VERSION "HNNBNNNYNNNNNNNNNNNNNNNNNNNNNNNNNNNNNNNNNN/4/%%%/4/'%**4NNN///"

NS_ :

BS_:

BU_: BAP_Tester BCM Gateway_Max TSGGen3_BFS TSGGen3_FS TSGGen3_HBFS TSGGen3_HFS WLC_01_CFD

BO_ 1716 VIN_01: 8 BCM
 SG_ VIN_01_MUX M  : 0|2@1+ (1,0) [0|3] ""  Gateway_Max,TSGGen3_BFS,TSGGen3_FS,TSGGen3_HBFS,TSGGen3_HFS
 SG_ KS_Geheimnis_1 m0  : 8|8@1+ (1,0) [0|255] ""  Gateway_Max
 SG_ VIN_4 m1  : 8|8@1+ (1,0) [0|255] ""  Gateway_Max,TSGGen3_BFS,TSGGen3_FS,TSGGen3_HBFS,TSGGen3_HFS,WLC_01_CFD
 SG_ VIN_11 m2  : 8|8@1+ (1,0) [0|255] ""  Gateway_Max,TSGGen3_BFS,TSGGen3_FS,TSGGen3_HBFS,TSGGen3_HFS,WLC_01_CFD
 SG_ KS_Geheimnis_2 m0  : 16|8@1+ (1,0) [0|255] ""  Gateway_Max
 SG_ VIN_5 m1  : 16|8@1+ (1,0) [0|255] ""  Gateway_Max,TSGGen3_BFS,TSGGen3_FS,TSGGen3_HBFS,TSGGen3_HFS,WLC_01_CFD
 SG_ VIN_12 m2  : 16|8@1+ (1,0) [0|255] ""  Gateway_Max,TSGGen3_BFS,TSGGen3_FS,TSGGen3_HBFS,TSGGen3_HFS,WLC_01_CFD
 SG_ KS_Geheimnis_3 m0  : 24|8@1+ (1,0) [0|255] ""  Gateway_Max
 SG_ VIN_6 m1  : 24|8@1+ (1,0) [0|255] ""  Gateway_Max,TSGGen3_BFS,TSGGen3_FS,TSGGen3_HBFS,TSGGen3_HFS,WLC_01_CFD
 SG_ VIN_13 m2  : 24|8@1+ (1,0) [0|255] ""  Gateway_Max,TSGGen3_BFS,TSGGen3_FS,TSGGen3_HBFS,TSGGen3_HFS,WLC_01_CFD
 SG_ KS_Geheimnis_4 m0  : 32|8@1+ (1,0) [0|255] ""  Gateway_Max
 SG_ VIN_7 m1  : 32|8@1+ (1,0) [0|255] ""  Gateway_Max,TSGGen3_BFS,TSGGen3_FS,TSGGen3_HBFS,TSGGen3_HFS,WLC_01_CFD
 SG_ VIN_14 m2  : 32|8@1+ (1,0) [0|255] ""  Gateway_Max,TSGGen3_BFS,TSGGen3_FS,TSGGen3_HBFS,TSGGen3_HFS,WLC_01_CFD
 SG_ VIN_1 m0  : 40|8@1+ (1,0) [0|255] ""  Gateway_Max,TSGGen3_BFS,TSGGen3_FS,TSGGen3_HBFS,TSGGen3_HFS,WLC_01_CFD
 SG_ VIN_8 m1  : 40|8@1+ (1,0) [0|255] ""  Gateway_Max,TSGGen3_BFS,TSGGen3_FS,TSGGen3_HBFS,TSGGen3_HFS,WLC_01_CFD
 SG_ VIN_15 m2  : 40|8@1+ (1,0) [0|255] ""  Gateway_Max,TSGGen3_BFS,TSGGen3_FS,TSGGen3_HBFS,TSGGen3_HFS,WLC_01_CFD
 SG_ VIN_2 m0  : 48|8@1+ (1,0) [0|255] ""  Gateway_Max,TSGGen3_BFS,TSGGen3_FS,TSGGen3_HBFS,TSGGen3_HFS,WLC_01_CFD
 SG_ VIN_9 m1  : 48|8@1+ (1,0) [0|255] ""  Gateway_Max,TSGGen3_BFS,TSGGen3_FS,TSGGen3_HBFS,TSGGen3_HFS,WLC_01_CFD
 SG_ VIN_16 m2  : 48|8@1+ (1,0) [0|255] ""  Gateway_Max,TSGGen3_BFS,TSGGen3_FS,TSGGen3_HBFS,TSGGen3_HFS,WLC_01_CFD
 SG_ VIN_3 m0  : 56|8@1+ (1,0) [0|255] ""  Gateway_Max,TSGGen3_BFS,TSGGen3_FS,TSGGen3_HBFS,TSGGen3_HFS,WLC_01_CFD
 SG_ VIN_10 m1  : 56|8@1+ (1,0) [0|255] ""  Gateway_Max,TSGGen3_BFS,TSGGen3_FS,TSGGen3_HBFS,TSGGen3_HFS,WLC_01_CFD
 SG_ VIN_17 m2  : 56|8@1+ (1,0) [0|255] ""  Gateway_Max,TSGGen3_BFS,TSGGen3_FS,TSGGen3_HBFS,TSGGen3_HFS,WLC_01_CFD

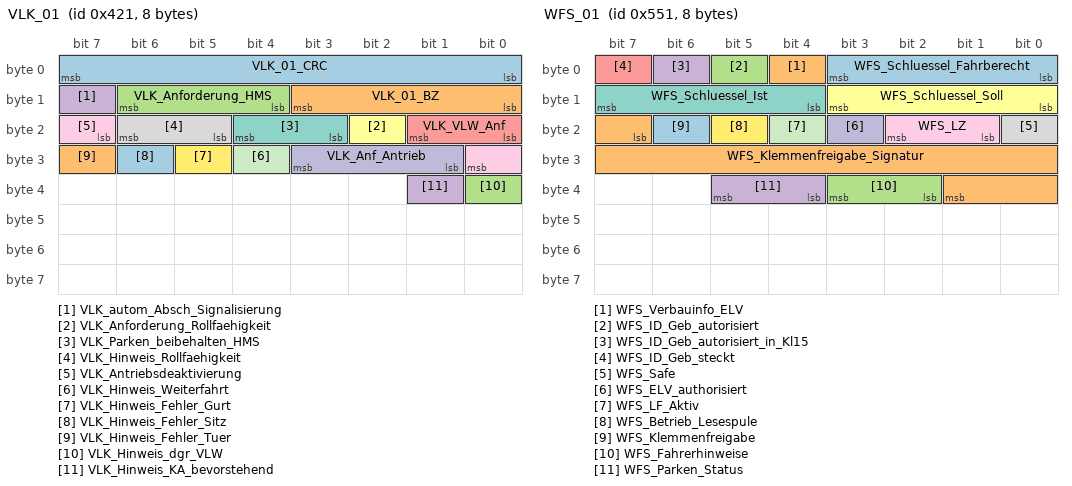
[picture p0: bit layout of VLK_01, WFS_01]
BO_ 1057 VLK_01: 8 BCM
 SG_ VLK_01_CRC : 0|8@1+ (1,0) [0|255] ""  Gateway_Max
 SG_ VLK_01_BZ : 8|4@1+ (1,0) [0|15] ""  Gateway_Max
 SG_ VLK_Anforderung_HMS : 12|3@1+ (1.0,0.0) [0.0|7] ""  Gateway_Max
 SG_ VLK_autom_Absch_Signalisierung : 15|1@1+ (1.0,0.0) [0.0|1] ""  Gateway_Max
 SG_ VLK_VLW_Anf : 16|2@1+ (1.0,0.0) [0.0|3] ""  Gateway_Max
 SG_ VLK_Anforderung_Rollfaehigkeit : 18|1@1+ (1.0,0.0) [0.0|1] ""  Gateway_Max
 SG_ VLK_Parken_beibehalten_HMS : 19|2@1+ (1.0,0.0) [0.0|3] ""  Gateway_Max
 SG_ VLK_Hinweis_Rollfaehigkeit : 21|2@1+ (1.0,0.0) [0.0|3] ""  Gateway_Max
 SG_ VLK_Antriebsdeaktivierung : 23|2@1+ (1.0,0.0) [0.0|3] ""  Gateway_Max
 SG_ VLK_Anf_Antrieb : 25|3@1+ (1.0,0.0) [0.0|7] ""  Gateway_Max
 SG_ VLK_Hinweis_Weiterfahrt : 28|1@1+ (1.0,0.0) [0.0|1] ""  Gateway_Max
 SG_ VLK_Hinweis_Fehler_Gurt : 29|1@1+ (1.0,0.0) [0.0|1] ""  Gateway_Max
 SG_ VLK_Hinweis_Fehler_Sitz : 30|1@1+ (1.0,0.0) [0.0|1] ""  Gateway_Max
 SG_ VLK_Hinweis_Fehler_Tuer : 31|1@1+ (1.0,0.0) [0.0|1] ""  Gateway_Max
 SG_ VLK_Hinweis_dgr_VLW : 32|1@1+ (1.0,0.0) [0.0|1] ""  Gateway_Max
 SG_ VLK_Hinweis_KA_bevorstehend : 33|1@1+ (1.0,0.0) [0.0|1] ""  Gateway_Max

BO_ 313 VMM_02_Auth: 32 Gateway_Max
 SG_ VMM_02_CRC : 0|8@1+ (1,0) [0|255] ""  BCM
 SG_ VMM_02_BZ : 8|4@1+ (1,0) [0|15] ""  BCM
 SG_ VZM_aktiver_Basisservice : 12|3@1+ (1.0,0.0) [0.0|7] ""  Vector__XXX
 SG_ VZM_Anhalteweg_nicht_verfuegbar : 15|1@1+ (1.0,0.0) [0.0|1] ""  Vector__XXX
 SG_ VZM_Fahrer_bremst : 16|1@1+ (1.0,0.0) [0.0|1] ""  BCM
 SG_ VZM_QBit_Fahrer_bremst : 17|1@1+ (1.0,0.0) [0.0|1] ""  BCM
 SG_ VMM_MKB_codiert : 18|1@1+ (1.0,0.0) [0.0|1] ""  Vector__XXX
 SG_ VMM_Inkonsistenz_EBKV : 19|1@1+ (1.0,0.0) [0.0|1] ""  Vector__XXX
 SG_ VMM_Notstopp_Status : 20|3@1+ (1.0,0.0) [0.0|7] ""  BCM
 SG_ VZM_Warnruck_nicht_verfuegbar : 23|1@1+ (1.0,0.0) [0.0|1] ""  Vector__XXX
 SG_ VZM_Warnruckeln_nicht_verfuegbar : 24|1@1+ (1.0,0.0) [0.0|1] ""  Vector__XXX
 SG_ VZM_Bkd_nicht_verfuegbar : 25|1@1+ (1.0,0.0) [0.0|1] ""  Vector__XXX
 SG_ VMM_Bremslicht_defekt : 26|1@1+ (1.0,0.0) [0.0|1] ""  Vector__XXX
 SG_ VZM_Fahrer_bremst_deutlich : 27|1@1+ (1.0,0.0) [0.0|1] ""  BCM
 SG_ VZM_TSK_SRBM_Anf : 28|1@1+ (1.0,0.0) [0.0|1] ""  Vector__XXX
 SG_ VZM_TSK_SRBM_nicht_verfuegbar : 29|1@1+ (1.0,0.0) [0.0|1] ""  Vector__XXX
 SG_ VZM_Verz_Reg_aktiv : 30|5@1+ (1.0,0.0) [0.0|31] ""  Vector__XXX
 SG_ VZM_Verz_Reg_nicht_verfuegbar : 35|1@1+ (1.0,0.0) [0.0|1] ""  Vector__XXX
 SG_ VMM_Inkonsistenz_KAS : 36|1@1+ (1.0,0.0) [0.0|1] ""  Vector__XXX
 SG_ VMM_Bremslicht_unplausibel : 37|1@1+ (1.0,0.0) [0.0|1] ""  Vector__XXX
 SG_ VMM_Inkonsistenz_ACC : 38|1@1+ (1.0,0.0) [0.0|1] ""  Vector__XXX
 SG_ VMM_Inkonsistenz_AWV_PCF : 39|1@1+ (1.0,0.0) [0.0|1] ""  Vector__XXX
 SG_ VMM_Inkonsistenz_ARA : 40|1@1+ (1.0,0.0) [0.0|1] ""  Vector__XXX
 SG_ VMM_Inkonsistenz_ParkAssist : 41|1@1+ (1.0,0.0) [0.0|1] ""  Vector__XXX
 SG_ VMM_Inkonsistenz_FAS_VK : 42|1@1+ (1.0,0.0) [0.0|1] ""  Vector__XXX
 SG_ VMM_Inkonsistenz_NV : 43|1@1+ (1.0,0.0) [0.0|1] ""  Vector__XXX
 SG_ VMM_Inkonsistenz_RCTA : 44|1@1+ (1.0,0.0) [0.0|1] ""  Vector__XXX
 SG_ VMM_Inkonsistenz_TSK : 45|1@1+ (1.0,0.0) [0.0|1] ""  Vector__XXX
 SG_ VMM_Inkonsistenz_MO : 46|1@1+ (1.0,0.0) [0.0|1] ""  Vector__XXX
 SG_ VMM_Inkonsistenz_AEB : 47|1@1+ (1.0,0.0) [0.0|1] ""  Vector__XXX
 SG_ VMM_Fahrer_Bremskraft_bestimmend : 48|1@1+ (1.0,0.0) [0.0|1] ""  Vector__XXX
 SG_ VMM_Inkonsistenz_EA : 49|1@1+ (1.0,0.0) [0.0|1] ""  Vector__XXX
 SG_ VZM_Status_Wegregelung : 50|2@1+ (1.0,0.0) [0.0|3] ""  Vector__XXX
 SG_ VZM_Verz_ASIL_Verfuegbarkeit : 52|3@1+ (1.0,0.0) [0.0|7] ""  Vector__XXX
 SG_ VZM_aktives_System : 55|5@1+ (1.0,0.0) [0.0|31] ""  Vector__XXX
 SG_ VZM_Verz_Begrenzung : 60|1@1+ (1.0,0.0) [0.0|1] ""  Vector__XXX
 SG_ VZM_Systemstatus : 61|3@1+ (1.0,0.0) [0.0|7] ""  Vector__XXX
 SG_ VZM_SRBM_Soll : 64|12@1+ (8,0) [0|32744] "Unit_NewtoMeter"  Vector__XXX
 SG_ VZM_SRBM_Ist : 76|12@1+ (8,0) [0|32744] "Unit_NewtoMeter"  Vector__XXX
 SG_ VZM_SRBM_max_Gradient : 88|7@1+ (50,0) [0|6250] "Unit_NewtoMeterPerSecon"  Vector__XXX
 SG_ VMM_Inkonsistenz_KAM : 95|1@1+ (1.0,0.0) [0.0|1] ""  Vector__XXX
 SG_ VMM_Inkonsistenz_RHP : 96|1@1+ (1.0,0.0) [0.0|1] ""  Vector__XXX
 SG_ HMS_P_beibehalten_GE : 172|2@1+ (1.0,0.0) [0.0|3] ""  Vector__XXX
 SG_ VZM_Unterdrueckung_Antriebsmom : 174|1@1+ (1.0,0.0) [0.0|1] ""  Vector__XXX
 SG_ VMM_Inkonsistenz_VLK : 175|1@1+ (1.0,0.0) [0.0|1] ""  BCM
 SG_ HMS_halten_nicht_verfuegbar_02 : 176|2@1+ (1.0,0.0) [0.0|3] ""  Vector__XXX
 SG_ HMS_halten_nicht_verfuegbar : 180|1@1+ (1.0,0.0) [0.0|1] ""  Vector__XXX
 SG_ HMS_parken_nicht_verfuegbar : 192|1@1+ (1.0,0.0) [0.0|1] ""  BCM
 SG_ HMS_Anforderung_GE : 193|3@1+ (1.0,0.0) [0.0|7] ""  Vector__XXX
 SG_ HMS_Systemstatus : 196|4@1+ (1.0,0.0) [0.0|15] ""  BCM
 SG_ HMS_Stillstand : 200|3@1+ (1.0,0.0) [0.0|7] ""  BCM
 SG_ HMS_aktives_System : 203|5@1+ (1.0,0.0) [0.0|31] ""  BCM
 SG_ VMM_Inkonsistenz_GE : 208|1@1+ (1.0,0.0) [0.0|1] ""  Vector__XXX
 SG_ VMM_Inkonsistenz_HVLM : 209|1@1+ (1.0,0.0) [0.0|1] ""  Vector__XXX
 SG_ HMS_Fehlerstatus : 210|3@1+ (1.0,0.0) [0.0|7] ""  Vector__XXX
 SG_ HMS_Index_Haltemoment : 213|1@1+ (1.0,0.0) [0.0|1] ""  Vector__XXX
 SG_ HMS_Haltemoment : 214|10@1+ (10,0) [0|10210] "Unit_NewtoMeter"  Vector__XXX
 SG_ SOK_VMM_02_Signatur : 224|32@1+ (1,0) [0|4294967295] ""  Vector__XXX

BO_ 916 WBA_03: 8 Gateway_Max
 SG_ WBA_03_CRC : 0|8@1+ (1,0) [0|255] ""  BCM
 SG_ WBA_03_BZ : 8|4@1+ (1,0) [0|15] ""  BCM
 SG_ WBA_Fahrstufe_02 : 12|4@1+ (1.0,0.0) [0.0|15] ""  BCM
 SG_ WBA_ZielFahrstufe : 16|4@1+ (1.0,0.0) [0.0|15] ""  BCM
 SG_ WBA_GE_Warnung_02 : 20|4@1+ (1.0,0.0) [0.0|15] ""  BCM
 SG_ WBA_eing_Gang_02 : 24|4@1+ (1.0,0.0) [0.0|15] ""  BCM
 SG_ WBA_GE_Texte : 28|3@1+ (1.0,0.0) [0.0|7] ""  BCM
 SG_ WBA_Segeln_aktiv : 31|1@1+ (1.0,0.0) [0.0|1] ""  BCM
 SG_ WBA_Schaltschema_02 : 32|3@1+ (1.0,0.0) [0.0|7] ""  BCM
 SG_ WBA_Schaltschema_FS_inaktiv : 35|2@1+ (1.0,0.0) [0.0|3] ""  BCM
 SG_ WBA_GE_Zusatzwarnungen : 37|3@1+ (1.0,0.0) [0.0|7] ""  BCM
 SG_ GE_Sollgang : 40|4@1+ (1.0,0.0) [0.0|15] ""  BCM
 SG_ GE_Tipschaltempf_verfuegbar : 44|1@1+ (1.0,0.0) [0.0|1] ""  BCM
 SG_ WBA_GE_Texte_02 : 45|3@1+ (1.0,0.0) [0.0|7] ""  BCM
 SG_ WBA_Schaltschema_Tippgasse : 48|1@1+ (1.0,0.0) [0.0|1] ""  BCM
 SG_ WBA_Schaltschema_Fahreraktion : 49|1@1+ (1.0,0.0) [0.0|1] ""  BCM
 SG_ WBA_Schaltschema_FS_vorwaerts : 50|2@1+ (1.0,0.0) [0.0|3] ""  BCM
 SG_ WBA_Shiftlock_Lampe : 52|1@1+ (1.0,0.0) [0.0|1] ""  BCM
 SG_ WBA_Anforderung_Akustik : 53|1@1+ (1.0,0.0) [0.0|1] ""  BCM
 SG_ WBA_Blinken : 54|1@1+ (1.0,0.0) [0.0|1] ""  BCM
 SG_ GE_Wiederstart_Anz_Std : 55|1@1+ (1.0,0.0) [0.0|1] ""  BCM
 SG_ GE_Stoppverbot_Anz_01 : 56|1@1+ (1.0,0.0) [0.0|1] ""  BCM
 SG_ GE_Stoppverbot_Anz_02 : 57|1@1+ (1.0,0.0) [0.0|1] ""  BCM
 SG_ GE_Stoppverbot_Anz_03 : 58|1@1+ (1.0,0.0) [0.0|1] ""  BCM
 SG_ GE_Stoppverbot_Anz_04 : 59|1@1+ (1.0,0.0) [0.0|1] ""  BCM
 SG_ GE_Stoppverbot_Anz_05 : 60|1@1+ (1.0,0.0) [0.0|1] ""  BCM
 SG_ GE_Stoppverbot_Anz_06 : 61|1@1+ (1.0,0.0) [0.0|1] ""  BCM
 SG_ GE_Stoppverbot_Anz_07 : 62|1@1+ (1.0,0.0) [0.0|1] ""  BCM
 SG_ GE_Stoppverbot_Anz_Std : 63|1@1+ (1.0,0.0) [0.0|1] ""  BCM

BO_ 1361 WFS_01: 8 BCM
 SG_ WFS_Schluessel_Fahrberecht : 0|4@1+ (1.0,0.0) [0.0|15] ""  Gateway_Max
 SG_ WFS_Verbauinfo_ELV : 4|1@1+ (1.0,0.0) [0.0|1] ""  Gateway_Max
 SG_ WFS_ID_Geb_autorisiert : 5|1@1+ (1.0,0.0) [0.0|1] ""  Gateway_Max
 SG_ WFS_ID_Geb_autorisiert_in_Kl15 : 6|1@1+ (1.0,0.0) [0.0|1] ""  Gateway_Max
 SG_ WFS_ID_Geb_steckt : 7|1@1+ (1.0,0.0) [0.0|1] ""  Gateway_Max
 SG_ WFS_Schluessel_Soll : 8|4@1+ (1,0) [0|8] "Unit_None"  Gateway_Max
 SG_ WFS_Schluessel_Ist : 12|4@1+ (1,0) [0|8] "Unit_None"  Gateway_Max
 SG_ WFS_Safe : 16|1@1+ (1.0,0.0) [0.0|1] ""  Gateway_Max
 SG_ WFS_LZ : 17|2@1+ (1.0,0.0) [0.0|3] ""  Gateway_Max
 SG_ WFS_ELV_authorisiert : 19|1@1+ (1.0,0.0) [0.0|1] ""  Gateway_Max
 SG_ WFS_LF_Aktiv : 20|1@1+ (1.0,0.0) [0.0|1] ""  Gateway_Max
 SG_ WFS_Betrieb_Lesespule : 21|1@1+ (1.0,0.0) [0.0|1] ""  Gateway_Max
 SG_ WFS_Klemmenfreigabe : 22|1@1+ (1.0,0.0) [0.0|1] ""  Gateway_Max
 SG_ WFS_Klemmenfreigabe_Signatur : 23|11@1+ (1,0) [0|2047] ""  Gateway_Max
 SG_ WFS_Fahrerhinweise : 34|2@1+ (1.0,0.0) [0.0|3] ""  Gateway_Max
 SG_ WFS_Parken_Status : 36|2@1+ (1.0,0.0) [0.0|3] ""  Gateway_Max

BO_ 1369 WFS_01_SOK_Signatur: 8 BCM
 SG_ SOK_WFS01_Signatur : 0|64@1+ (1,0) [1|18446744073709551615] "Unit_None"  Gateway_Max

BO_ 34 WFS_Transponder_Req_02: 8 BCM
 SG_ WFS_Transponder_Req_02_Data : 0|64@1+ (1,0) [0|18446744073709551615] "Unit_None"  Gateway_Max

BO_ 35 WFS_Transponder_Resp_02: 8 Gateway_Max
 SG_ WFS_Transponder_Resp_02_Data : 0|64@1+ (1,0) [0|18446744073709551615] "Unit_None"  BCM

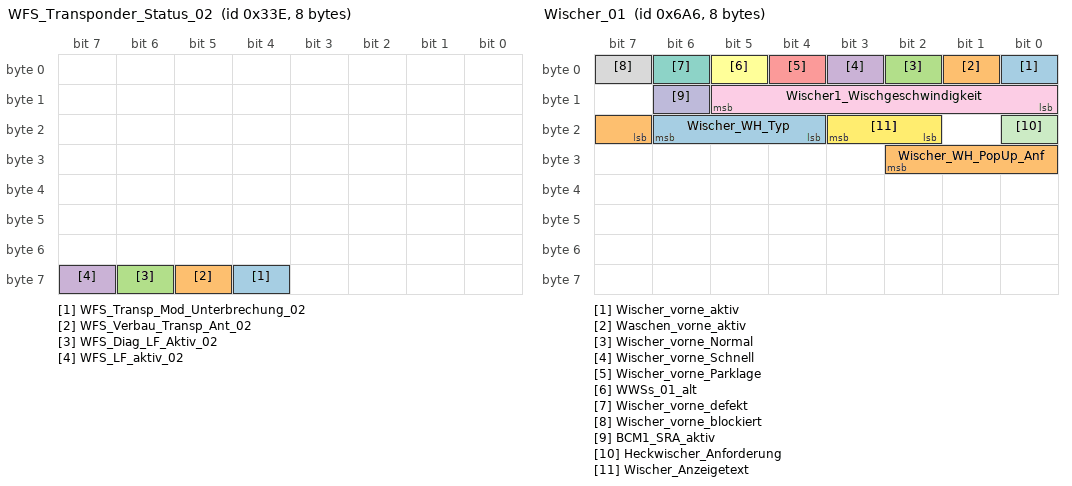
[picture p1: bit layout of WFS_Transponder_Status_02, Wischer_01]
BO_ 830 WFS_Transponder_Status_02: 8 Gateway_Max
 SG_ WFS_Transp_Mod_Unterbrechung_02 : 60|1@1+ (1.0,0.0) [0.0|1] ""  BCM
 SG_ WFS_Verbau_Transp_Ant_02 : 61|1@1+ (1.0,0.0) [0.0|1] ""  BCM
 SG_ WFS_Diag_LF_Aktiv_02 : 62|1@1+ (1.0,0.0) [0.0|1] ""  BCM
 SG_ WFS_LF_aktiv_02 : 63|1@1+ (1.0,0.0) [0.0|1] ""  BCM

BO_ 1702 Wischer_01: 8 BCM
 SG_ Wischer_vorne_aktiv : 0|1@1+ (1.0,0.0) [0.0|1] ""  Gateway_Max,TSGGen3_BFS,TSGGen3_FS,TSGGen3_HBFS,TSGGen3_HFS
 SG_ Waschen_vorne_aktiv : 1|1@1+ (1.0,0.0) [0.0|1] ""  Gateway_Max,TSGGen3_BFS,TSGGen3_FS,TSGGen3_HBFS,TSGGen3_HFS
 SG_ Wischer_vorne_Normal : 2|1@1+ (1.0,0.0) [0.0|1] ""  Gateway_Max
 SG_ Wischer_vorne_Schnell : 3|1@1+ (1.0,0.0) [0.0|1] ""  Gateway_Max
 SG_ Wischer_vorne_Parklage : 4|1@1+ (1.0,0.0) [0.0|1] ""  Gateway_Max
 SG_ WWSs_01_alt : 5|1@1+ (1.0,0.0) [0.0|1] ""  Gateway_Max
 SG_ Wischer_vorne_defekt : 6|1@1+ (1.0,0.0) [0.0|1] ""  Gateway_Max
 SG_ Wischer_vorne_blockiert : 7|1@1+ (1.0,0.0) [0.0|1] ""  Gateway_Max
 SG_ Wischer1_Wischgeschwindigkeit : 8|6@1+ (1,9) [10|70] "Unit_MinutInver"  Gateway_Max
 SG_ BCM1_SRA_aktiv : 14|1@1+ (1.0,0.0) [0.0|1] ""  Gateway_Max
 SG_ Heckwischer_Anforderung : 16|1@1+ (1.0,0.0) [0.0|1] ""  Gateway_Max
 SG_ Wischer_Anzeigetext : 18|2@1+ (1.0,0.0) [0.0|3] ""  Gateway_Max
 SG_ Wischer_WH_Typ : 20|3@1+ (1.0,0.0) [0.0|7] ""  Gateway_Max
 SG_ Wischer_WH_PopUp_Anf : 23|4@1+ (1.0,0.0) [0.0|15] ""  Gateway_Max

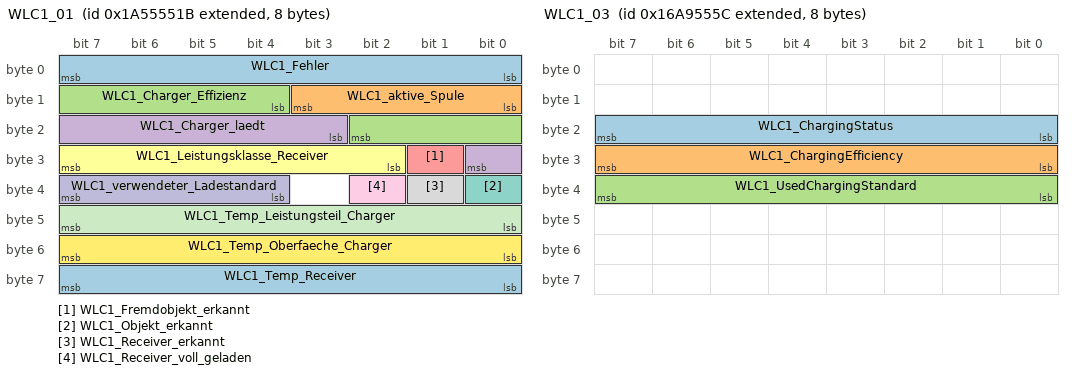
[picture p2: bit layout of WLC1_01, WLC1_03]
BO_ 2589283611 WLC1_01: 8 Gateway_Max
 SG_ WLC1_Fehler : 0|8@1+ (1.0,0.0) [0.0|255] ""  Gateway_Max
 SG_ WLC1_aktive_Spule : 8|4@1+ (1,0) [0|10] ""  BCM,Gateway_Max
 SG_ WLC1_Charger_Effizienz : 12|7@1+ (1,0) [0|100] "Unit_PerCent"  Gateway_Max
 SG_ WLC1_Charger_laedt : 19|6@1+ (0.1,0) [0.0|5.0] "Unit_Watt"  Gateway_Max
 SG_ WLC1_Fremdobjekt_erkannt : 25|1@1+ (1.0,0.0) [0.0|1] ""  BCM,Gateway_Max
 SG_ WLC1_Leistungsklasse_Receiver : 26|6@1+ (0.1,0) [0.0|5.0] "Unit_Watt"  Gateway_Max
 SG_ WLC1_Objekt_erkannt : 32|1@1+ (1.0,0.0) [0.0|1] ""  BCM,Gateway_Max
 SG_ WLC1_Receiver_erkannt : 33|1@1+ (1.0,0.0) [0.0|1] ""  BCM,Gateway_Max
 SG_ WLC1_Receiver_voll_geladen : 34|1@1+ (1.0,0.0) [0.0|1] ""  BCM,Gateway_Max
 SG_ WLC1_verwendeter_Ladestandard : 36|4@1+ (1,0) [0|15] ""  Gateway_Max
 SG_ WLC1_Temp_Leistungsteil_Charger : 40|8@1+ (1,-58) [-58|120] "Unit_DegreCelsi"  Gateway_Max
 SG_ WLC1_Temp_Oberfaeche_Charger : 48|8@1+ (1,-58) [-58|120] "Unit_DegreCelsi"  Gateway_Max
 SG_ WLC1_Temp_Receiver : 56|8@1+ (1,-58) [-58|120] "Unit_DegreCelsi"  Gateway_Max

BO_ 2527679836 WLC1_03: 8 Gateway_Max
 SG_ WLC1_ChargingStatus : 16|8@1+ (1.0,0.0) [0.0|255] ""  Gateway_Max
 SG_ WLC1_ChargingEfficiency : 24|8@1+ (1,0) [0|100] "Unit_PerCent"  Gateway_Max
 SG_ WLC1_UsedChargingStandard : 32|8@1+ (1.0,0.0) [0.0|255] ""  Gateway_Max

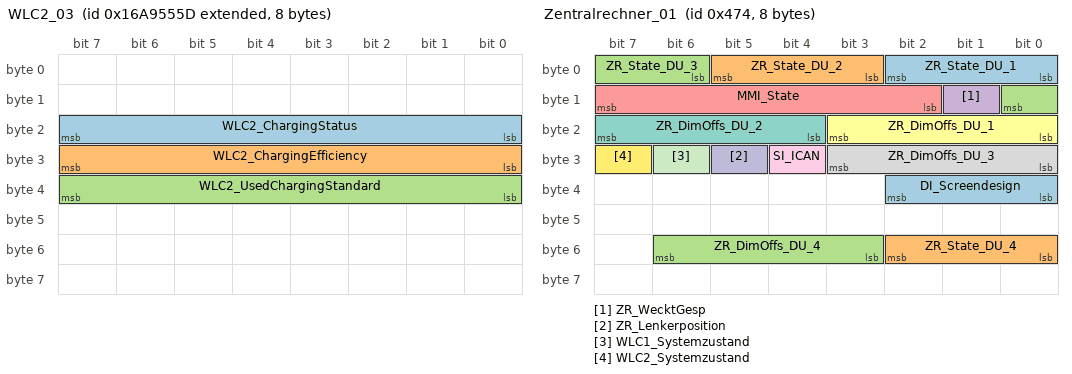
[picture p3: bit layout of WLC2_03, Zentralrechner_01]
BO_ 2527679837 WLC2_03: 8 WLC_01_CFD
 SG_ WLC2_ChargingStatus : 16|8@1+ (1.0,0.0) [0.0|255] ""  Gateway_Max
 SG_ WLC2_ChargingEfficiency : 24|8@1+ (1,0) [0|100] "Unit_PerCent"  Gateway_Max
 SG_ WLC2_UsedChargingStandard : 32|8@1+ (1.0,0.0) [0.0|255] ""  Gateway_Max

BO_ 2463978688 ZDML_01: 8 Gateway_Max
 SG_ zDML_L_Abblendl_2_Def : 12|1@1+ (1.0,0.0) [0.0|1] ""  Vector__XXX
 SG_ zDML_R_Abblendl_2_Def : 13|1@1+ (1.0,0.0) [0.0|1] ""  Vector__XXX
 SG_ DML_Fehlermeldung_Anf : 29|1@1+ (1.0,0.0) [0.0|1] ""  Vector__XXX
 SG_ DML_Fernlichtlampe_Anf : 30|1@1+ (1.0,0.0) [0.0|1] ""  Vector__XXX
 SG_ DML_EcoModus : 31|2@1+ (1.0,0.0) [0.0|3] ""  Vector__XXX
 SG_ DMD_Soll_TempMode_L : 33|3@1+ (1.0,0.0) [0.0|7] ""  Vector__XXX
 SG_ DMD_Soll_TempMode_R : 36|3@1+ (1.0,0.0) [0.0|7] ""  Vector__XXX
 SG_ zDML_Video_Fehler : 39|1@1+ (1.0,0.0) [0.0|1] ""  Vector__XXX
 SG_ zDML_SG_Defekt : 40|1@1+ (1.0,0.0) [0.0|1] ""  Vector__XXX
 SG_ zDML_Speicher_Fehler : 41|1@1+ (1.0,0.0) [0.0|1] ""  Vector__XXX
 SG_ zDML_Versorgung_Fehler : 42|1@1+ (1.0,0.0) [0.0|1] ""  Vector__XXX
 SG_ zDML_GMSL_R_Fehler : 43|1@1+ (1.0,0.0) [0.0|1] ""  Vector__XXX
 SG_ zDML_GMSL_L_Fehler : 44|1@1+ (1.0,0.0) [0.0|1] ""  Vector__XXX
 SG_ zDML_ETH_Timeout : 45|1@1+ (1.0,0.0) [0.0|1] ""  Vector__XXX
 SG_ zDML_ETH_Fehler : 46|1@1+ (1.0,0.0) [0.0|1] ""  Vector__XXX
 SG_ zDML_Fokus : 47|1@1+ (1.0,0.0) [0.0|1] ""  Vector__XXX
 SG_ zDML_Video_Anf : 48|1@1+ (1.0,0.0) [0.0|1] ""  Vector__XXX
 SG_ zDML_Status : 49|3@1+ (1.0,0.0) [0.0|7] ""  BCM
 SG_ zDML_LED_R_Anf : 52|6@1+ (1.6,0) [0.0|100.8] "Unit_PerCent"  Vector__XXX
 SG_ zDML_LED_L_Anf : 58|6@1+ (1.6,0) [0.0|100.8] "Unit_PerCent"  Vector__XXX

BO_ 2463978854 ZDML_02: 8 Gateway_Max
 SG_ DML_HMI_FCN_CROSSINGLI_AVAILABLE : 12|1@1+ (1.0,0.0) [0.0|1] ""  Vector__XXX
 SG_ DML_HMI_FCN_HAZARDWARN_AVAILABLE : 13|1@1+ (1.0,0.0) [0.0|1] ""  Vector__XXX
 SG_ DML_HMI_FCN_LANELIGHT_AVAILABLE : 14|1@1+ (1.0,0.0) [0.0|1] ""  Vector__XXX
 SG_ DML_HMI_FCN_LANLEAVELI_AVAILABLE : 15|1@1+ (1.0,0.0) [0.0|1] ""  Vector__XXX
 SG_ DML_HMI_FCN_MALI_AVAILABLE : 16|1@1+ (1.0,0.0) [0.0|1] ""  Vector__XXX
 SG_ DML_HMI_FCN_ORLI_AVAILABLE : 17|1@1+ (1.0,0.0) [0.0|1] ""  Vector__XXX
 SG_ DML_HMI_FCN_RESALLEYHI_AVAILABLE : 18|1@1+ (1.0,0.0) [0.0|1] ""  Vector__XXX
 SG_ DML_HMI_FCN_ROADWORKLI_AVAILABLE : 19|1@1+ (1.0,0.0) [0.0|1] ""  Vector__XXX
 SG_ DML_HMI_FCN_SAFETYZONE_AVAILABLE : 20|1@1+ (1.0,0.0) [0.0|1] ""  Vector__XXX
 SG_ DML_HMI_FCN_TURNLIGHPR_AVAILABLE : 21|1@1+ (1.0,0.0) [0.0|1] ""  Vector__XXX
 SG_ DML_CrossingAssist_Available : 22|1@1+ (1.0,0.0) [0.0|1] ""  BCM
 SG_ DML_HazardWarning_Available : 23|1@1+ (1.0,0.0) [0.0|1] ""  BCM
 SG_ DML_LaneLight_Available : 24|1@1+ (1.0,0.0) [0.0|1] ""  BCM
 SG_ DML_LaneDepartureWarn_Available : 25|1@1+ (1.0,0.0) [0.0|1] ""  BCM
 SG_ DML_MarkingLight_Available : 26|1@1+ (1.0,0.0) [0.0|1] ""  BCM
 SG_ DML_OrientationLight_Available : 27|1@1+ (1.0,0.0) [0.0|1] ""  BCM
 SG_ DML_RescueLaneNotice_Available : 28|1@1+ (1.0,0.0) [0.0|1] ""  BCM
 SG_ DML_ConstructionZone_Available : 29|1@1+ (1.0,0.0) [0.0|1] ""  BCM
 SG_ DML_SafetyZone_Available : 30|1@1+ (1.0,0.0) [0.0|1] ""  BCM
 SG_ DML_Indicator_Available : 31|1@1+ (1.0,0.0) [0.0|1] ""  BCM
 SG_ DML_SideAssist_Available : 32|1@1+ (1.0,0.0) [0.0|1] ""  BCM
 SG_ DML_SaftyDistance_Available : 33|1@1+ (1.0,0.0) [0.0|1] ""  BCM
 SG_ DML_GhostDriverWarn_Available : 34|1@1+ (1.0,0.0) [0.0|1] ""  BCM
 SG_ DML_IntelligentHB_Available : 35|1@1+ (1.0,0.0) [0.0|1] ""  BCM
 SG_ DML_GlarefreeHB_Available : 36|1@1+ (1.0,0.0) [0.0|1] ""  BCM
 SG_ DML_FuliValid : 37|1@1+ (1.0,0.0) [0.0|1] ""  BCM

BO_ 1140 Zentralrechner_01: 8 Gateway_Max
 SG_ ZR_State_DU_1 : 0|3@1+ (1.0,0.0) [0.0|7] ""  BCM
 SG_ ZR_State_DU_2 : 3|3@1+ (1.0,0.0) [0.0|7] ""  BCM
 SG_ ZR_State_DU_3 : 6|3@1+ (1.0,0.0) [0.0|7] ""  BCM
 SG_ ZR_WecktGesp : 9|1@1+ (1.0,0.0) [0.0|1] ""  BCM
 SG_ MMI_State : 10|6@1+ (1.0,0.0) [0.0|63] ""  BCM
 SG_ ZR_DimOffs_DU_1 : 16|4@1+ (1,-5) [-5|5] "Unit_None"  BCM
 SG_ ZR_DimOffs_DU_2 : 20|4@1+ (1,-5) [-5|5] "Unit_None"  BCM
 SG_ ZR_DimOffs_DU_3 : 24|4@1+ (1,-5) [-5|5] "Unit_None"  BCM
 SG_ SI_ICAN : 28|1@1+ (1.0,0.0) [0.0|1] ""  BCM
 SG_ ZR_Lenkerposition : 29|1@1+ (1.0,0.0) [0.0|1] ""  BCM
 SG_ WLC1_Systemzustand : 30|1@1+ (1.0,0.0) [0.0|1] ""  BCM,WLC_01_CFD
 SG_ WLC2_Systemzustand : 31|1@1+ (1.0,0.0) [0.0|1] ""  BCM,WLC_01_CFD
 SG_ DI_Screendesign : 32|3@1+ (1.0,0.0) [0.0|7] ""  BCM
 SG_ ZR_State_DU_4 : 48|3@1+ (1.0,0.0) [0.0|7] ""  BCM
 SG_ ZR_DimOffs_DU_4 : 51|4@1+ (1,-5) [-5|5] "Unit_None"  BCM

BO_ 2589284130 Zentralrechner_06: 8 Gateway_Max
 SG_ ZR_ORU_Status : 12|3@1+ (1.0,0.0) [0.0|7] ""  BCM

BO_ 389 ZFH_01: 8 TSGGen3_FS
 SG_ ZFH_FS_ManHoch : 0|1@1+ (1.0,0.0) [0.0|1] ""  TSGGen3_FS
 SG_ ZFH_FS_AutoHoch : 1|1@1+ (1.0,0.0) [0.0|1] ""  TSGGen3_FS
 SG_ ZFH_FS_ManTief : 2|1@1+ (1.0,0.0) [0.0|1] ""  TSGGen3_FS
 SG_ ZFH_FS_AutoTief : 3|1@1+ (1.0,0.0) [0.0|1] ""  TSGGen3_FS
 SG_ ZFH_BFS_ManHoch : 4|1@1+ (1.0,0.0) [0.0|1] ""  TSGGen3_BFS
 SG_ ZFH_BFS_AutoHoch : 5|1@1+ (1.0,0.0) [0.0|1] ""  TSGGen3_BFS
 SG_ ZFH_BFS_ManTief : 6|1@1+ (1.0,0.0) [0.0|1] ""  TSGGen3_BFS
 SG_ ZFH_BFS_AutoTief : 7|1@1+ (1.0,0.0) [0.0|1] ""  TSGGen3_BFS
 SG_ ZFH_HFS_ManHoch : 8|1@1+ (1.0,0.0) [0.0|1] ""  TSGGen3_HFS
 SG_ ZFH_HFS_AutoHoch : 9|1@1+ (1.0,0.0) [0.0|1] ""  TSGGen3_HFS
 SG_ ZFH_HFS_ManTief : 10|1@1+ (1.0,0.0) [0.0|1] ""  TSGGen3_HFS
 SG_ ZFH_HFS_AutoTief : 11|1@1+ (1.0,0.0) [0.0|1] ""  TSGGen3_HFS
 SG_ ZFH_HBFS_ManHoch : 12|1@1+ (1.0,0.0) [0.0|1] ""  TSGGen3_BFS,TSGGen3_HBFS
 SG_ ZFH_HBFS_AutoHoch : 13|1@1+ (1.0,0.0) [0.0|1] ""  TSGGen3_BFS,TSGGen3_HBFS
 SG_ ZFH_HBFS_ManTief : 14|1@1+ (1.0,0.0) [0.0|1] ""  TSGGen3_BFS,TSGGen3_HBFS
 SG_ ZFH_HBFS_AutoTief : 15|1@1+ (1.0,0.0) [0.0|1] ""  TSGGen3_BFS,TSGGen3_HBFS
 SG_ ZFH_zentral_zu : 28|1@1+ (1.0,0.0) [0.0|1] ""  TSGGen3_BFS,TSGGen3_FS,TSGGen3_HBFS,TSGGen3_HFS
 SG_ ZFH_zentral_auf : 29|1@1+ (1.0,0.0) [0.0|1] ""  TSGGen3_BFS,TSGGen3_FS,TSGGen3_HBFS,TSGGen3_HFS
 SG_ Krypt_Signatur : 48|11@1+ (1,0) [0|2047] ""  TSGGen3_BFS,TSGGen3_HBFS,TSGGen3_HFS
 SG_ Krypt_Schluesselschalter_auf : 59|1@1+ (1.0,0.0) [0.0|1] ""  TSGGen3_BFS,TSGGen3_HBFS,TSGGen3_HFS
 SG_ Krypt_Schluesselschalter_zu : 60|1@1+ (1.0,0.0) [0.0|1] ""  TSGGen3_BFS,TSGGen3_HBFS,TSGGen3_HFS

BO_ 388 ZV_01: 8 BCM
 SG_ ZV_01_CRC : 0|8@1+ (1,0) [0|255] ""  Gateway_Max
 SG_ ZV_01_BZ : 8|4@1+ (1,0) [0|15] ""  Gateway_Max
 SG_ ZV_FT_verriegeln : 12|1@1+ (1.0,0.0) [0.0|1] ""  Gateway_Max,TSGGen3_FS
 SG_ ZV_FT_entriegeln : 13|1@1+ (1.0,0.0) [0.0|1] ""  Gateway_Max,TSGGen3_FS
 SG_ ZV_BT_verriegeln : 14|1@1+ (1.0,0.0) [0.0|1] ""  Gateway_Max,TSGGen3_BFS
 SG_ ZV_BT_entriegeln : 15|1@1+ (1.0,0.0) [0.0|1] ""  Gateway_Max,TSGGen3_BFS
 SG_ ZV_HFS_verriegeln : 16|1@1+ (1.0,0.0) [0.0|1] ""  Gateway_Max,TSGGen3_HFS
 SG_ ZV_HFS_entriegeln : 17|1@1+ (1.0,0.0) [0.0|1] ""  Gateway_Max,TSGGen3_HFS
 SG_ ZV_HBFS_verriegeln : 18|1@1+ (1.0,0.0) [0.0|1] ""  Gateway_Max,TSGGen3_HBFS
 SG_ ZV_HBFS_entriegeln : 19|1@1+ (1.0,0.0) [0.0|1] ""  Gateway_Max,TSGGen3_HBFS
 SG_ ZV_zentral_safen : 20|1@1+ (1.0,0.0) [0.0|1] ""  Gateway_Max,TSGGen3_BFS,TSGGen3_FS,TSGGen3_HBFS,TSGGen3_HFS
 SG_ ZV_zentral_entsafen : 21|1@1+ (1.0,0.0) [0.0|1] ""  Gateway_Max,TSGGen3_BFS,TSGGen3_FS,TSGGen3_HBFS,TSGGen3_HFS
 SG_ ZV_Spg_Anklappen : 22|1@1+ (1.0,0.0) [0.0|1] ""  Gateway_Max,TSGGen3_BFS,TSGGen3_FS
 SG_ ZV_Softtouch_betaetigt : 23|1@1+ (1.0,0.0) [0.0|1] ""  Gateway_Max,TSGGen3_BFS,TSGGen3_FS,TSGGen3_HBFS,TSGGen3_HFS
 SG_ ZV_LED_Steuerung : 24|1@1+ (1.0,0.0) [0.0|1] ""  Gateway_Max,TSGGen3_FS
 SG_ ZV_LED_Uebernahme : 25|1@1+ (1.0,0.0) [0.0|1] ""  Gateway_Max,TSGGen3_FS
 SG_ ZV_auf_FT : 26|1@1+ (1.0,0.0) [0.0|1] ""  Gateway_Max
 SG_ ZV_zu_FT : 27|1@1+ (1.0,0.0) [0.0|1] ""  Gateway_Max
 SG_ ZV_auf_BT : 28|1@1+ (1.0,0.0) [0.0|1] ""  Gateway_Max
 SG_ ZV_zu_BT : 29|1@1+ (1.0,0.0) [0.0|1] ""  Gateway_Max
 SG_ ZV_auf_Kessy : 30|1@1+ (1.0,0.0) [0.0|1] ""  Gateway_Max
 SG_ ZV_zu_Kessy : 31|1@1+ (1.0,0.0) [0.0|1] ""  Gateway_Max
 SG_ ZV_auf_Funk : 32|1@1+ (1.0,0.0) [0.0|1] ""  Gateway_Max
 SG_ ZV_zu_Funk : 33|1@1+ (1.0,0.0) [0.0|1] ""  Gateway_Max
 SG_ VIP_Sensor_betaetigt : 34|1@1+ (1.0,0.0) [0.0|1] ""  Gateway_Max
 SG_ VIP_Freigabe : 35|1@1+ (1.0,0.0) [0.0|1] ""  Gateway_Max
 SG_ ZV_zu_Zeitl_Nachverr : 36|1@1+ (1.0,0.0) [0.0|1] ""  Gateway_Max,TSGGen3_BFS,TSGGen3_FS,TSGGen3_HBFS,TSGGen3_HFS
 SG_ ZV_HSK_entriegeln : 37|1@1+ (1.0,0.0) [0.0|1] ""  Gateway_Max
 SG_ ZV_HSK_verriegeln : 38|1@1+ (1.0,0.0) [0.0|1] ""  Gateway_Max
 SG_ ZV_Verdeck_zu : 39|1@1+ (1.0,0.0) [0.0|1] ""  Gateway_Max
 SG_ ZV_Verdeck_auf : 40|1@1+ (1.0,0.0) [0.0|1] ""  Gateway_Max
 SG_ FH_FT_hoch : 41|1@1+ (1.0,0.0) [0.0|1] ""  Gateway_Max,TSGGen3_FS
 SG_ FH_FT_tief : 42|1@1+ (1.0,0.0) [0.0|1] ""  Gateway_Max,TSGGen3_FS
 SG_ FH_BT_hoch : 43|1@1+ (1.0,0.0) [0.0|1] ""  Gateway_Max,TSGGen3_BFS
 SG_ FH_BT_tief : 44|1@1+ (1.0,0.0) [0.0|1] ""  Gateway_Max,TSGGen3_BFS
 SG_ FH_HFS_hoch : 45|1@1+ (1.0,0.0) [0.0|1] ""  Gateway_Max,TSGGen3_FS,TSGGen3_HFS
 SG_ FH_HFS_tief : 46|1@1+ (1.0,0.0) [0.0|1] ""  Gateway_Max,TSGGen3_FS,TSGGen3_HFS
 SG_ FH_HBFS_hoch : 47|1@1+ (1.0,0.0) [0.0|1] ""  Gateway_Max,TSGGen3_BFS,TSGGen3_HBFS
 SG_ FH_HBFS_tief : 48|1@1+ (1.0,0.0) [0.0|1] ""  Gateway_Max,TSGGen3_BFS,TSGGen3_HBFS
 SG_ BCM_Spg_Synchron : 49|1@1+ (1.0,0.0) [0.0|1] ""  Gateway_Max,TSGGen3_BFS,TSGGen3_FS
 SG_ BCM_BF_Spg_Absenkung : 50|1@1+ (1.0,0.0) [0.0|1] ""  Gateway_Max,TSGGen3_BFS,TSGGen3_FS
 SG_ ZV_Signatur : 51|11@1+ (1,0) [0|2047] ""  Gateway_Max,TSGGen3_BFS,TSGGen3_FS,TSGGen3_HBFS,TSGGen3_HFS
 SG_ ZV_entriegeln_Anf : 62|1@1+ (1.0,0.0) [0.0|1] ""  Gateway_Max
 SG_ ZV_auto_Ansteuerung : 63|1@1+ (1.0,0.0) [0.0|1] ""  Gateway_Max,TSGGen3_BFS,TSGGen3_FS,TSGGen3_HBFS,TSGGen3_HFS

BO_ 1411 ZV_02: 8 BCM
 SG_ ZV_verriegeln_Anf : 0|1@1+ (1.0,0.0) [0.0|1] ""  Gateway_Max
 SG_ ZV_STSG_HFS_Anf : 1|1@1+ (1.0,0.0) [0.0|1] ""  Gateway_Max
 SG_ ZV_STSG_HBFS_Anf : 2|1@1+ (1.0,0.0) [0.0|1] ""  Gateway_Max
 SG_ ZV_Anf_Challenge_Auth : 3|1@1+ (1.0,0.0) [0.0|1] ""  Gateway_Max
 SG_ ZV_STSG_Crashzustand : 4|1@1+ (1.0,0.0) [0.0|1] ""  Gateway_Max
 SG_ ZV_STSG_eKiSi_defekt : 5|1@1+ (1.0,0.0) [0.0|1] ""  Gateway_Max
 SG_ ZV_eRWK_Umfeld_Pruefung : 6|1@1+ (1.0,0.0) [0.0|1] ""  Gateway_Max
 SG_ VIP_Sensor_STSG_HFS_betaetigt : 10|1@1+ (1.0,0.0) [0.0|1] ""  Gateway_Max
 SG_ VIP_Sensor_STSG_HBFS_betaetigt : 11|1@1+ (1.0,0.0) [0.0|1] ""  Gateway_Max
 SG_ BCM_FH_Freigabe : 12|1@1+ (1.0,0.0) [0.0|1] ""  Gateway_Max,TSGGen3_BFS,TSGGen3_FS,TSGGen3_HBFS,TSGGen3_HFS
 SG_ BCM_Komfortfkt_Freigabe : 13|1@1+ (1.0,0.0) [0.0|1] ""  Gateway_Max,TSGGen3_BFS,TSGGen3_FS,TSGGen3_HBFS,TSGGen3_HFS
 SG_ BCM_HSK_Freigabe : 14|1@1+ (1.0,0.0) [0.0|1] ""  Gateway_Max
 SG_ BCM_Verdeck_Freigabe : 15|1@1+ (1.0,0.0) [0.0|1] ""  Gateway_Max
 SG_ ZV_verriegelt_intern_ist : 16|1@1+ (1.0,0.0) [0.0|1] ""  Gateway_Max,TSGGen3_BFS,TSGGen3_FS,TSGGen3_HBFS,TSGGen3_HFS
 SG_ ZV_verriegelt_extern_ist : 17|1@1+ (1.0,0.0) [0.0|1] ""  Gateway_Max,TSGGen3_BFS,TSGGen3_FS,TSGGen3_HBFS,TSGGen3_HFS
 SG_ ZV_verriegelt_intern_soll : 18|1@1+ (1.0,0.0) [0.0|1] ""  Gateway_Max,TSGGen3_BFS,TSGGen3_FS,TSGGen3_HBFS,TSGGen3_HFS
 SG_ ZV_verriegelt_extern_soll : 19|1@1+ (1.0,0.0) [0.0|1] ""  Gateway_Max,TSGGen3_BFS,TSGGen3_FS,TSGGen3_HBFS,TSGGen3_HFS
 SG_ ZV_gesafet_extern_ist : 20|1@1+ (1.0,0.0) [0.0|1] ""  Gateway_Max,TSGGen3_BFS,TSGGen3_FS,TSGGen3_HBFS,TSGGen3_HFS
 SG_ ZV_gesafet_extern_soll : 21|1@1+ (1.0,0.0) [0.0|1] ""  Gateway_Max,TSGGen3_BFS,TSGGen3_FS,TSGGen3_HBFS,TSGGen3_HFS
 SG_ ZV_Einzeltuerentriegelung : 22|1@1+ (1.0,0.0) [0.0|1] ""  Gateway_Max,TSGGen3_BFS,TSGGen3_FS,TSGGen3_HBFS,TSGGen3_HFS
 SG_ ZV_Heckeinzelentriegelung : 23|1@1+ (1.0,0.0) [0.0|1] ""  Gateway_Max
 SG_ ZV_FT_offen : 24|1@1+ (1.0,0.0) [0.0|1] ""  Gateway_Max
 SG_ ZV_BT_offen : 25|1@1+ (1.0,0.0) [0.0|1] ""  Gateway_Max
 SG_ ZV_HFS_offen : 26|1@1+ (1.0,0.0) [0.0|1] ""  Gateway_Max,TSGGen3_FS
 SG_ ZV_HBFS_offen : 27|1@1+ (1.0,0.0) [0.0|1] ""  Gateway_Max,TSGGen3_BFS,TSGGen3_FS
 SG_ ZV_HD_offen : 28|1@1+ (1.0,0.0) [0.0|1] ""  Gateway_Max
 SG_ ZV_HS_offen : 29|1@1+ (1.0,0.0) [0.0|1] ""  Gateway_Max
 SG_ IRUE_aktiv : 30|1@1+ (1.0,0.0) [0.0|1] ""  Gateway_Max,TSGGen3_FS
 SG_ DWA_aktiv : 31|1@1+ (1.0,0.0) [0.0|1] ""  Gateway_Max
 SG_ HD_Hauptraste : 32|1@1+ (1.0,0.0) [0.0|1] ""  Gateway_Max
 SG_ HD_Vorraste : 33|1@1+ (1.0,0.0) [0.0|1] ""  Gateway_Max
 SG_ FFB_HDF_Taste : 34|1@1+ (1.0,0.0) [0.0|1] ""  Gateway_Max
 SG_ FFB_Panik_Taste : 35|1@1+ (1.0,0.0) [0.0|1] ""  Gateway_Max
 SG_ FFB_Auf_Taste : 36|1@1+ (1.0,0.0) [0.0|1] ""  Gateway_Max
 SG_ FFB_Zu_Taste : 37|1@1+ (1.0,0.0) [0.0|1] ""  Gateway_Max
 SG_ FFB_CarFinder : 38|1@1+ (1.0,0.0) [0.0|1] ""  Gateway_Max
 SG_ FFB_Komfortoeffnen : 39|1@1+ (1.0,0.0) [0.0|1] ""  Gateway_Max
 SG_ FFB_Komfortschliessen : 40|1@1+ (1.0,0.0) [0.0|1] ""  Gateway_Max
 SG_ FBS_IDG_in_Reichweite : 41|1@1+ (1.0,0.0) [0.0|1] ""  Gateway_Max
 SG_ ZV_Schluessel_Zugang : 42|4@1+ (1.0,0.0) [0.0|15] ""  Gateway_Max,TSGGen3_BFS,TSGGen3_FS,TSGGen3_HBFS,TSGGen3_HFS
 SG_ ZV_SafeFunktion_aktiv : 46|1@1+ (1.0,0.0) [0.0|1] ""  Gateway_Max
 SG_ FBS_Warn_Schluessel_Batt : 47|1@1+ (1.0,0.0) [0.0|1] ""  Gateway_Max
 SG_ ZV_Oeffnungsmodus : 48|2@1+ (1.0,0.0) [0.0|3] ""  Gateway_Max
 SG_ HFS_verriegelt : 50|1@1+ (1.0,0.0) [0.0|1] ""  Gateway_Max
 SG_ HFS_gesafet : 51|1@1+ (1.0,0.0) [0.0|1] ""  Gateway_Max
 SG_ HBFS_verriegelt : 52|1@1+ (1.0,0.0) [0.0|1] ""  Gateway_Max
 SG_ HBFS_gesafet : 53|1@1+ (1.0,0.0) [0.0|1] ""  Gateway_Max
 SG_ ZV_ist_Zustand_verfuegbar : 54|1@1+ (1.0,0.0) [0.0|1] ""  Gateway_Max
 SG_ IRUE_Taster_Fkts_LED : 55|1@1+ (1.0,0.0) [0.0|1] ""  Gateway_Max,TSGGen3_FS
 SG_ ZV_Tankklappe_offen : 56|1@1+ (1.0,0.0) [0.0|1] ""  Gateway_Max,TSGGen3_BFS,TSGGen3_FS,TSGGen3_HBFS,TSGGen3_HFS
 SG_ ZV_Rollo_auf : 57|1@1+ (1.0,0.0) [0.0|1] ""  Gateway_Max
 SG_ ZV_Rollo_zu : 58|1@1+ (1.0,0.0) [0.0|1] ""  Gateway_Max
 SG_ ZV_SAD_auf : 59|1@1+ (1.0,0.0) [0.0|1] ""  Gateway_Max
 SG_ ZV_SAD_zu : 60|1@1+ (1.0,0.0) [0.0|1] ""  Gateway_Max
 SG_ BCM_Tankklappensteller_Fehler : 61|1@1+ (1.0,0.0) [0.0|1] ""  Gateway_Max
 SG_ ZV_verriegelt_soll : 62|2@1+ (1.0,0.0) [0.0|3] ""  Gateway_Max

BO_ 708 ZV_04: 8 BCM
 SG_ ZV_04_CRC : 0|8@1+ (1,0) [0|255] ""  Gateway_Max,TSGGen3_FS
 SG_ ZV_04_BZ : 8|4@1+ (1,0) [0|15] ""  Gateway_Max,TSGGen3_FS
 SG_ ZV_HFS_Status_KiSi : 12|1@1+ (1.0,0.0) [0.0|1] ""  Gateway_Max,TSGGen3_FS
 SG_ ZV_HFS_TAG_betaetigt : 13|1@1+ (1.0,0.0) [0.0|1] ""  Gateway_Max
 SG_ ZV_HFS_TIG_oeffnen_betaetigt : 14|1@1+ (1.0,0.0) [0.0|1] ""  Gateway_Max
 SG_ ZV_HFS_TIG_schliessen_betaetigt : 15|1@1+ (1.0,0.0) [0.0|1] ""  Gateway_Max
 SG_ ZV_HBFS_Status_KiSi : 16|1@1+ (1.0,0.0) [0.0|1] ""  Gateway_Max,TSGGen3_FS
 SG_ ZV_HBFS_TAG_betaetigt : 17|1@1+ (1.0,0.0) [0.0|1] ""  Gateway_Max
 SG_ ZV_HBFS_TIG_oeffnen_betaetigt : 18|1@1+ (1.0,0.0) [0.0|1] ""  Gateway_Max
 SG_ ZV_HBFS_TIG_schliessen_betaetigt : 19|1@1+ (1.0,0.0) [0.0|1] ""  Gateway_Max
 SG_ ZV_Hupe_Takt : 41|1@1+ (1.0,0.0) [0.0|1] ""  Gateway_Max
 SG_ ZV_Hupe_Anf : 42|1@1+ (1.0,0.0) [0.0|1] ""  Gateway_Max
 SG_ ZV_Status_Cargolock : 43|1@1+ (1.0,0.0) [0.0|1] ""  Gateway_Max
 SG_ ZV_HW_TKL_mot_verr : 46|1@1+ (1.0,0.0) [0.0|1] ""  Gateway_Max
 SG_ ZV_HW_TKL_mot_entr : 47|1@1+ (1.0,0.0) [0.0|1] ""  Gateway_Max
 SG_ ZV_Status_KiSi_CargoLock : 48|3@1+ (1.0,0.0) [0.0|7] ""  Gateway_Max,TSGGen3_FS
 SG_ ZV_Laderaumabd_elektr_aktiviert : 53|1@1+ (1.0,0.0) [0.0|1] ""  Gateway_Max
 SG_ ZV_Einfachhorn_Takt : 54|1@1+ (1.0,0.0) [0.0|1] ""  Gateway_Max
 SG_ ZV_Einfachhorn_Anf : 55|1@1+ (1.0,0.0) [0.0|1] ""  Gateway_Max
 SG_ ZV_DWA_Einfachhorn_Takt : 56|1@1+ (1.0,0.0) [0.0|1] ""  Gateway_Max
 SG_ ZV_DWA_Einfachhorn_Anf : 57|1@1+ (1.0,0.0) [0.0|1] ""  Gateway_Max
 SG_ UHF_FFB_Funkschluesseltyp : 58|3@1+ (1.0,0.0) [0.0|7] ""  Gateway_Max
 SG_ UHF_FFB_SKC_anlernen : 61|1@1+ (1.0,0.0) [0.0|1] ""  Gateway_Max
 SG_ ZV_HW_Motor_Safe_Hinten : 62|1@1+ (1.0,0.0) [0.0|1] ""  Gateway_Max
 SG_ ZV_HW_Motor_Lock_HK : 63|1@1+ (1.0,0.0) [0.0|1] ""  Gateway_Max

BO_TX_BU_ 2527679836 :Gateway_Max,WLC_01_CFD;
CM_ BO_ 1716 "200ms bei D4 und folgende";
CM_ BO_ 916 "ersetzt WBA_02";
CM_ BO_ 1702 "MLBevo";
CM_ BO_ 389 "Zentraler Fensterhebertaster

ab MQB gueltig";

CM_ SG_ 1716 VIN_01_MUX "Achtung:
Die Botschaft ist nicht linear gemultiplext!!!
Sondern 0,1,0,2,0, usw.";
CM_ SG_ 1716 VIN_1 "Initwert:
0x2D bei Fahrzeugen mit Wegfahrsperrengeneration >= 5 
0x58 bei Fahrzeugen mit Wegfahrsperrengeneration < 5 (z.B. WFS-4)";
CM_ SG_ 1716 VIN_10 "Initwert:
0x2D bei Fahrzeugen mit Wegfahrsperrengeneration >= 5 
0x58 bei Fahrzeugen mit Wegfahrsperrengeneration < 5 (z.B. WFS-4)";
CM_ SG_ 1716 VIN_11 "Initwert:
0x2D bei Fahrzeugen mit Wegfahrsperrengeneration >= 5 
0x58 bei Fahrzeugen mit Wegfahrsperrengeneration < 5 (z.B. WFS-4)";
CM_ SG_ 1716 VIN_12 "Initwert:
0x2D bei Fahrzeugen mit Wegfahrsperrengeneration >= 5 
0x58 bei Fahrzeugen mit Wegfahrsperrengeneration < 5 (z.B. WFS-4)";
CM_ SG_ 1716 VIN_13 "Initwert:
0x2D bei Fahrzeugen mit Wegfahrsperrengeneration >= 5 
0x58 bei Fahrzeugen mit Wegfahrsperrengeneration < 5 (z.B. WFS-4)";
CM_ SG_ 1716 VIN_14 "Initwert:
0x2D bei Fahrzeugen mit Wegfahrsperrengeneration >= 5 
0x58 bei Fahrzeugen mit Wegfahrsperrengeneration < 5 (z.B. WFS-4)";
CM_ SG_ 1716 VIN_15 "Initwert:
0x2D bei Fahrzeugen mit Wegfahrsperrengeneration >= 5 
0x58 bei Fahrzeugen mit Wegfahrsperrengeneration < 5 (z.B. WFS-4)";
CM_ SG_ 1716 VIN_16 "Initwert:
0x2D bei Fahrzeugen mit Wegfahrsperrengeneration >= 5 
0x58 bei Fahrzeugen mit Wegfahrsperrengeneration < 5 (z.B. WFS-4)";
CM_ SG_ 1716 VIN_17 "Initwert:
0x2D bei Fahrzeugen mit Wegfahrsperrengeneration >= 5 
0x58 bei Fahrzeugen mit Wegfahrsperrengeneration < 5 (z.B. WFS-4)";
CM_ SG_ 1716 VIN_2 "Initwert:
0x2D bei Fahrzeugen mit Wegfahrsperrengeneration >= 5 
0x58 bei Fahrzeugen mit Wegfahrsperrengeneration < 5 (z.B. WFS-4)";
CM_ SG_ 1716 VIN_3 "Initwert:
0x2D bei Fahrzeugen mit Wegfahrsperrengeneration >= 5 
0x58 bei Fahrzeugen mit Wegfahrsperrengeneration < 5 (z.B. WFS-4)";
CM_ SG_ 1716 VIN_4 "Initwert:
0x2D bei Fahrzeugen mit Wegfahrsperrengeneration >= 5 
0x58 bei Fahrzeugen mit Wegfahrsperrengeneration < 5 (z.B. WFS-4)";
CM_ SG_ 1716 VIN_5 "Initwert:
0x2D bei Fahrzeugen mit Wegfahrsperrengeneration >= 5 
0x58 bei Fahrzeugen mit Wegfahrsperrengeneration < 5 (z.B. WFS-4)";
CM_ SG_ 1716 VIN_6 "Initwert:
0x2D bei Fahrzeugen mit Wegfahrsperrengeneration >= 5 
0x58 bei Fahrzeugen mit Wegfahrsperrengeneration < 5 (z.B. WFS-4)";
CM_ SG_ 1716 VIN_7 "Initwert:
0x2D bei Fahrzeugen mit Wegfahrsperrengeneration >= 5 
0x58 bei Fahrzeugen mit Wegfahrsperrengeneration < 5 (z.B. WFS-4)";
CM_ SG_ 1716 VIN_8 "Initwert:
0x2D bei Fahrzeugen mit Wegfahrsperrengeneration >= 5 
0x58 bei Fahrzeugen mit Wegfahrsperrengeneration < 5 (z.B. WFS-4)";
CM_ SG_ 1716 VIN_9 "Initwert:
0x2D bei Fahrzeugen mit Wegfahrsperrengeneration >= 5 
0x58 bei Fahrzeugen mit Wegfahrsperrengeneration < 5 (z.B. WFS-4)";

CM_ SG_ 1057 VLK_01_BZ "4bit Botschaftszähler, wird mit jeder Sendebotschaft inkrementiert";
CM_ SG_ 1057 VLK_01_CRC "Für MLB:
Berechnung siehe Lastenheft 'Kommunikationsabsicherung für FlexRay und CAN'
Ab MQB und MLBevo:
Berechnung siehe Lastenheft 'End-to-End Kommunikationsabsicherung'

Endwerte siehe Begleitdokument 'S-PDU Kennungsfolgen'";
CM_ SG_ 1057 VLK_Anf_Antrieb "Anforderung zur Antriebsfreigabe seitens VLK";
CM_ SG_ 1057 VLK_Anforderung_HMS "Halteanforderung des VLK an HMS aus Funktion Rollsicherung";
CM_ SG_ 1057 VLK_Anforderung_Rollfaehigkeit "Mit diesem Signal wird vom Verlassenskonzept signalisiert, ob der Rollfähigkeitsmodus aktiviert ist.";
CM_ SG_ 1057 VLK_Antriebsdeaktivierung "VLK kann mit diesem Signal den Antrieb deaktivieren.";
CM_ SG_ 1057 VLK_autom_Absch_Signalisierung "Signalisierung einer automatisierten Deaktivierung der Zündung";
CM_ SG_ 1057 VLK_Hinweis_dgr_VLW "Dieses Signal fordert im Kombi die Meldung an, die den Fahrer auffordert das Fahrzeug nur in Fahrstufe P zu verlassen. 
Notwendig wenn aufgrund fehlerhafter Eingangssignale keine automatische Sicherung erfolgt";
CM_ SG_ 1057 VLK_Hinweis_Fehler_Gurt "Dieses Signal fordert im Kombi die Meldung an, die den Fahrer über ein defektes Gurtschloss (Fahrergurt) informiert.";
CM_ SG_ 1057 VLK_Hinweis_Fehler_Sitz "Dieses Signal fordert im Kombi die Meldung an, die den Fahrer über eine defekte Sitzbelegungserkennung (Fahrersitz) informiert.";
CM_ SG_ 1057 VLK_Hinweis_Fehler_Tuer "Dieses Signal fordert im Kombi die Meldung an, die den Fahrer über einen defekten Türkontaktschalter (Fahrertür) informiert.";
CM_ SG_ 1057 VLK_Hinweis_KA_bevorstehend "Dieses Signal fordert im Kombi die Meldung an, die den Fahrer auf eine bevorstehende Komforabschaltung hinweist.";
CM_ SG_ 1057 VLK_Hinweis_Rollfaehigkeit "Im Signal wird die Meldungsausgabe des Rollfähigkeitsmodus im iID mit bzw. ohne Akustik angefordert";
CM_ SG_ 1057 VLK_Hinweis_Weiterfahrt "Dieses Signal fordert im Kombi die Meldung an, die den Fahrer auf eine Bedienhandlung zur Weiterfahrt hinweist.";
CM_ SG_ 1057 VLK_Parken_beibehalten_HMS "Anforderung durch das Verlassenskonzept, um das Lösen der Parkbremse zu verhindern.";
CM_ SG_ 1057 VLK_VLW_Anf "Anforderndes Signal der Verlassenswarnung für Fahrzeuge auf technischer Basis MEB. Aufgrund des nicht verbauten Getriebes sind die Signalwerte um die Ersatzreaktionen auf ein fehlerhaftes p_verriegelt reduziert. Ausgabe der Verlassenswarnung erfolgt im Fa";

CM_ SG_ 313 HMS_aktives_System "Zeigt an, von welchem System die Anforderung gerade umgesetzt wird.";
CM_ SG_ 313 HMS_Anforderung_GE "Fordert vom Getriebe bestimmte Schaltstellungen an.";
CM_ SG_ 313 HMS_Fehlerstatus "Zeigt den Fehlerstatus des Haltemanagementsystems HMS an.
Details zu den Werten 3/4:
3=Systemeinschränkung, Parken EPB oder GSG nicht möglich
4=Systemstörung bzw. Parken EPB und GSG nicht möglich  ";
CM_ SG_ 313 HMS_Haltemoment "Zeigt in Abhängigkeit von HMS_Index_Haltemoment das notwendige Summen-Radmoment an (bergab: Bremsmoment; bergauf: Antriebsmoment), das mindestens notwendig ist um das Fahrzeug an der aktuellen Neigung zu halten.";
CM_ SG_ 313 HMS_halten_nicht_verfuegbar "Rueckmeldung HMS-Teilfunktion 'Halten' nicht verfuegbar.";
CM_ SG_ 313 HMS_halten_nicht_verfuegbar_02 "Erweiterung des Signals 'HMS_halten_nicht_verfuegbar':
Für Remotevorgänge (Ein-, Ausparken, etc.) ohne anwesenden Fahrer soll das Signal eine Halteverfügbarkeit signalisieren durch 'verfuegbar_ohne_Fahrer'.";
CM_ SG_ 313 HMS_Index_Haltemoment "Zeigt an, ob das Summen-HMS_Haltemoment ein Bremsmoment (bergab) oder ein Antriebsmoment (bergauf) darstellt.";
CM_ SG_ 313 HMS_P_beibehalten_GE "Fordert das Getriebe auf in Stellung 'P' zu bleiben.";
CM_ SG_ 313 HMS_parken_nicht_verfuegbar "Rueckmeldung HMS-Teilfunktionen 'Parken' nicht verfuegbar.";
CM_ SG_ 313 HMS_Stillstand "Das Signal zeigt, basierend auf den vier ESP-Raddrehzahlinformatioen, gefiltert und/oder entprellt mehrstufig den Fahrzeuggeschwindigkeitszustand an.";
CM_ SG_ 313 HMS_Systemstatus "Zeigt den aktuellen Systemstatus des HMS an.";
CM_ SG_ 313 SOK_VMM_02_Signatur "Signatur im Rahmen der durch SOK geschützten Broadcast-Kommunikation

Geschützte Funktionen: Airbag-Funktionen, Bremsfunktionen
Geschützte Botschaft: VMM_02";
CM_ SG_ 313 VMM_02_BZ "4bit Botschaftszähler, wird mit jeder Sendebotschaft inkrementiert
Botschaft asynchron geroutet. Zählerwert kann springen.";
CM_ SG_ 313 VMM_02_CRC "Für MLB:
Berechnung siehe Lastenheft 'Kommunikationsabsicherung für FlexRay und CAN'
Ab MQB und MLBevo:
Berechnung siehe Lastenheft 'End-to-End Kommunikationsabsicherung'

Endwerte siehe Begleitdokument 'S-PDU Kennungsfolgen'";
CM_ SG_ 313 VMM_Bremslicht_defekt "Rückmeldung ob beide Bremslichter defekt sind. Bei gestecktem Anhänger werden die Anhängerbremslichter ausgewertet.";
CM_ SG_ 313 VMM_Bremslicht_unplausibel "Bremslichtplausibilität aus Basis der CAN Anforderung";
CM_ SG_ 313 VMM_Fahrer_Bremskraft_bestimmend "Dieses Signal gibt eine Rückmeldung ob der Fahrer stärker bremst als die angeforderte Bremsung.";
CM_ SG_ 313 VMM_Inkonsistenz_ACC "Rückmeldung Inkonsistenz ACC";
CM_ SG_ 313 VMM_Inkonsistenz_AEB "Rückmeldung Inkonsistenz vom AEB";
CM_ SG_ 313 VMM_Inkonsistenz_ARA "Rückmeldung Inkonsistenz ARA 1.0";
CM_ SG_ 313 VMM_Inkonsistenz_AWV_PCF "Rückmeldung Inkonsistenz AWV PCF";
CM_ SG_ 313 VMM_Inkonsistenz_EA "Rückmeldung Inkonsistenz EA";
CM_ SG_ 313 VMM_Inkonsistenz_EBKV "Rückmeldung Inkonsistenz EBKV";
CM_ SG_ 313 VMM_Inkonsistenz_FAS_VK "Rückmeldung Inkonsistenz Fahrerassistenzsystem";
CM_ SG_ 313 VMM_Inkonsistenz_GE "Zeigt an, ob die Kommunikation und die Anforderungen plausibel sind.";
CM_ SG_ 313 VMM_Inkonsistenz_HVLM "Rückmeldung Inkonsistenz HVLM";
CM_ SG_ 313 VMM_Inkonsistenz_KAM "Rückmeldung Inkonsistenz der Kamera";
CM_ SG_ 313 VMM_Inkonsistenz_KAS "Rückmeldung Inkonsistenz KAS";
CM_ SG_ 313 VMM_Inkonsistenz_MO "Rückmeldung Inkonsistenz MO";
CM_ SG_ 313 VMM_Inkonsistenz_NV "Rückmeldung Inkonsistenz Nightvision";
CM_ SG_ 313 VMM_Inkonsistenz_ParkAssist "Rückmeldung Inkonsistenz der Parkenden Systeme";
CM_ SG_ 313 VMM_Inkonsistenz_RCTA "Rückmeldung Inkonsistenz des RCTA";
CM_ SG_ 313 VMM_Inkonsistenz_RHP "Rückmeldung Inkonsistenz RHP (Rush Hour pilot).";
CM_ SG_ 313 VMM_Inkonsistenz_TSK "Rückmeldung Inkonsistenz TSK";
CM_ SG_ 313 VMM_Inkonsistenz_VLK "Rückmeldung Inkonsistenz VLK";
CM_ SG_ 313 VMM_MKB_codiert "Das Signal kennzeichnet den Codierstatus des ESC-SG bzgl. der Funktion Multikollisionsbremse.";
CM_ SG_ 313 VMM_Notstopp_Status "Status des Notstoppsystems";
CM_ SG_ 313 VZM_aktiver_Basisservice "In diesem Signal wird der aktive Basisservice des Verzögerungsmanagement zurück gegeben.";
CM_ SG_ 313 VZM_aktives_System "Rückmeldung über das  aktiv anfordernde System bei dem Verzögerungsmanagement.";
CM_ SG_ 313 VZM_Anhalteweg_nicht_verfuegbar "Rückmeldung ob die Anhaltewegregelung verfügbar ist.";
CM_ SG_ 313 VZM_Bkd_nicht_verfuegbar "Dieses Signal gibt eine Rückmeldung ob eine Bremsenkonditionierung (Prefill und Systemtotzeitminimierung) verfügbar ist.";
CM_ SG_ 313 VZM_Fahrer_bremst "Bit wird gesetzt beim Überschreiten der Bremsdruckschwelle

Weiterführende Informationen im Lastenheft spezifiziert und in der entsprechenden Fachabteilung zu erfragen.";
CM_ SG_ 313 VZM_Fahrer_bremst_deutlich "Rückmeldung an AWV ob der Fahrer das Bremspedal deutlich betätigt hat";
CM_ SG_ 313 VZM_QBit_Fahrer_bremst "Gültigkeit der Bremsdruckschwelleninformation des Signals VZM_Fahrer_bremst und VZM_Fahrer_bremst_deutlich
0x1 = Druckschwelleninformation kann noch nicht oder aufgrund eines Fehlers nicht ausgegeben werden";
CM_ SG_ 313 VZM_SRBM_Ist "Gibt das aktuelle Summenradbremsmoment aus.";
CM_ SG_ 313 VZM_SRBM_max_Gradient "Rückmeldung aktueller Maximalgradient";
CM_ SG_ 313 VZM_SRBM_Soll "Gibt das angeforderte Summenradbremsmoment aus.";
CM_ SG_ 313 VZM_Status_Wegregelung "Rückmeldung der Wegregelung ob dieser Service Inaktiv, aktiv oder passiv ist.
Bei Passiv_Überwachend Bremseingriff durch VZM im Notfall möglich.";
CM_ SG_ 313 VZM_Systemstatus "In diesem Signal wird der aktuelle Systemstatus des Verzögerungsmanagments ausgeben.";
CM_ SG_ 313 VZM_TSK_SRBM_Anf "Quittierung für TSK (SRBM = Summenradbremsmoment) Anforderung";
CM_ SG_ 313 VZM_TSK_SRBM_nicht_verfuegbar "Rückmeldung ob das ein Summenradbremsmoment angefordert werden kann.";
CM_ SG_ 313 VZM_Unterdrueckung_Antriebsmom "Mit diesem Signal wird dem TSK signalisiert ob ein positives Antriebsmoment angefordert werden kann. In einer Notbremsung ist das positive Antriebsmoment zu unterdrücken.";
CM_ SG_ 313 VZM_Verz_ASIL_Verfuegbarkeit "Dieses Signal gibt die Rückmeldung in welchem ASIL Bereich aktuell verzögert wird.";
CM_ SG_ 313 VZM_Verz_Begrenzung "Rückmeldung angeforderte Verzögerung oder Summenradbremsmoment wird begrenzt umgesetzt";
CM_ SG_ 313 VZM_Verz_Reg_aktiv "Rueckmeldung Verzoegerungsregelung aktiv";
CM_ SG_ 313 VZM_Verz_Reg_nicht_verfuegbar "In diesem Signal wird ausgegeben ob eine Verzögerungsregelung verfügbar ist.";
CM_ SG_ 313 VZM_Warnruck_nicht_verfuegbar "Rückmeldung ob ein einfacher Warnruck angefordert werden kann.";
CM_ SG_ 313 VZM_Warnruckeln_nicht_verfuegbar "Rückmeldung ob mehrfach ein Warnruck durchgeführt werden kann.";

CM_ SG_ 916 GE_Sollgang "Signalisiert den Sollgang, in den getippt werden soll. Abhängig vom Signal 'WBA_eing_Gang_02' und dem Sollgang kann dann das Kombi die Hochschaltempfehlung in Tip darstellen.";
CM_ SG_ 916 GE_Stoppverbot_Anz_01 "Dieses Signal gibt die detaillierte Begründung für ein Stoppverbot vom Getriebesteuergerät an.";
CM_ SG_ 916 GE_Stoppverbot_Anz_02 "Dieses Signal gibt die detaillierte Begründung für ein Stoppverbot vom Getriebesteuergerät an.";
CM_ SG_ 916 GE_Stoppverbot_Anz_03 "Dieses Signal gibt die detaillierte Begründung für ein Stoppverbot vom Getriebesteuergerät an.";
CM_ SG_ 916 GE_Stoppverbot_Anz_04 "Dieses Signal gibt die detaillierte Begründung für ein Stoppverbot vom Getriebesteuergerät an.";
CM_ SG_ 916 GE_Stoppverbot_Anz_05 "Dieses Signal gibt die detaillierte Begründung für ein Stoppverbot vom Getriebesteuergerät an.";
CM_ SG_ 916 GE_Stoppverbot_Anz_06 "Dieses Signal gibt die detaillierte Begründung für ein Stoppverbot vom Getriebesteuergerät an.";
CM_ SG_ 916 GE_Stoppverbot_Anz_07 "Dieses Signal gibt die detaillierte Begründung für ein Stoppverbot vom Getriebesteuergerät an.";
CM_ SG_ 916 GE_Stoppverbot_Anz_Std "Dieses Signal gibt die detaillierte Begründung für ein Stoppverbot vom Getriebesteuergerät an.";
CM_ SG_ 916 GE_Tipschaltempf_verfuegbar "Signalisierung, ob eine Hochschaltempfehlung im Tipmodus verfügbar ist oder nicht.";
CM_ SG_ 916 GE_Wiederstart_Anz_Std "Dieses Signal gibt die detaillierte Begründung für einen Wiederstart vom Getriebesteuergerät an. ";
CM_ SG_ 916 WBA_03_CRC "Für MLB:
'Berechnung siehe Lastenheft 'Kommunikationsabsicherung für FlexRay und CAN''

Ab MQB und MLBevo:
'Berechnung siehe Lastenheft 'End-to-End Kommunikationsabsicherung''

Endwerte siehe Begleitdokument 'S-PDU Kennungsfolgen'";
CM_ SG_ 916 WBA_Anforderung_Akustik "Anforderung eines Signaltons bei Anwahl der Fahrstufe R";
CM_ SG_ 916 WBA_Blinken "Dieses Bit steuert die Fehlerlampe an oder wird zum Blinken der WBA-Anzeige genutzt - nur falls WBA_Senderkennung = 00 (GSG)
";
CM_ SG_ 916 WBA_eing_Gang_02 "Das Automatikgetriebe gibt den aktuell eingelegten Gang aus.
Besonderheiten:
0x0 = marktabhängig wird auf Ganganzeige zur Fahrstufe komplett verzichtet
0xA = kurzzeitige Unterdrückung der Ganganzeige (z. B. Segeln, Zwischenstellung, etc.)";
CM_ SG_ 916 WBA_Fahrstufe_02 "Bei Automatgetrieben wird in diesem Signal die aktuelle anzuzeigende Fahrstufe ausgegeben.

Die Signalkodierungen 0x9, 0xA und 0xB werden im MSS-R8NF und MQB-A1/B/A2 verwendet.

Die Signalkodierungen 0xC und 0xD werden nur im MQB-A1/B/A2 verwendet.
";
CM_ SG_ 916 WBA_GE_Texte "Fahrerhinweise für das Kombi";
CM_ SG_ 916 WBA_GE_Texte_02 "Fahrerhinweise für das Kombi";
CM_ SG_ 916 WBA_GE_Warnung_02 "Prioritätswarnungen Getriebe";
CM_ SG_ 916 WBA_GE_Zusatzwarnungen "Prioritaetswarnungen Getriebe an Kombi
Audi MLB Wertebereich 0 bis 3
VW MQB Projekte verwenden nur den Wertebereich 0 bis 2
VW MQB Getriebefehler werden über das Signal  GE_Warnungen_02 gesendet.";
CM_ SG_ 916 WBA_Schaltschema_02 "Basis-Layout des Schaltschemas zur Anzeige im Kombiinstrument";
CM_ SG_ 916 WBA_Schaltschema_Fahreraktion "Signalisiert Fahreraktion an der Schaltbetaetigung";
CM_ SG_ 916 WBA_Schaltschema_FS_inaktiv "Gibt an, welche Fahrstufen innerhalb von WBA_Schaltschema_02 aktuell nicht erreichbar sind (z.B. aufgrund zu hoher Fahrzeuggeschwindigkeit oder fehlender Fahrbereitschaft).";
CM_ SG_ 916 WBA_Schaltschema_FS_vorwaerts "Zeigt an, welche der zwei Vorwärtsfahrstufen aktiv ist und ob in die inaktive geschaltet werden kann.";
CM_ SG_ 916 WBA_Schaltschema_Tippgasse "Zeigt den Verbau einer Tippgasse zur Anzeige im Schaltschema an.";
CM_ SG_ 916 WBA_Segeln_aktiv "Getriebe geht in den Segelbetrieb";
CM_ SG_ 916 WBA_Shiftlock_Lampe "Signalisiert dem Kombi, dass die Shiftlock-Lampe (grünes 'Bremse treten' Symbol) anzuzeigen ist.

Anmerkung: Signal ist nur von Kombis auszuwerten, die die Shiftlock-Info über Soft- oder Hard-LED und nicht als reine Textmeldung anzeigen.";
CM_ SG_ 916 WBA_ZielFahrstufe "Zielfahrprogramm (Darstellung), für getipptes S/E/M mit neuem Wählhebel im MQB";

CM_ SG_ 1361 WFS_Betrieb_Lesespule "Schlüsselkommunikation über die Lesespule";
CM_ SG_ 1361 WFS_ELV_authorisiert "Authorisierung der elektrischen Lenkungsverriegelung an der WFS";
CM_ SG_ 1361 WFS_Fahrerhinweise "Meldungen, Fahrer- und Warnhinweise der Wegfahrsperre";
CM_ SG_ 1361 WFS_ID_Geb_autorisiert "Authorisierung Schluessel (ID-Geber)";
CM_ SG_ 1361 WFS_ID_Geb_autorisiert_in_Kl15 "Authorisierung des Schlüssels im aktiven Klemme-15-Zyklus";
CM_ SG_ 1361 WFS_ID_Geb_steckt "Schluessel (ID-Geber) im Zuendschloss
";
CM_ SG_ 1361 WFS_Klemmenfreigabe "Freigabe von der WFS zum Einschalten der Klemme 15 und Klemme S";
CM_ SG_ 1361 WFS_Klemmenfreigabe_Signatur "Signatur zur Klemmenfreigabe durch die WFS";
CM_ SG_ 1361 WFS_LF_Aktiv "LF Schluesselkommunikation
";
CM_ SG_ 1361 WFS_LZ "Anforderung aus Lastenheft WFS V
";
CM_ SG_ 1361 WFS_Parken_Status "Schnittstelle zwischen WFS und ZFAS für das Pilotierte Parken um in Richtung ZFAS den Status der WFS im BCM2 zu kommunizieren";
CM_ SG_ 1361 WFS_Safe "Status WFS";
CM_ SG_ 1361 WFS_Schluessel_Fahrberecht "Schlüsselnummer Fahrberechtigung
0 = ungueltig, xxxx = Schluessel-Nr.";
CM_ SG_ 1361 WFS_Schluessel_Ist "Istwert der gelernten Schluessel";
CM_ SG_ 1361 WFS_Schluessel_Soll "Sollwert der zu lernenden Schluessel";
CM_ SG_ 1361 WFS_Verbauinfo_ELV "Info über die Konfiguration der ELV im WFS-Master";

CM_ SG_ 1369 SOK_WFS01_Signatur "Signatur im Rahmen der durch SOK geschützen Broadcast-Kommunikation

Geschützte Funktion: Car2Car
Geschützte Signale: WFS_ID_Geb_autorisiert_in_Kl15
Geschützte Botschaft: WFS_01";

CM_ SG_ 34 WFS_Transponder_Req_02_Data "Transponderdaten von WFS-Master an Kombi senden";

CM_ SG_ 35 WFS_Transponder_Resp_02_Data "Transponderdaten von Kombi an WFS-Master senden";

CM_ SG_ 830 WFS_Diag_LF_Aktiv_02 "Transponderdiagnose ist aktiv (nicht WFS)";
CM_ SG_ 830 WFS_LF_aktiv_02 "LF aktiv, Zugriff auf Transponder";
CM_ SG_ 830 WFS_Transp_Mod_Unterbrechung_02 "Transponder Gateway verlässt Modus Sleep oder Unterspannung";
CM_ SG_ 830 WFS_Verbau_Transp_Ant_02 "Kodierung Funktion Transponderantenne";

CM_ SG_ 1702 BCM1_SRA_aktiv "Status Scheinwerferreinigungsanlage";
CM_ SG_ 1702 Heckwischer_Anforderung "Das Signal beschreibt die Anforderung an den Signalausgang im BCM2 zur Ansteuerung des Heckwischers.";
CM_ SG_ 1702 Waschen_vorne_aktiv "Status: Waschen vorne aktiv";
CM_ SG_ 1702 Wischer1_Wischgeschwindigkeit "aktuelle, durch Sensorik gemessene Wischgeschwindigkeit";
CM_ SG_ 1702 Wischer_Anzeigetext "Das Signal fordert einen Kombi-Pop-Up mit entsprechenden Texten an";
CM_ SG_ 1702 Wischer_vorne_aktiv "Status: Wischer vorne";
CM_ SG_ 1702 Wischer_vorne_blockiert "Blockade Wischer vorne (z.B. durch Schnee)";
CM_ SG_ 1702 Wischer_vorne_defekt "Fehlerstatus Wischer vorne (Anzeige im Kombi)";
CM_ SG_ 1702 Wischer_vorne_Normal "Wischer Front normal aktiv";
CM_ SG_ 1702 Wischer_vorne_Parklage "Wischer Front in Parklage";
CM_ SG_ 1702 Wischer_vorne_Schnell "Wischer vorne schnell aktiv";
CM_ SG_ 1702 Wischer_WH_PopUp_Anf "Anzeige von Wischerstufen im Kombi.";
CM_ SG_ 1702 Wischer_WH_Typ "Signal beinhaltet Lenkstockschaltertyp für grafische Anzeige im Kombi zur Wischerfunktion";
CM_ SG_ 1702 WWSs_01_alt "Veraltet Bit für die LIN-Botschaft WWSs_01.

Betroffene Signale:

Wischer_vorne_aktiv";

CM_ SG_ 2589283611 WLC1_aktive_Spule "Active_Coil";
CM_ SG_ 2589283611 WLC1_Charger_Effizienz "Charger charging (Efficiency in % )
0 = no charging 
1 = charging with 1%
10 = charging with 10 %";
CM_ SG_ 2589283611 WLC1_Charger_laedt "Charger charging (übertragene Leistung) (0,1W)

0 = no charging 
1 = charging with 0,1 Watt
10 = charging with 1 Watt";
CM_ SG_ 2589283611 WLC1_Fehler "Übermittelt auftretende Fehler des WLC an das Master-SG zur Ablage im dort verorteten Fehlerspeicher";
CM_ SG_ 2589283611 WLC1_Fremdobjekt_erkannt "Messwert/Anzeige Fremdobjekt erkannt";
CM_ SG_ 2589283611 WLC1_Leistungsklasse_Receiver "Performance_Class_Receiver
0 = no Device
1 = class with 0,1 Watt
10 = class with 1 Watt";
CM_ SG_ 2589283611 WLC1_Objekt_erkannt "non wireless Charging Device in the storage box ";
CM_ SG_ 2589283611 WLC1_Receiver_erkannt "wireless Charging Device (Phone) is in the storage box ";
CM_ SG_ 2589283611 WLC1_Receiver_voll_geladen "0 = WLC not fully charged or no Device available
1 = WLC Device fully charged ";
CM_ SG_ 2589283611 WLC1_Temp_Leistungsteil_Charger "Temperature_Power_Electronics
0 = -58 °C
1 = -57 °C
..";
CM_ SG_ 2589283611 WLC1_Temp_Oberfaeche_Charger "Surface_Temperature_WLC
0 = -58 °C
1 = -57 °C
..";
CM_ SG_ 2589283611 WLC1_Temp_Receiver "Temperature_Receiver
0 = -58 °C
1 = -57 °C
..";
CM_ SG_ 2589283611 WLC1_verwendeter_Ladestandard "WLC_technology";

CM_ SG_ 2527679836 WLC1_ChargingEfficiency "This signal contains the charging efficiency in per cent of WLC1.";
CM_ SG_ 2527679836 WLC1_ChargingStatus "This signal contains the charging status of WLC1.";
CM_ SG_ 2527679836 WLC1_UsedChargingStandard "This signal contains the used charging standard of WLC1.";

CM_ SG_ 2527679837 WLC2_ChargingEfficiency "This signal contains the charging efficiency in per cent of WLC2.";
CM_ SG_ 2527679837 WLC2_ChargingStatus "This signal contains the charging status of WLC2.";
CM_ SG_ 2527679837 WLC2_UsedChargingStandard "This signal contains the used charging standard of WLC2.";

CM_ SG_ 2463978688 DMD_Soll_TempMode_L "Angabe des einzustellenden Temperatur-Modus";
CM_ SG_ 2463978688 DMD_Soll_TempMode_R "Angabe des einzustellenden Temperatur-Modus";
CM_ SG_ 2463978688 DML_EcoModus "Eco Modus
Umsetzung unterschiedlicher EcoModi zur Energieersparnis beim BEV";
CM_ SG_ 2463978688 DML_Fehlermeldung_Anf "Anforderung der Fehlermeldung im FPK
0=Fehlermeldung_nicht_angefordert
1=Fehlermeldung_angefordert";
CM_ SG_ 2463978688 DML_Fernlichtlampe_Anf "Anforderung der blauen Fernlichtlampe im FPK
0=Fernlichtlampe_nicht_angefordert
1=Fernlichtlampe_angefordert";
CM_ SG_ 2463978688 zDML_ETH_Fehler "Rückmeldung eines Ethernet-Fehlers.";
CM_ SG_ 2463978688 zDML_ETH_Timeout "Rückmeldung eines Ethernet-Timeouts.";
CM_ SG_ 2463978688 zDML_Fokus "Steuerung der Anzahl an LEDs zur Verbesserung der Fokussierung";
CM_ SG_ 2463978688 zDML_GMSL_L_Fehler "Rückmeldung eines GMSL/LVDS-Fehlers.";
CM_ SG_ 2463978688 zDML_GMSL_R_Fehler "Rückmeldung eines GMSL/LVDS-Fehlers.";
CM_ SG_ 2463978688 zDML_L_Abblendl_2_Def "DML Anteil Abblendlicht links defekt";
CM_ SG_ 2463978688 zDML_LED_L_Anf "Ansteuerung der DMD-LEDs durch das zDML.";
CM_ SG_ 2463978688 zDML_LED_R_Anf "Ansteuerung der DMD-LEDs durch das zDML.";
CM_ SG_ 2463978688 zDML_R_Abblendl_2_Def "DML Anteil Abblendlicht rechts defekt";
CM_ SG_ 2463978688 zDML_SG_Defekt "Rückmeldung eines Steuergeräte-Defekts.";
CM_ SG_ 2463978688 zDML_Speicher_Fehler "Rückmeldung eines Speicher-Fehlers.";
CM_ SG_ 2463978688 zDML_Status "Allgemeine Statusmeldung des zDML.";
CM_ SG_ 2463978688 zDML_Versorgung_Fehler "Rückmeldung eines Spg.-Versorgungs-Fehlers.";
CM_ SG_ 2463978688 zDML_Video_Anf "Anfrage des Handshake für den H264 Ethernet-Stream";
CM_ SG_ 2463978688 zDML_Video_Fehler "Rückmeldung eines Video-Fehlers.";

CM_ SG_ 2463978854 DML_ConstructionZone_Available "Verfügbarkeit der Funktion Bau/Engstellenassistent im zDML";
CM_ SG_ 2463978854 DML_CrossingAssist_Available "Dieses Signal gibt an ob die Funktion Kreuzungsassistent im HMI verfügbar sein soll oder nicht.";
CM_ SG_ 2463978854 DML_FuliValid "Gültigkeit der Funktionsliste vom zDML";
CM_ SG_ 2463978854 DML_GhostDriverWarn_Available "Verfügbarkeit der Funktion Geister/Falschfahrerwarnung im zDML";
CM_ SG_ 2463978854 DML_GlarefreeHB_Available "Verfügbarkeit der Funktion Blendfreies Fernlicht im zDML";
CM_ SG_ 2463978854 DML_HazardWarning_Available "Dieses Signal wird benötigt um dem HMI mitzuteilen ob die Funktion 'Gefahrenwarnung' im zDML verfügbar ist oder nicht.";
CM_ SG_ 2463978854 DML_HMI_FCN_CROSSINGLI_AVAILABLE "Dieses Signal gibt an ob die Funktion Kreuzungsassistentim HMI verfügbar ist oder nicht.";
CM_ SG_ 2463978854 DML_HMI_FCN_HAZARDWARN_AVAILABLE "Dieses Signal gibt an ob die Funktion Gefahrenwarnung im HMI verfügbar ist oder nicht.";
CM_ SG_ 2463978854 DML_HMI_FCN_LANELIGHT_AVAILABLE "Dieses Signal gibt an ob die Funktion Spurlicht im HMI verfügbar ist oder nicht.";
CM_ SG_ 2463978854 DML_HMI_FCN_LANLEAVELI_AVAILABLE "Dieses Signal gibt an ob die Funktion Spurverlassenswarnung im HMI verfügbar ist oder nicht.";
CM_ SG_ 2463978854 DML_HMI_FCN_MALI_AVAILABLE "Dieses Signal gibt an ob die Funktion Markierungslicht im HMI verfügbar ist oder nicht.";
CM_ SG_ 2463978854 DML_HMI_FCN_ORLI_AVAILABLE "Dieses Signal gibt an ob die Funktion Orientierungslicht im HMI verfügbar ist oder nicht.";
CM_ SG_ 2463978854 DML_HMI_FCN_RESALLEYHI_AVAILABLE "Dieses Signal gibt an ob die Funktion Rettungsgassenhinweis im HMI verfügbar ist oder nicht.";
CM_ SG_ 2463978854 DML_HMI_FCN_ROADWORKLI_AVAILABLE "Dieses Signal gibt an ob die Funktion Bau/Engstellenlicht im HMI verfügbar ist oder nicht.";
CM_ SG_ 2463978854 DML_HMI_FCN_SAFETYZONE_AVAILABLE "Dieses Signal gibt an ob die Funktion Sicherheitszone im HMI verfügbar ist oder nicht.";
CM_ SG_ 2463978854 DML_HMI_FCN_TURNLIGHPR_AVAILABLE "Dieses Signal gibt an ob die Funktion Blinkerprojektion im HMI verfügbar ist oder nicht.";
CM_ SG_ 2463978854 DML_Indicator_Available "Verfügbarkeit der Funktion Blinkerprojektion im zDML";
CM_ SG_ 2463978854 DML_IntelligentHB_Available "Verfügbarkeit der Funktion IntelligentHighBeam im zDML";
CM_ SG_ 2463978854 DML_LaneDepartureWarn_Available "Verfügbarkeit der Funktion Spurverlassenswarnung im zDML";
CM_ SG_ 2463978854 DML_LaneLight_Available "Dieses Signal gibt an ob die Funktion Spurlicht im HMI verfügbar ist oder nicht.";
CM_ SG_ 2463978854 DML_MarkingLight_Available "Verfügbarkeit der Funktion Markierungslicht im zDML";
CM_ SG_ 2463978854 DML_OrientationLight_Available "Verfügbarkeit der Funktion Orientierungslicht im zDML";
CM_ SG_ 2463978854 DML_RescueLaneNotice_Available "Verfügbarkeit der Funktion Rettungsgassenhinweis im zDML";
CM_ SG_ 2463978854 DML_SafetyZone_Available "Verfügbarkeit der Funktion Sicherheitszone im zDML";
CM_ SG_ 2463978854 DML_SaftyDistance_Available "Verfügbarkeit der Funktion Abstandswarnung im zDML";
CM_ SG_ 2463978854 DML_SideAssist_Available "Verfügbarkeit der Funktion SideAssist im zDML";

CM_ SG_ 1140 DI_Screendesign "Information welcher Designwunsch ausgewählt wurde zur Kennlinienumschaltung";
CM_ SG_ 1140 MMI_State "Powerstate des Zentralrechners. MMI_Off wird im Zustand dead mode gesendet.";
CM_ SG_ 1140 SI_ICAN "MQB: Busruhe ICAN.
E3: Busruhe ABCAN.";
CM_ SG_ 1140 WLC1_Systemzustand "0 = Wireless Charger off (Message produced by HMI)
1 = Wireless Charger on (Message produced by HMI)";
CM_ SG_ 1140 WLC2_Systemzustand "0 = Wireless Charger off
1 = Wireless Charger on";
CM_ SG_ 1140 ZR_DimOffs_DU_1 "Dimmungs-Offset der Display Unit.";
CM_ SG_ 1140 ZR_DimOffs_DU_2 "Dimmungs-Offset der Display Unit.";
CM_ SG_ 1140 ZR_DimOffs_DU_3 "Dimmungs-Offset der Display Unit.";
CM_ SG_ 1140 ZR_DimOffs_DU_4 "Dimmungs-Offset der Display Unit.";
CM_ SG_ 1140 ZR_Lenkerposition "Ueber Diagnose (Codierung) im Zentralrechner eingespeicherte Lenkerposition
  ";
CM_ SG_ 1140 ZR_State_DU_1 "Kontrollbit für Display, Hintergrundbeleuchtung aus, Hintergrundbeleuchtung an, Energiesparmodus.
";
CM_ SG_ 1140 ZR_State_DU_2 "Kontrollbit für Display, Hintergrundbeleuchtung aus, Hintergrundbeleuchtung an, Energiesparmodus.
";
CM_ SG_ 1140 ZR_State_DU_3 "Kontrollbit für Display, Hintergrundbeleuchtung aus, Hintergrundbeleuchtung an, Energiesparmodus.
";
CM_ SG_ 1140 ZR_State_DU_4 "Kontrollbit für Display, Hintergrundbeleuchtung aus, Hintergrundbeleuchtung an, Energiesparmodus.";
CM_ SG_ 1140 ZR_WecktGesp "Befehl zum Sperren der Wecktasten am Bedienteil.";

CM_ SG_ 2589284130 ZR_ORU_Status "Update Information Infotainment";

CM_ SG_ 389 Krypt_Schluesselschalter_auf "Schluesselschalter 'Auf' betaetigt";
CM_ SG_ 389 Krypt_Schluesselschalter_zu "Schluesselschalter 'ZU' betaetigt";
CM_ SG_ 389 Krypt_Signatur "Kryptologiesignatur";
CM_ SG_ 389 ZFH_BFS_AutoHoch "automatischer Hochlauf des BFS Fenster ausgelöst durch zentralen Fensterhebertaster";
CM_ SG_ 389 ZFH_BFS_AutoTief "automatischer Tieflauf des BFS Fenster ausgelöst durch zentralen Fensterhebertaster";
CM_ SG_ 389 ZFH_BFS_ManHoch "manueller Hochlauf des BFS Fenster ausgelöst durch zentralen Fensterhebertaster";
CM_ SG_ 389 ZFH_BFS_ManTief "manueller Tieflauf des BFS Fenster ausgelöst durch zentralen Fensterhebertaster";
CM_ SG_ 389 ZFH_FS_AutoHoch "automatischer Hochlauf des FS Fenster ausgelöst durch zentralen Fensterhebertaster";
CM_ SG_ 389 ZFH_FS_AutoTief "automatischer Tieflauf des FS Fenster ausgelöst durch zentralen Fensterhebertaster";
CM_ SG_ 389 ZFH_FS_ManHoch "manueller Hochlauf des FS Fenster ausgelöst durch zentralen Fensterhebertaster";
CM_ SG_ 389 ZFH_FS_ManTief "manueller Tieflauf des FS Fenster ausgelöst durch zentralen Fensterhebertaster";
CM_ SG_ 389 ZFH_HBFS_AutoHoch "automatischer Hochlauf des HBFS Fenster ausgelöst durch zentralen Fensterhebertaster";
CM_ SG_ 389 ZFH_HBFS_AutoTief "automatischer Tieflauf des HBFS Fenster ausgelöst durch zentralen Fensterhebertaster";
CM_ SG_ 389 ZFH_HBFS_ManHoch "manueller Hochlauf des HBFS Fenster ausgelöst durch zentralen Fensterhebertaster";
CM_ SG_ 389 ZFH_HBFS_ManTief "manueller Tieflauf des HBFS Fenster ausgelöst durch zentralen Fensterhebertaster";
CM_ SG_ 389 ZFH_HFS_AutoHoch "automatischer Hochlauf des HFS Fenster ausgelöst durch zentralen Fensterhebertaster";
CM_ SG_ 389 ZFH_HFS_AutoTief "automatischer Tieflauf des HFS Fenster ausgelöst durch zentralen Fensterhebertaster";
CM_ SG_ 389 ZFH_HFS_ManHoch "manueller Hochlauf des HFS Fenster ausgelöst durch zentralen Fensterhebertaster";
CM_ SG_ 389 ZFH_HFS_ManTief "manueller Tieflauf des HFS Fenster ausgelöst durch zentralen Fensterhebertaster";
CM_ SG_ 389 ZFH_zentral_auf "Zentraler Tieflauf aller Seitenscheiben";
CM_ SG_ 389 ZFH_zentral_zu "Zentraler Hochlauf aller Seitenscheiben";

CM_ SG_ 388 BCM_BF_Spg_Absenkung "Spiegelabsenkung Beifahrerseite";
CM_ SG_ 388 BCM_Spg_Synchron "Anforderung zur Aktivierung der synchronen Spiegelverstellung";
CM_ SG_ 388 FH_BT_hoch "Freigabeinformation fuer die FH-Komfortfunktion";
CM_ SG_ 388 FH_BT_tief "Freigabeinformation fuer die FH-Komfortfunktion";
CM_ SG_ 388 FH_FT_hoch "Freigabeinformation fuer die FH-Komfortfunktion";
CM_ SG_ 388 FH_FT_tief "Freigabeinformation fuer die FH-Komfortfunktion";
CM_ SG_ 388 FH_HBFS_hoch "Freigabeinformation fuer die FH-Komfortfunktion";
CM_ SG_ 388 FH_HBFS_tief "Freigabeinformation fuer die FH-Komfortfunktion";
CM_ SG_ 388 FH_HFS_hoch "Freigabeinformation fuer die FH-Komfortfunktion";
CM_ SG_ 388 FH_HFS_tief "Freigabeinformation fuer die FH-Komfortfunktion";
CM_ SG_ 388 VIP_Freigabe "Vituelles Pedal ist über HMI freigeschaltet.";
CM_ SG_ 388 VIP_Sensor_betaetigt "Heckentriegelung durch die Bedienstelle Virtuelles Pedal(VIP) erkannt. Der VIP Sensor hat eine Fusskickbewegung erkannt und es wurde ein Kessy - Schlüssel im Heckaussenbereich erkannt.";
CM_ SG_ 388 ZV_01_CRC "Für MLB:
'Berechnung siehe Lastenheft 'Kommunikationsabsicherung für FlexRay und CAN''

Ab MQB und MLBevo:
'Berechnung siehe Lastenheft 'End-to-End Kommunikationsabsicherung''

Endwerte siehe Begleitdokument 'S-PDU Kennungsfolgen'";
CM_ SG_ 388 ZV_auf_BT "ZV Schliessstelle";
CM_ SG_ 388 ZV_auf_FT "ZV Schliessstelle";
CM_ SG_ 388 ZV_auf_Funk "ZV Schliessstelle";
CM_ SG_ 388 ZV_auf_Kessy "ZV Schliessstelle";
CM_ SG_ 388 ZV_auto_Ansteuerung "Kennung für die automatische Ansteuerung der Zentralverriegelung (Autolock/Autounlock)";
CM_ SG_ 388 ZV_BT_entriegeln "Beifahrertür entriegeln (Anforderung ZV)";
CM_ SG_ 388 ZV_BT_verriegeln "Verriegelungsanforderung ZV für BT";
CM_ SG_ 388 ZV_entriegeln_Anf "Bei ZV Anforderung erfolgt die Entriegelung des Ladesteckers";
CM_ SG_ 388 ZV_FT_entriegeln "Entriegelungsanforderung ZV für FT";
CM_ SG_ 388 ZV_FT_verriegeln "Verriegelungsanforderung ZV für FT";
CM_ SG_ 388 ZV_HBFS_entriegeln "Entriegelungsanforderung ZV für HBFS
";
CM_ SG_ 388 ZV_HBFS_verriegeln "Verriegelungsanforderung ZV für HBFS
";
CM_ SG_ 388 ZV_HFS_entriegeln "Entriegelungsanforderung ZV für HFS
";
CM_ SG_ 388 ZV_HFS_verriegeln "Verriegelungsanforderung ZV für HFS
";
CM_ SG_ 388 ZV_HSK_entriegeln "Anforderungssignal zur Ansteuerung des Handschuhkastenmotors in Richtung Entriegeln. ";
CM_ SG_ 388 ZV_HSK_verriegeln "Anforderungssignal zur Ansteuerung des Handschuhkastenmotors in Richtung Verriegeln. ";
CM_ SG_ 388 ZV_LED_Steuerung "Ansteuerung der LED's in den Tueren; BAF gilt nicht für dieses Bit";
CM_ SG_ 388 ZV_LED_Uebernahme "Uebernahme der LED Steuerung durch das TSG FT";
CM_ SG_ 388 ZV_Signatur "Signatur der ZV";
CM_ SG_ 388 ZV_Softtouch_betaetigt "Betätigung Softtouch";
CM_ SG_ 388 ZV_Spg_Anklappen "Anforderung über ZV: Spiegel sind anzuklappen";
CM_ SG_ 388 ZV_Verdeck_auf "Anforderungssignal für ein Komfortöffnen des Verdecks. 
Signal wird angefordert wenn  SKontakt = 0 und eine Doppelbetätigung Schließzylinder_auf oder Funkfernbedienung_Taste_auf  innerhalb zwei Sekunden empfangen wird. Signal wird auch angefordert wenn S";
CM_ SG_ 388 ZV_Verdeck_zu "Anforderungssignal für ein Komfortschließen des Verdecks. 
Signal wird angefordert wenn  SKontakt = 0 und eine Doppelbetätigung Schließzylinder_Zu oder Funkfernbedienung_Taste_zu  innerhalb zwei Sekunden empfangen wird. Signal wird auch angefordert wenn ";
CM_ SG_ 388 ZV_zentral_entsafen "Zentral entsafen";
CM_ SG_ 388 ZV_zentral_safen "Zentral safen";
CM_ SG_ 388 ZV_zu_BT "ZV Schliessstelle";
CM_ SG_ 388 ZV_zu_FT "ZV Schliessstelle";
CM_ SG_ 388 ZV_zu_Funk "ZV Schliessstelle";
CM_ SG_ 388 ZV_zu_Kessy "ZV Schliessstelle";
CM_ SG_ 388 ZV_zu_Zeitl_Nachverr "ZV Schliessstelle";

CM_ SG_ 1411 BCM_FH_Freigabe "Funktionsfreigabe Fensterheber";
CM_ SG_ 1411 BCM_HSK_Freigabe "Handschuhkastenfreigabe";
CM_ SG_ 1411 BCM_Komfortfkt_Freigabe "globale Freigabe der Komfortfunktion";
CM_ SG_ 1411 BCM_Tankklappensteller_Fehler "Fehler: nicht Funktionalität des Tankklappenstellers";
CM_ SG_ 1411 BCM_Verdeck_Freigabe "Freigabe Verdeckbetrieb
";
CM_ SG_ 1411 DWA_aktiv "Status DWA  aktiv";
CM_ SG_ 1411 FBS_IDG_in_Reichweite "Für elektrisch betätigte Türen und Klappen muss für eine Betätigung über Funk eine Reichweitenbegrenzung eingeführt werden. Diese Bit zeigt an, dass sich der Funkschlüssel innerhalb der geforderten Reichweite befindet";
CM_ SG_ 1411 FBS_Warn_Schluessel_Batt "Kombi Prio Warnung Schluessel Batterie
'Bitte Schlüsselbatterie wechseln!'";
CM_ SG_ 1411 FFB_Auf_Taste "Auf-Taste Funkschluessel

";
CM_ SG_ 1411 FFB_CarFinder "Car Finder Funktion (Blinken ohne zu entriegeln)";
CM_ SG_ 1411 FFB_HDF_Taste "HDF Taste am Funkschluessel
";
CM_ SG_ 1411 FFB_Komfortoeffnen "Komfortoeffnen Funk
";
CM_ SG_ 1411 FFB_Komfortschliessen "Komfortschliessen Funk
";
CM_ SG_ 1411 FFB_Panik_Taste "Panik Taste Funkschluessel
";
CM_ SG_ 1411 FFB_Zu_Taste "Zu-Taste Funkschluessel
";
CM_ SG_ 1411 HBFS_gesafet "HBFS Tuer gesafet.
Im Zustand Safe wird auch das Signal HBFS_verriegelt = 1 gesendet.";
CM_ SG_ 1411 HBFS_verriegelt "Verriegelungsstatus Tür";
CM_ SG_ 1411 HD_Hauptraste "SBL-Schloss (MQB/MLBevo): Drehfalle Heckdeckel
sonst (MQB): Hauptraste Heckdeckel";
CM_ SG_ 1411 HD_Vorraste "SBL_Schloss (MQB/MLBevo): Sperrklinke Heckdeckel
sonst (MQB): Vorraste Heckdeckel";
CM_ SG_ 1411 HFS_gesafet "HFS Tuer gesafet.
Im Zustand Safe wird auch das Signal HFS_verriegelt = 1 gesendet.";
CM_ SG_ 1411 HFS_verriegelt "HFS Tuer verriegelt";
CM_ SG_ 1411 IRUE_aktiv "Status Innenraumüberwachung
";
CM_ SG_ 1411 IRUE_Taster_Fkts_LED "Anforderung Funktions-LED IRUE-Taster (LED wird vom TSG angesteuert)
MQB: Bei Verbau eines einzelnen Taster zur Deaktivierung von IRUE und NGS wird dieses Signal zur Ansteuerung der Funktions-LED gesendet.";
CM_ SG_ 1411 VIP_Sensor_STSG_HBFS_betaetigt "Schiebetürlauf HBFS wurde durch VIP angefordert und als berechtigt eingestuft.";
CM_ SG_ 1411 VIP_Sensor_STSG_HFS_betaetigt "Schiebetürlauf HFS wurde durch VIP angefordert und als berechtigt eingestuft.";
CM_ SG_ 1411 ZV_Anf_Challenge_Auth "Anforderung an alle beteiligten Steuergeräte die Challenge an den ZV-Master zu senden.";
CM_ SG_ 1411 ZV_BT_offen "gespiegeltes Bit BT_Tuer_geoeffnet TSG_BT_1 Botschaft";
CM_ SG_ 1411 ZV_Einzeltuerentriegelung "Einzeltürentriegelung ZV
";
CM_ SG_ 1411 ZV_eRWK_Umfeld_Pruefung "Anforderung an PDC/PLA im eRWK-Modus eine Umfeldprüfung durchzuführen";
CM_ SG_ 1411 ZV_FT_offen "gespiegeltes Bit FT_Tuer_geoeffnet TSG_FT_1 Botschaft";
CM_ SG_ 1411 ZV_gesafet_extern_ist "Istzustand: Fahrzeug aussen gesafet
";
CM_ SG_ 1411 ZV_gesafet_extern_soll "Sollzustand: Fahrzeug gesafet extern
";
CM_ SG_ 1411 ZV_HBFS_offen "gespiegeltes Bit HBFS_Tuer_geoeffnet TSG_HBFS_1 Botschaft";
CM_ SG_ 1411 ZV_HD_offen "Status Heckdeckel
";
CM_ SG_ 1411 ZV_Heckeinzelentriegelung "Heckdeckeleinzelentriegelung";
CM_ SG_ 1411 ZV_HFS_offen "gespiegeltes Bit HFS_Tuer_geoeffnet TSG_HFS_1 Botschaft";
CM_ SG_ 1411 ZV_HS_offen "Status Heckscheibe
";
CM_ SG_ 1411 ZV_ist_Zustand_verfuegbar "Verfügbarkeit IST-Zustand ZV

";
CM_ SG_ 1411 ZV_Oeffnungsmodus "Konfigurierter Oeffnungsmodus fuer ZV:
0 = globale Oeffnung (alle Tueren)
1 = ZV mit Einzeltuerentriegelung (FFB - nur Fahrertuer, Kessy - nur bediente Tuer)
2 = ZV individuell selektive Oeffnung (FFB - Fahrerseite, Kessy - bediente Tuer + Fahrertuer)";
CM_ SG_ 1411 ZV_Rollo_auf "Komfortöffnen des Dachrollos";
CM_ SG_ 1411 ZV_Rollo_zu "Komfortschließen des Dachrollos";
CM_ SG_ 1411 ZV_SAD_auf "Komfortöffnen des Schiebeausstelldaches";
CM_ SG_ 1411 ZV_SAD_zu "Komfortschließen des Schiebeausstelldaches";
CM_ SG_ 1411 ZV_SafeFunktion_aktiv "Statusübermittlung ob die Safe Funktion im Fzg. aktiv ist. Das Kombi benötigt das Signal, um den Text Safelock aktiv anzuzeigen. ";
CM_ SG_ 1411 ZV_Schluessel_Zugang "aktuelle Funkschlüsselnummer";
CM_ SG_ 1411 ZV_STSG_Crashzustand "Statusübermittlung ob der Crashzustand der Schiebetüren dauerhaft im Fzg. aktiv ist. Das Kombi benötigt das Signal, um die Meldung anzuzeigen.";
CM_ SG_ 1411 ZV_STSG_eKiSi_defekt "Statusübermittlung ob die elektronische Kindersicherung der Schiebetüren im Fzg. defekt ist. Das Kombi benötigt das Signal, um die Meldung anzuzeigen.";
CM_ SG_ 1411 ZV_STSG_HBFS_Anf "Die ZV fordert einen Lauf bzw. Stopp der Schiebetür an.";
CM_ SG_ 1411 ZV_STSG_HFS_Anf "Die ZV fordert einen Lauf bzw. Stopp der Schiebetür an.";
CM_ SG_ 1411 ZV_Tankklappe_offen "Öffnungsstatus der Tankklappe";
CM_ SG_ 1411 ZV_verriegeln_Anf "Gesammelte externe ZV-Verriegelungsanforderung des Kunden (z. B. zur Aktivierung der Anzeige des Ladezustands über Aussenlicht).";
CM_ SG_ 1411 ZV_verriegelt_extern_ist "Istzustand: Verriegelung Fahrzeug aussen
";
CM_ SG_ 1411 ZV_verriegelt_extern_soll "Sollzustand: Verriegelung Fahrzeug aussen
";
CM_ SG_ 1411 ZV_verriegelt_intern_ist "Istzustand: Verriegelung Fahrzeug innen
";
CM_ SG_ 1411 ZV_verriegelt_intern_soll "Sollzustand: Verriegelung Fahrzeug innen
";
CM_ SG_ 1411 ZV_verriegelt_soll "Fahrzeug Gesamtverriegelungsstatus Sollzustand für Ladestecker- und Ladeklappenverriegelung. ";

CM_ SG_ 708 UHF_FFB_Funkschluesseltyp "Typ des Funkschluessels und Funkfrequenzen";
CM_ SG_ 708 UHF_FFB_SKC_anlernen "Neuer FFB_SKC von der WFS-Applikation";
CM_ SG_ 708 ZV_04_BZ "4bit Botschaftszähler, wird mit jeder Sendebotschaft inkrementiert";
CM_ SG_ 708 ZV_04_CRC "Für MLB:
Berechnung siehe Lastenheft 'Kommunikationsabsicherung für FlexRay und CAN'
Ab MQB und MLBevo:
Berechnung siehe Lastenheft 'End-to-End Kommunikationsabsicherung'

Endwerte siehe Begleitdokument 'S-PDU Kennungsfolgen'";
CM_ SG_ 708 ZV_DWA_Einfachhorn_Anf "Anforderung zur Ansteuerung der Einfachhorns (statisches Signal)";
CM_ SG_ 708 ZV_DWA_Einfachhorn_Takt "Takt für die Ansteuerung des Einfachhorns über SWC-QTG";
CM_ SG_ 708 ZV_Einfachhorn_Anf "Anforderung zur Ansteuerung der Einfachhorns (statisches Signal) durch die ZV";
CM_ SG_ 708 ZV_Einfachhorn_Takt "Takt für die Ansteuerung des Einfachhorns über SWC-ZV";
CM_ SG_ 708 ZV_HBFS_Status_KiSi "Status der Kindersicherung: aktiv-inaktiv
hinten Beifahrerseite";
CM_ SG_ 708 ZV_HBFS_TAG_betaetigt "Status des Türaußengriffs, betatigt-nicht betaetigt
hinten Beifahrerseite";
CM_ SG_ 708 ZV_HBFS_TIG_oeffnen_betaetigt "Status des Türinnengriffs_oeffnen, betaetigt-nicht betaetigt
hinten Beifahrerseite";
CM_ SG_ 708 ZV_HBFS_TIG_schliessen_betaetigt "Status des Türinnengriffs_schliessen, betaetigt-nicht betaetigt
hinten Beifahrerseite";
CM_ SG_ 708 ZV_HFS_Status_KiSi "Status der Kindersicherung: aktiv-inaktiv
hinten Fahrerseite";
CM_ SG_ 708 ZV_HFS_TAG_betaetigt "Status des Türaußengriffs, betatigt-nicht betaetigt
hinten Fahrerseite";
CM_ SG_ 708 ZV_HFS_TIG_oeffnen_betaetigt "Status des Türinnengriffs_oeffnen, betaetigt-nicht betaetigt
hinten Fahrerseite";
CM_ SG_ 708 ZV_HFS_TIG_schliessen_betaetigt "Status des Türinnengriffs_schliessen, betaetigt-nicht betaetigt
hinten Fahrerseite";
CM_ SG_ 708 ZV_Hupe_Anf "Anforderung zur Ansteuerung des Signalhorns (statisches Signal) durch die ZV";
CM_ SG_ 708 ZV_Hupe_Takt "Takt für die Ansteuerung des Signalhorns über SWC-ZV";
CM_ SG_ 708 ZV_HW_Motor_Lock_HK "Ansteuervorgabe für den Schlossmotor der Heckklappe";
CM_ SG_ 708 ZV_HW_Motor_Safe_Hinten "Ansteuervorgabe für die Safemotoren Hinten";
CM_ SG_ 708 ZV_HW_TKL_mot_entr "Ansteuerung des Tankklappenmotors für die Entriegelung";
CM_ SG_ 708 ZV_HW_TKL_mot_verr "Ansteuerung des Tankklappenmotors für die Verriegelung";
CM_ SG_ 708 ZV_Laderaumabd_elektr_aktiviert "Komfortöffnen Elektrische Laderaumabdeckung aktiviert";
CM_ SG_ 708 ZV_Status_Cargolock "Status der CargoLock-Funktion";
CM_ SG_ 708 ZV_Status_KiSi_CargoLock "Status Kindersicherung oder Status des CargoLock (abhängig von der Austattungsvariante)";
BA_DEF_REL_ BU_SG_REL_  "GenSigTimeoutTime" INT 0 65535;
BA_DEF_ BO_  "DiagRequest" ENUM "No", "Yes";
BA_DEF_ BO_  "DiagResponse" ENUM "No", "Yes";
BA_DEF_ BO_  "DiagState" ENUM "No", "Yes";
BA_DEF_ BO_  "GenMsgChkConstant" HEX 0 4095;
BA_DEF_ BO_  "GenMsgCycleTime" INT 0 65535;
BA_DEF_ BO_  "GenMsgCycleTimeFast" INT 0 65535;
BA_DEF_ BO_  "GenMsgDelayTime" INT 0 100000;
BA_DEF_ BO_  "GenMsgILSupport" ENUM "No", "Yes";
BA_DEF_ BO_  "GenMsgNrOfRepetition" INT 0 100;
BA_DEF_ BO_  "GenMsgPDUConstants" STRING;
BA_DEF_ BO_  "GenMsgSendType" ENUM "Cyclic", "not_used", "not_used", "not_used", "not_used", "not_used", "not_used", "IfActive", "NoMsgSendType";
BA_DEF_ BO_  "GenMsgStartDelayTime" INT 0 100000;
BA_DEF_ BO_  "NmMessage" ENUM "No", "Yes";
BA_DEF_ BO_  "NmhMessage" ENUM "No", "Yes";
BA_DEF_ BO_  "MsgType" ENUM "Application", "NM ", "NMH", "TP2.0", "ISO-TP ", "BAP", "EID", "KS", "XCP_PRE_CONFIGURED", "XCP_RUNTIME_CONFIGURED";
BA_DEF_ BO_  "VAGTP20_API" HEX 0 255;
BA_DEF_ BO_  "VAGTP20_DynConnection" ENUM "No", "Yes";
BA_DEF_ BO_  "VAGTP20_DynSetup" ENUM "No", "Yes";
BA_DEF_ BO_  "VAGTP20_StatConnection" ENUM "No", "Yes";
BA_DEF_ BO_  "CANFD_BRS" ENUM "0", "1";
BA_DEF_ BO_  "VFrameFormat" ENUM "StandardCAN", "ExtendedCAN", "reserved", "reserved", "reserved", "reserved", "reserved", "reserved", "reserved", "reserved", "reserved", "reserved", "reserved", "reserved", "StandardCAN_FD", "ExtendedCAN_FD";
BA_DEF_ SG_  "GenSigActiveRepetitions" INT -2147483648 2147483647;
BA_DEF_ SG_  "GenSigInactiveValue" INT -2147483648 2147483647;
BA_DEF_ SG_  "GenSigSendType" ENUM "Cyclic", "OnWrite", "OnWriteWithRepetition", "OnChange", "OnChangeWithRepetition", "IfActive", "IfActiveWithRepetition", "NoSigSendType", "OnChangeAndIfActive", "OnChangeAndIfActiveWithRepetition";
BA_DEF_ SG_  "GenSigStartValue" INT -2147483648 2147483647;
BA_DEF_ SG_  "NWM-WakeupAllowed" ENUM "No", "Yes";
BA_DEF_ SG_  "GenSigFuncType" ENUM "NoFunction", "MsgCounter", "CRC-8", "XOR", "XOR-2", "DatedBit", "SW-Kl15", "CHK", "Constant", "Protocol", "CRC-8-SAE_J1850", "CRC-32", "DataLength", "DataID", "MsgCounter16", "SOK-Signatur", "Cluster";
BA_DEF_ SG_  "GenSigSwitchedByIgnition" ENUM "No", "Yes";
BA_DEF_ SG_  "Fehlerwert" HEX 0 2147483647;
BA_DEF_ SG_  "GenSigMissingSourceValue" HEX 0 2147483647;
BA_DEF_DEF_REL_  "GenSigTimeoutTime" 0;
BA_DEF_DEF_  "DiagRequest" "No";
BA_DEF_DEF_  "DiagResponse" "No";
BA_DEF_DEF_  "DiagState" "No";
BA_DEF_DEF_  "GenMsgChkConstant" 0;
BA_DEF_DEF_  "GenMsgCycleTime" 0;
BA_DEF_DEF_  "GenMsgCycleTimeFast" 0;
BA_DEF_DEF_  "GenMsgDelayTime" 0;
BA_DEF_DEF_  "GenMsgILSupport" "No";
BA_DEF_DEF_  "GenMsgNrOfRepetition" 0;
BA_DEF_DEF_  "GenMsgPDUConstants" "";
BA_DEF_DEF_  "GenMsgSendType" "NoMsgSendType";
BA_DEF_DEF_  "GenMsgStartDelayTime" 0;
BA_DEF_DEF_  "NmMessage" "No";
BA_DEF_DEF_  "NmhMessage" "No";
BA_DEF_DEF_  "MsgType" "Application";
BA_DEF_DEF_  "VAGTP20_API" 0;
BA_DEF_DEF_  "VAGTP20_DynConnection" "No";
BA_DEF_DEF_  "VAGTP20_DynSetup" "No";
BA_DEF_DEF_  "VAGTP20_StatConnection" "No";
BA_DEF_DEF_  "CANFD_BRS" "1";
BA_DEF_DEF_  "VFrameFormat" "StandardCAN";
BA_DEF_DEF_  "GenSigActiveRepetitions" 0;
BA_DEF_DEF_  "GenSigInactiveValue" 0;
BA_DEF_DEF_  "GenSigSendType" "NoSigSendType";
BA_DEF_DEF_  "GenSigStartValue" 0;
BA_DEF_DEF_  "NWM-WakeupAllowed" "No";
BA_DEF_DEF_  "GenSigFuncType" "NoFunction";
BA_DEF_DEF_  "GenSigSwitchedByIgnition" "Yes";
BA_DEF_DEF_  "Fehlerwert" 0;
BA_DEF_DEF_  "GenSigMissingSourceValue" 0;
BA_ "GenMsgCycleTime" BO_ 1716 200;
BA_ "GenMsgILSupport" BO_ 1716 1;
BA_ "GenMsgSendType" BO_ 1716 0;
BA_ "CANFD_BRS" BO_ 1716 0;
BA_ "VFrameFormat" BO_ 1716 14;
BA_ "GenMsgCycleTime" BO_ 1057 100;
BA_ "GenMsgDelayTime" BO_ 1057 50;
BA_ "GenMsgILSupport" BO_ 1057 1;
BA_ "GenMsgPDUConstants" BO_ 1057 "0x8e,0x95,0xed,0x45,0x8d,0x80,0x23,0x35,0x30,0x56,0x14,0xf1,0x38,0x42,0xba,0x1d";
BA_ "GenMsgSendType" BO_ 1057 0;
BA_ "CANFD_BRS" BO_ 1057 0;
BA_ "VFrameFormat" BO_ 1057 14;
BA_ "GenMsgCycleTime" BO_ 313 100;
BA_ "GenMsgDelayTime" BO_ 313 20;
BA_ "GenMsgILSupport" BO_ 313 1;
BA_ "GenMsgPDUConstants" BO_ 313 "0x96,0x92,0x95,0xb5,0x6e,0xe3,0xbd,0xb4,0xfa,0xae,0xbe,0xcb,0xcf,0xa5,0x77,0xef";
BA_ "GenMsgSendType" BO_ 313 0;
BA_ "CANFD_BRS" BO_ 313 0;
BA_ "VFrameFormat" BO_ 313 14;
BA_ "GenMsgCycleTime" BO_ 916 160;
BA_ "GenMsgCycleTimeFast" BO_ 916 10;
BA_ "GenMsgDelayTime" BO_ 916 10;
BA_ "GenMsgILSupport" BO_ 916 1;
BA_ "GenMsgNrOfRepetition" BO_ 916 3;
BA_ "GenMsgPDUConstants" BO_ 916 "0x47,0x94,0x92,0x6a,0x67,0xb5,0x0d,0x38,0xe3,0x8a,0x5d,0xb4,0x54,0xab,0xae,0x27";
BA_ "GenMsgSendType" BO_ 916 0;
BA_ "CANFD_BRS" BO_ 916 0;
BA_ "VFrameFormat" BO_ 916 14;
BA_ "GenMsgCycleTime" BO_ 1361 200;
BA_ "GenMsgDelayTime" BO_ 1361 50;
BA_ "GenMsgILSupport" BO_ 1361 1;
BA_ "GenMsgSendType" BO_ 1361 0;
BA_ "CANFD_BRS" BO_ 1361 0;
BA_ "VFrameFormat" BO_ 1361 14;
BA_ "GenMsgCycleTime" BO_ 1369 200;
BA_ "GenMsgDelayTime" BO_ 1369 50;
BA_ "GenMsgSendType" BO_ 1369 0;
BA_ "CANFD_BRS" BO_ 1369 0;
BA_ "VFrameFormat" BO_ 1369 14;
BA_ "CANFD_BRS" BO_ 34 0;
BA_ "VFrameFormat" BO_ 34 14;
BA_ "CANFD_BRS" BO_ 35 0;
BA_ "VFrameFormat" BO_ 35 14;
BA_ "GenMsgCycleTime" BO_ 830 1000;
BA_ "GenMsgDelayTime" BO_ 830 10;
BA_ "GenMsgILSupport" BO_ 830 1;
BA_ "GenMsgSendType" BO_ 830 0;
BA_ "CANFD_BRS" BO_ 830 0;
BA_ "VFrameFormat" BO_ 830 14;
BA_ "GenMsgCycleTime" BO_ 1702 1000;
BA_ "GenMsgDelayTime" BO_ 1702 50;
BA_ "GenMsgILSupport" BO_ 1702 1;
BA_ "GenMsgSendType" BO_ 1702 0;
BA_ "CANFD_BRS" BO_ 1702 0;
BA_ "VFrameFormat" BO_ 1702 14;
BA_ "GenMsgCycleTime" BO_ 2589283611 1000;
BA_ "GenMsgDelayTime" BO_ 2589283611 40;
BA_ "GenMsgILSupport" BO_ 2589283611 1;
BA_ "GenMsgSendType" BO_ 2589283611 0;
BA_ "CANFD_BRS" BO_ 2589283611 0;
BA_ "VFrameFormat" BO_ 2589283611 15;
BA_ "GenMsgCycleTime" BO_ 2527679836 1000;
BA_ "GenMsgDelayTime" BO_ 2527679836 50;
BA_ "GenMsgILSupport" BO_ 2527679836 1;
BA_ "GenMsgSendType" BO_ 2527679836 0;
BA_ "CANFD_BRS" BO_ 2527679836 0;
BA_ "VFrameFormat" BO_ 2527679836 15;
BA_ "GenMsgCycleTime" BO_ 2527679837 1000;
BA_ "GenMsgDelayTime" BO_ 2527679837 50;
BA_ "GenMsgILSupport" BO_ 2527679837 1;
BA_ "GenMsgSendType" BO_ 2527679837 0;
BA_ "CANFD_BRS" BO_ 2527679837 0;
BA_ "VFrameFormat" BO_ 2527679837 15;
BA_ "GenMsgCycleTime" BO_ 2463978688 200;
BA_ "GenMsgDelayTime" BO_ 2463978688 20;
BA_ "GenMsgILSupport" BO_ 2463978688 1;
BA_ "GenMsgSendType" BO_ 2463978688 0;
BA_ "CANFD_BRS" BO_ 2463978688 0;
BA_ "VFrameFormat" BO_ 2463978688 15;
BA_ "GenMsgCycleTime" BO_ 2463978854 200;
BA_ "GenMsgDelayTime" BO_ 2463978854 20;
BA_ "GenMsgILSupport" BO_ 2463978854 1;
BA_ "GenMsgSendType" BO_ 2463978854 0;
BA_ "CANFD_BRS" BO_ 2463978854 0;
BA_ "VFrameFormat" BO_ 2463978854 15;
BA_ "GenMsgCycleTime" BO_ 1140 1000;
BA_ "GenMsgDelayTime" BO_ 1140 40;
BA_ "GenMsgILSupport" BO_ 1140 1;
BA_ "GenMsgSendType" BO_ 1140 0;
BA_ "CANFD_BRS" BO_ 1140 0;
BA_ "VFrameFormat" BO_ 1140 14;
BA_ "GenMsgCycleTime" BO_ 2589284130 1000;
BA_ "GenMsgDelayTime" BO_ 2589284130 100;
BA_ "GenMsgILSupport" BO_ 2589284130 1;
BA_ "GenMsgSendType" BO_ 2589284130 0;
BA_ "CANFD_BRS" BO_ 2589284130 0;
BA_ "VFrameFormat" BO_ 2589284130 15;
BA_ "GenMsgCycleTimeFast" BO_ 389 40;
BA_ "GenMsgDelayTime" BO_ 389 10;
BA_ "GenMsgILSupport" BO_ 389 1;
BA_ "GenMsgNrOfRepetition" BO_ 389 5;
BA_ "GenMsgSendType" BO_ 389 7;
BA_ "CANFD_BRS" BO_ 389 0;
BA_ "VFrameFormat" BO_ 389 14;
BA_ "GenMsgCycleTime" BO_ 388 1000;
BA_ "GenMsgCycleTimeFast" BO_ 388 20;
BA_ "GenMsgILSupport" BO_ 388 1;
BA_ "GenMsgNrOfRepetition" BO_ 388 5;
BA_ "GenMsgPDUConstants" BO_ 388 "0xe3,0xe8,0xc4,0x7f,0xf1,0x95,0xd8,0xb0,0xc7,0xa3,0xf4,0x6c,0xe7,0xc3,0x5a,0xf7";
BA_ "GenMsgSendType" BO_ 388 0;
BA_ "CANFD_BRS" BO_ 388 0;
BA_ "VFrameFormat" BO_ 388 14;
BA_ "GenMsgCycleTime" BO_ 1411 200;
BA_ "GenMsgCycleTimeFast" BO_ 1411 50;
BA_ "GenMsgDelayTime" BO_ 1411 20;
BA_ "GenMsgILSupport" BO_ 1411 1;
BA_ "GenMsgNrOfRepetition" BO_ 1411 3;
BA_ "GenMsgSendType" BO_ 1411 0;
BA_ "CANFD_BRS" BO_ 1411 0;
BA_ "VFrameFormat" BO_ 1411 14;
BA_ "GenMsgCycleTime" BO_ 708 500;
BA_ "GenMsgCycleTimeFast" BO_ 708 20;
BA_ "GenMsgDelayTime" BO_ 708 10;
BA_ "GenMsgILSupport" BO_ 708 1;
BA_ "GenMsgNrOfRepetition" BO_ 708 5;
BA_ "GenMsgPDUConstants" BO_ 708 "0x27,0x23,0xf6,0x9b,0x88,0x5f,0x4d,0xcd,0xe1,0x34,0xaa,0x81,0x11,0xc6,0x21,0x0a";
BA_ "GenMsgSendType" BO_ 708 0;
BA_ "CANFD_BRS" BO_ 708 0;
BA_ "VFrameFormat" BO_ 708 14;
BA_ "GenSigSwitchedByIgnition" SG_ 1716 KS_Geheimnis_1 0;
BA_ "GenSigSwitchedByIgnition" SG_ 1716 KS_Geheimnis_2 0;
BA_ "GenSigSwitchedByIgnition" SG_ 1716 KS_Geheimnis_3 0;
BA_ "GenSigSwitchedByIgnition" SG_ 1716 KS_Geheimnis_4 0;
BA_ "GenSigSendType" SG_ 1716 VIN_01_MUX 0;
BA_ "GenSigSwitchedByIgnition" SG_ 1716 VIN_01_MUX 0;
BA_ "GenSigStartValue" SG_ 1716 VIN_1 45;
BA_ "GenSigSwitchedByIgnition" SG_ 1716 VIN_1 0;
BA_ "GenSigStartValue" SG_ 1716 VIN_10 45;
BA_ "GenSigSwitchedByIgnition" SG_ 1716 VIN_10 0;
BA_ "GenSigStartValue" SG_ 1716 VIN_11 45;
BA_ "GenSigSwitchedByIgnition" SG_ 1716 VIN_11 0;
BA_ "GenSigStartValue" SG_ 1716 VIN_12 45;
BA_ "GenSigSwitchedByIgnition" SG_ 1716 VIN_12 0;
BA_ "GenSigStartValue" SG_ 1716 VIN_13 45;
BA_ "GenSigSwitchedByIgnition" SG_ 1716 VIN_13 0;
BA_ "GenSigStartValue" SG_ 1716 VIN_14 45;
BA_ "GenSigSwitchedByIgnition" SG_ 1716 VIN_14 0;
BA_ "GenSigStartValue" SG_ 1716 VIN_15 45;
BA_ "GenSigSwitchedByIgnition" SG_ 1716 VIN_15 0;
BA_ "GenSigStartValue" SG_ 1716 VIN_16 45;
BA_ "GenSigSwitchedByIgnition" SG_ 1716 VIN_16 0;
BA_ "GenSigStartValue" SG_ 1716 VIN_17 45;
BA_ "GenSigSwitchedByIgnition" SG_ 1716 VIN_17 0;
BA_ "GenSigStartValue" SG_ 1716 VIN_2 45;
BA_ "GenSigSwitchedByIgnition" SG_ 1716 VIN_2 0;
BA_ "GenSigStartValue" SG_ 1716 VIN_3 45;
BA_ "GenSigSwitchedByIgnition" SG_ 1716 VIN_3 0;
BA_ "GenSigStartValue" SG_ 1716 VIN_4 45;
BA_ "GenSigSwitchedByIgnition" SG_ 1716 VIN_4 0;
BA_ "GenSigStartValue" SG_ 1716 VIN_5 45;
BA_ "GenSigSwitchedByIgnition" SG_ 1716 VIN_5 0;
BA_ "GenSigStartValue" SG_ 1716 VIN_6 45;
BA_ "GenSigSwitchedByIgnition" SG_ 1716 VIN_6 0;
BA_ "GenSigStartValue" SG_ 1716 VIN_7 45;
BA_ "GenSigSwitchedByIgnition" SG_ 1716 VIN_7 0;
BA_ "GenSigStartValue" SG_ 1716 VIN_8 45;
BA_ "GenSigSwitchedByIgnition" SG_ 1716 VIN_8 0;
BA_ "GenSigStartValue" SG_ 1716 VIN_9 45;
BA_ "GenSigSwitchedByIgnition" SG_ 1716 VIN_9 0;
BA_ "GenSigSendType" SG_ 1057 VLK_01_BZ 0;
BA_ "GenSigFuncType" SG_ 1057 VLK_01_BZ 1;
BA_ "GenSigSwitchedByIgnition" SG_ 1057 VLK_01_BZ 0;
BA_ "GenSigSendType" SG_ 1057 VLK_01_CRC 0;
BA_ "GenSigFuncType" SG_ 1057 VLK_01_CRC 2;
BA_ "GenSigSwitchedByIgnition" SG_ 1057 VLK_01_CRC 0;
BA_ "GenSigSendType" SG_ 1057 VLK_Anf_Antrieb 3;
BA_ "GenSigSwitchedByIgnition" SG_ 1057 VLK_Anf_Antrieb 0;
BA_ "Fehlerwert" SG_ 1057 VLK_Anf_Antrieb 7;
BA_ "GenSigSendType" SG_ 1057 VLK_Anforderung_HMS 3;
BA_ "GenSigSwitchedByIgnition" SG_ 1057 VLK_Anforderung_HMS 0;
BA_ "GenSigSendType" SG_ 1057 VLK_Anforderung_Rollfaehigkeit 0;
BA_ "GenSigSwitchedByIgnition" SG_ 1057 VLK_Anforderung_Rollfaehigkeit 0;
BA_ "GenSigSendType" SG_ 1057 VLK_Antriebsdeaktivierung 3;
BA_ "GenSigSwitchedByIgnition" SG_ 1057 VLK_Antriebsdeaktivierung 0;
BA_ "Fehlerwert" SG_ 1057 VLK_Antriebsdeaktivierung 3;
BA_ "GenSigSendType" SG_ 1057 VLK_autom_Absch_Signalisierung 0;
BA_ "GenSigSwitchedByIgnition" SG_ 1057 VLK_autom_Absch_Signalisierung 0;
BA_ "GenSigSendType" SG_ 1057 VLK_Hinweis_dgr_VLW 3;
BA_ "GenSigSwitchedByIgnition" SG_ 1057 VLK_Hinweis_dgr_VLW 0;
BA_ "GenSigSendType" SG_ 1057 VLK_Hinweis_Fehler_Gurt 3;
BA_ "GenSigSwitchedByIgnition" SG_ 1057 VLK_Hinweis_Fehler_Gurt 0;
BA_ "GenSigSendType" SG_ 1057 VLK_Hinweis_Fehler_Sitz 3;
BA_ "GenSigSwitchedByIgnition" SG_ 1057 VLK_Hinweis_Fehler_Sitz 0;
BA_ "GenSigSendType" SG_ 1057 VLK_Hinweis_Fehler_Tuer 3;
BA_ "GenSigSwitchedByIgnition" SG_ 1057 VLK_Hinweis_Fehler_Tuer 0;
BA_ "GenSigSendType" SG_ 1057 VLK_Hinweis_KA_bevorstehend 3;
BA_ "GenSigSwitchedByIgnition" SG_ 1057 VLK_Hinweis_KA_bevorstehend 0;
BA_ "GenSigSendType" SG_ 1057 VLK_Hinweis_Rollfaehigkeit 3;
BA_ "GenSigSwitchedByIgnition" SG_ 1057 VLK_Hinweis_Rollfaehigkeit 0;
BA_ "GenSigSendType" SG_ 1057 VLK_Hinweis_Weiterfahrt 3;
BA_ "GenSigSwitchedByIgnition" SG_ 1057 VLK_Hinweis_Weiterfahrt 0;
BA_ "GenSigSendType" SG_ 1057 VLK_Parken_beibehalten_HMS 3;
BA_ "GenSigStartValue" SG_ 1057 VLK_Parken_beibehalten_HMS 2;
BA_ "GenSigSwitchedByIgnition" SG_ 1057 VLK_Parken_beibehalten_HMS 0;
BA_ "Fehlerwert" SG_ 1057 VLK_Parken_beibehalten_HMS 3;
BA_ "GenSigSendType" SG_ 1057 VLK_VLW_Anf 3;
BA_ "GenSigSwitchedByIgnition" SG_ 1057 VLK_VLW_Anf 0;
BA_ "GenSigSendType" SG_ 313 HMS_aktives_System 3;
BA_ "GenSigSwitchedByIgnition" SG_ 313 HMS_aktives_System 0;
BA_ "GenSigSendType" SG_ 313 HMS_Anforderung_GE 0;
BA_ "GenSigSwitchedByIgnition" SG_ 313 HMS_Anforderung_GE 0;
BA_ "GenSigSendType" SG_ 313 HMS_Fehlerstatus 0;
BA_ "GenSigSwitchedByIgnition" SG_ 313 HMS_Fehlerstatus 0;
BA_ "GenSigSendType" SG_ 313 HMS_Haltemoment 0;
BA_ "GenSigStartValue" SG_ 313 HMS_Haltemoment 1022;
BA_ "GenSigSwitchedByIgnition" SG_ 313 HMS_Haltemoment 0;
BA_ "Fehlerwert" SG_ 313 HMS_Haltemoment 1023;
BA_ "GenSigSendType" SG_ 313 HMS_halten_nicht_verfuegbar 0;
BA_ "GenSigSwitchedByIgnition" SG_ 313 HMS_halten_nicht_verfuegbar 0;
BA_ "GenSigSendType" SG_ 313 HMS_halten_nicht_verfuegbar_02 0;
BA_ "GenSigSwitchedByIgnition" SG_ 313 HMS_halten_nicht_verfuegbar_02 0;
BA_ "GenSigSendType" SG_ 313 HMS_Index_Haltemoment 0;
BA_ "GenSigSwitchedByIgnition" SG_ 313 HMS_Index_Haltemoment 0;
BA_ "GenSigSendType" SG_ 313 HMS_P_beibehalten_GE 0;
BA_ "GenSigStartValue" SG_ 313 HMS_P_beibehalten_GE 2;
BA_ "GenSigSwitchedByIgnition" SG_ 313 HMS_P_beibehalten_GE 0;
BA_ "Fehlerwert" SG_ 313 HMS_P_beibehalten_GE 3;
BA_ "GenSigSendType" SG_ 313 HMS_parken_nicht_verfuegbar 0;
BA_ "GenSigSwitchedByIgnition" SG_ 313 HMS_parken_nicht_verfuegbar 0;
BA_ "GenSigSendType" SG_ 313 HMS_Stillstand 0;
BA_ "GenSigStartValue" SG_ 313 HMS_Stillstand 6;
BA_ "GenSigSwitchedByIgnition" SG_ 313 HMS_Stillstand 0;
BA_ "Fehlerwert" SG_ 313 HMS_Stillstand 7;
BA_ "GenSigSendType" SG_ 313 HMS_Systemstatus 3;
BA_ "GenSigStartValue" SG_ 313 HMS_Systemstatus 14;
BA_ "GenSigSwitchedByIgnition" SG_ 313 HMS_Systemstatus 0;
BA_ "Fehlerwert" SG_ 313 HMS_Systemstatus 15;
BA_ "GenSigSendType" SG_ 313 SOK_VMM_02_Signatur 0;
BA_ "GenSigFuncType" SG_ 313 SOK_VMM_02_Signatur 15;
BA_ "GenSigSendType" SG_ 313 VMM_02_BZ 0;
BA_ "GenSigFuncType" SG_ 313 VMM_02_BZ 1;
BA_ "GenSigSwitchedByIgnition" SG_ 313 VMM_02_BZ 0;
BA_ "GenSigSendType" SG_ 313 VMM_02_CRC 0;
BA_ "GenSigFuncType" SG_ 313 VMM_02_CRC 2;
BA_ "GenSigSwitchedByIgnition" SG_ 313 VMM_02_CRC 0;
BA_ "GenSigSendType" SG_ 313 VMM_Bremslicht_defekt 0;
BA_ "GenSigSwitchedByIgnition" SG_ 313 VMM_Bremslicht_defekt 0;
BA_ "GenSigSendType" SG_ 313 VMM_Bremslicht_unplausibel 0;
BA_ "GenSigSwitchedByIgnition" SG_ 313 VMM_Bremslicht_unplausibel 0;
BA_ "GenSigSendType" SG_ 313 VMM_Fahrer_Bremskraft_bestimmend 0;
BA_ "GenSigSwitchedByIgnition" SG_ 313 VMM_Fahrer_Bremskraft_bestimmend 0;
BA_ "GenSigSendType" SG_ 313 VMM_Inkonsistenz_ACC 0;
BA_ "GenSigSwitchedByIgnition" SG_ 313 VMM_Inkonsistenz_ACC 0;
BA_ "GenSigSendType" SG_ 313 VMM_Inkonsistenz_AEB 0;
BA_ "GenSigSwitchedByIgnition" SG_ 313 VMM_Inkonsistenz_AEB 0;
BA_ "GenSigSendType" SG_ 313 VMM_Inkonsistenz_ARA 0;
BA_ "GenSigSwitchedByIgnition" SG_ 313 VMM_Inkonsistenz_ARA 0;
BA_ "GenSigSendType" SG_ 313 VMM_Inkonsistenz_AWV_PCF 0;
BA_ "GenSigSwitchedByIgnition" SG_ 313 VMM_Inkonsistenz_AWV_PCF 0;
BA_ "GenSigSendType" SG_ 313 VMM_Inkonsistenz_EA 0;
BA_ "GenSigSwitchedByIgnition" SG_ 313 VMM_Inkonsistenz_EA 0;
BA_ "GenSigSendType" SG_ 313 VMM_Inkonsistenz_EBKV 0;
BA_ "GenSigSwitchedByIgnition" SG_ 313 VMM_Inkonsistenz_EBKV 0;
BA_ "GenSigSendType" SG_ 313 VMM_Inkonsistenz_FAS_VK 0;
BA_ "GenSigSwitchedByIgnition" SG_ 313 VMM_Inkonsistenz_FAS_VK 0;
BA_ "GenSigSendType" SG_ 313 VMM_Inkonsistenz_GE 0;
BA_ "GenSigSwitchedByIgnition" SG_ 313 VMM_Inkonsistenz_GE 0;
BA_ "GenSigSendType" SG_ 313 VMM_Inkonsistenz_HVLM 0;
BA_ "GenSigSwitchedByIgnition" SG_ 313 VMM_Inkonsistenz_HVLM 0;
BA_ "GenSigSendType" SG_ 313 VMM_Inkonsistenz_KAM 0;
BA_ "GenSigSwitchedByIgnition" SG_ 313 VMM_Inkonsistenz_KAM 0;
BA_ "GenSigSendType" SG_ 313 VMM_Inkonsistenz_KAS 0;
BA_ "GenSigSwitchedByIgnition" SG_ 313 VMM_Inkonsistenz_KAS 0;
BA_ "GenSigSendType" SG_ 313 VMM_Inkonsistenz_MO 0;
BA_ "GenSigSwitchedByIgnition" SG_ 313 VMM_Inkonsistenz_MO 0;
BA_ "GenSigSendType" SG_ 313 VMM_Inkonsistenz_NV 0;
BA_ "GenSigSwitchedByIgnition" SG_ 313 VMM_Inkonsistenz_NV 0;
BA_ "GenSigSendType" SG_ 313 VMM_Inkonsistenz_ParkAssist 0;
BA_ "GenSigSwitchedByIgnition" SG_ 313 VMM_Inkonsistenz_ParkAssist 0;
BA_ "GenSigSendType" SG_ 313 VMM_Inkonsistenz_RCTA 0;
BA_ "GenSigSwitchedByIgnition" SG_ 313 VMM_Inkonsistenz_RCTA 0;
BA_ "GenSigSendType" SG_ 313 VMM_Inkonsistenz_RHP 0;
BA_ "GenSigSwitchedByIgnition" SG_ 313 VMM_Inkonsistenz_RHP 0;
BA_ "GenSigSendType" SG_ 313 VMM_Inkonsistenz_TSK 0;
BA_ "GenSigSwitchedByIgnition" SG_ 313 VMM_Inkonsistenz_TSK 0;
BA_ "GenSigSendType" SG_ 313 VMM_Inkonsistenz_VLK 3;
BA_ "GenSigSwitchedByIgnition" SG_ 313 VMM_Inkonsistenz_VLK 0;
BA_ "GenSigSendType" SG_ 313 VMM_MKB_codiert 0;
BA_ "GenSigSwitchedByIgnition" SG_ 313 VMM_MKB_codiert 0;
BA_ "GenSigSendType" SG_ 313 VMM_Notstopp_Status 0;
BA_ "GenSigSwitchedByIgnition" SG_ 313 VMM_Notstopp_Status 0;
BA_ "Fehlerwert" SG_ 313 VMM_Notstopp_Status 7;
BA_ "GenSigSendType" SG_ 313 VZM_aktiver_Basisservice 0;
BA_ "GenSigSwitchedByIgnition" SG_ 313 VZM_aktiver_Basisservice 0;
BA_ "GenSigSendType" SG_ 313 VZM_aktives_System 0;
BA_ "GenSigSwitchedByIgnition" SG_ 313 VZM_aktives_System 0;
BA_ "GenSigSendType" SG_ 313 VZM_Anhalteweg_nicht_verfuegbar 0;
BA_ "GenSigSwitchedByIgnition" SG_ 313 VZM_Anhalteweg_nicht_verfuegbar 0;
BA_ "GenSigSendType" SG_ 313 VZM_Bkd_nicht_verfuegbar 0;
BA_ "GenSigSwitchedByIgnition" SG_ 313 VZM_Bkd_nicht_verfuegbar 0;
BA_ "GenSigSendType" SG_ 313 VZM_Fahrer_bremst 0;
BA_ "GenSigSwitchedByIgnition" SG_ 313 VZM_Fahrer_bremst 0;
BA_ "GenSigSendType" SG_ 313 VZM_Fahrer_bremst_deutlich 0;
BA_ "GenSigSwitchedByIgnition" SG_ 313 VZM_Fahrer_bremst_deutlich 0;
BA_ "GenSigSendType" SG_ 313 VZM_QBit_Fahrer_bremst 0;
BA_ "GenSigStartValue" SG_ 313 VZM_QBit_Fahrer_bremst 1;
BA_ "GenSigSwitchedByIgnition" SG_ 313 VZM_QBit_Fahrer_bremst 0;
BA_ "GenSigSendType" SG_ 313 VZM_SRBM_Ist 0;
BA_ "GenSigStartValue" SG_ 313 VZM_SRBM_Ist 4094;
BA_ "GenSigSwitchedByIgnition" SG_ 313 VZM_SRBM_Ist 0;
BA_ "Fehlerwert" SG_ 313 VZM_SRBM_Ist 4095;
BA_ "GenSigSendType" SG_ 313 VZM_SRBM_max_Gradient 0;
BA_ "GenSigStartValue" SG_ 313 VZM_SRBM_max_Gradient 126;
BA_ "GenSigSwitchedByIgnition" SG_ 313 VZM_SRBM_max_Gradient 0;
BA_ "Fehlerwert" SG_ 313 VZM_SRBM_max_Gradient 127;
BA_ "GenSigSendType" SG_ 313 VZM_SRBM_Soll 0;
BA_ "GenSigStartValue" SG_ 313 VZM_SRBM_Soll 4094;
BA_ "GenSigSwitchedByIgnition" SG_ 313 VZM_SRBM_Soll 0;
BA_ "Fehlerwert" SG_ 313 VZM_SRBM_Soll 4095;
BA_ "GenSigSendType" SG_ 313 VZM_Status_Wegregelung 0;
BA_ "GenSigSwitchedByIgnition" SG_ 313 VZM_Status_Wegregelung 0;
BA_ "GenSigSendType" SG_ 313 VZM_Systemstatus 0;
BA_ "GenSigSwitchedByIgnition" SG_ 313 VZM_Systemstatus 0;
BA_ "Fehlerwert" SG_ 313 VZM_Systemstatus 4;
BA_ "GenSigSendType" SG_ 313 VZM_TSK_SRBM_Anf 0;
BA_ "GenSigSwitchedByIgnition" SG_ 313 VZM_TSK_SRBM_Anf 0;
BA_ "GenSigSendType" SG_ 313 VZM_TSK_SRBM_nicht_verfuegbar 0;
BA_ "GenSigSwitchedByIgnition" SG_ 313 VZM_TSK_SRBM_nicht_verfuegbar 0;
BA_ "GenSigSendType" SG_ 313 VZM_Unterdrueckung_Antriebsmom 0;
BA_ "GenSigSwitchedByIgnition" SG_ 313 VZM_Unterdrueckung_Antriebsmom 0;
BA_ "GenSigSendType" SG_ 313 VZM_Verz_ASIL_Verfuegbarkeit 0;
BA_ "GenSigSwitchedByIgnition" SG_ 313 VZM_Verz_ASIL_Verfuegbarkeit 0;
BA_ "GenSigSendType" SG_ 313 VZM_Verz_Begrenzung 0;
BA_ "GenSigSwitchedByIgnition" SG_ 313 VZM_Verz_Begrenzung 0;
BA_ "GenSigSendType" SG_ 313 VZM_Verz_Reg_aktiv 0;
BA_ "GenSigSwitchedByIgnition" SG_ 313 VZM_Verz_Reg_aktiv 0;
BA_ "GenSigSendType" SG_ 313 VZM_Verz_Reg_nicht_verfuegbar 0;
BA_ "GenSigSwitchedByIgnition" SG_ 313 VZM_Verz_Reg_nicht_verfuegbar 0;
BA_ "GenSigSendType" SG_ 313 VZM_Warnruck_nicht_verfuegbar 0;
BA_ "GenSigSwitchedByIgnition" SG_ 313 VZM_Warnruck_nicht_verfuegbar 0;
BA_ "GenSigSendType" SG_ 313 VZM_Warnruckeln_nicht_verfuegbar 0;
BA_ "GenSigSwitchedByIgnition" SG_ 313 VZM_Warnruckeln_nicht_verfuegbar 0;
BA_ "GenSigSendType" SG_ 916 GE_Sollgang 4;
BA_ "GenSigSwitchedByIgnition" SG_ 916 GE_Sollgang 0;
BA_ "GenSigSendType" SG_ 916 GE_Stoppverbot_Anz_01 0;
BA_ "GenSigSwitchedByIgnition" SG_ 916 GE_Stoppverbot_Anz_01 0;
BA_ "GenSigSendType" SG_ 916 GE_Stoppverbot_Anz_02 0;
BA_ "GenSigSwitchedByIgnition" SG_ 916 GE_Stoppverbot_Anz_02 0;
BA_ "GenSigSendType" SG_ 916 GE_Stoppverbot_Anz_03 0;
BA_ "GenSigSwitchedByIgnition" SG_ 916 GE_Stoppverbot_Anz_03 0;
BA_ "GenSigSendType" SG_ 916 GE_Stoppverbot_Anz_04 0;
BA_ "GenSigSwitchedByIgnition" SG_ 916 GE_Stoppverbot_Anz_04 0;
BA_ "GenSigSendType" SG_ 916 GE_Stoppverbot_Anz_05 0;
BA_ "GenSigSwitchedByIgnition" SG_ 916 GE_Stoppverbot_Anz_05 0;
BA_ "GenSigSendType" SG_ 916 GE_Stoppverbot_Anz_06 0;
BA_ "GenSigSwitchedByIgnition" SG_ 916 GE_Stoppverbot_Anz_06 0;
BA_ "GenSigSendType" SG_ 916 GE_Stoppverbot_Anz_07 0;
BA_ "GenSigSwitchedByIgnition" SG_ 916 GE_Stoppverbot_Anz_07 0;
BA_ "GenSigSendType" SG_ 916 GE_Stoppverbot_Anz_Std 0;
BA_ "GenSigSwitchedByIgnition" SG_ 916 GE_Stoppverbot_Anz_Std 0;
BA_ "GenSigSendType" SG_ 916 GE_Tipschaltempf_verfuegbar 0;
BA_ "GenSigFuncType" SG_ 916 GE_Tipschaltempf_verfuegbar 8;
BA_ "GenSigSwitchedByIgnition" SG_ 916 GE_Tipschaltempf_verfuegbar 0;
BA_ "GenSigSendType" SG_ 916 GE_Wiederstart_Anz_Std 0;
BA_ "GenSigSwitchedByIgnition" SG_ 916 GE_Wiederstart_Anz_Std 0;
BA_ "GenSigSendType" SG_ 916 WBA_03_BZ 0;
BA_ "GenSigFuncType" SG_ 916 WBA_03_BZ 1;
BA_ "GenSigSwitchedByIgnition" SG_ 916 WBA_03_BZ 0;
BA_ "GenSigSendType" SG_ 916 WBA_03_CRC 0;
BA_ "GenSigFuncType" SG_ 916 WBA_03_CRC 2;
BA_ "GenSigSwitchedByIgnition" SG_ 916 WBA_03_CRC 0;
BA_ "GenSigSendType" SG_ 916 WBA_Anforderung_Akustik 4;
BA_ "GenSigSwitchedByIgnition" SG_ 916 WBA_Anforderung_Akustik 0;
BA_ "GenSigSendType" SG_ 916 WBA_Blinken 3;
BA_ "GenSigSwitchedByIgnition" SG_ 916 WBA_Blinken 0;
BA_ "GenSigSendType" SG_ 916 WBA_eing_Gang_02 4;
BA_ "GenSigSwitchedByIgnition" SG_ 916 WBA_eing_Gang_02 0;
BA_ "GenSigSendType" SG_ 916 WBA_Fahrstufe_02 4;
BA_ "GenSigSwitchedByIgnition" SG_ 916 WBA_Fahrstufe_02 0;
BA_ "GenSigSendType" SG_ 916 WBA_GE_Texte 4;
BA_ "GenSigSwitchedByIgnition" SG_ 916 WBA_GE_Texte 0;
BA_ "GenSigSendType" SG_ 916 WBA_GE_Texte_02 0;
BA_ "GenSigSwitchedByIgnition" SG_ 916 WBA_GE_Texte_02 0;
BA_ "GenSigSendType" SG_ 916 WBA_GE_Warnung_02 4;
BA_ "GenSigSwitchedByIgnition" SG_ 916 WBA_GE_Warnung_02 0;
BA_ "GenSigSendType" SG_ 916 WBA_GE_Zusatzwarnungen 4;
BA_ "GenSigSwitchedByIgnition" SG_ 916 WBA_GE_Zusatzwarnungen 0;
BA_ "GenSigSendType" SG_ 916 WBA_Schaltschema_02 4;
BA_ "GenSigSwitchedByIgnition" SG_ 916 WBA_Schaltschema_02 0;
BA_ "GenSigSendType" SG_ 916 WBA_Schaltschema_Fahreraktion 4;
BA_ "GenSigSwitchedByIgnition" SG_ 916 WBA_Schaltschema_Fahreraktion 0;
BA_ "GenSigSendType" SG_ 916 WBA_Schaltschema_FS_inaktiv 4;
BA_ "GenSigSwitchedByIgnition" SG_ 916 WBA_Schaltschema_FS_inaktiv 0;
BA_ "GenSigSendType" SG_ 916 WBA_Schaltschema_FS_vorwaerts 4;
BA_ "GenSigSwitchedByIgnition" SG_ 916 WBA_Schaltschema_FS_vorwaerts 0;
BA_ "GenSigSendType" SG_ 916 WBA_Schaltschema_Tippgasse 4;
BA_ "GenSigSwitchedByIgnition" SG_ 916 WBA_Schaltschema_Tippgasse 0;
BA_ "GenSigSendType" SG_ 916 WBA_Segeln_aktiv 4;
BA_ "GenSigSwitchedByIgnition" SG_ 916 WBA_Segeln_aktiv 0;
BA_ "GenSigSendType" SG_ 916 WBA_Shiftlock_Lampe 4;
BA_ "GenSigSwitchedByIgnition" SG_ 916 WBA_Shiftlock_Lampe 0;
BA_ "GenSigSendType" SG_ 916 WBA_ZielFahrstufe 3;
BA_ "GenSigSwitchedByIgnition" SG_ 916 WBA_ZielFahrstufe 0;
BA_ "GenSigSendType" SG_ 1361 WFS_Betrieb_Lesespule 3;
BA_ "GenSigSwitchedByIgnition" SG_ 1361 WFS_Betrieb_Lesespule 0;
BA_ "GenSigSendType" SG_ 1361 WFS_ELV_authorisiert 3;
BA_ "GenSigSwitchedByIgnition" SG_ 1361 WFS_ELV_authorisiert 0;
BA_ "GenSigSendType" SG_ 1361 WFS_Fahrerhinweise 3;
BA_ "GenSigSwitchedByIgnition" SG_ 1361 WFS_Fahrerhinweise 0;
BA_ "GenSigSendType" SG_ 1361 WFS_ID_Geb_autorisiert 3;
BA_ "GenSigSwitchedByIgnition" SG_ 1361 WFS_ID_Geb_autorisiert 0;
BA_ "GenSigSendType" SG_ 1361 WFS_ID_Geb_autorisiert_in_Kl15 3;
BA_ "GenSigSwitchedByIgnition" SG_ 1361 WFS_ID_Geb_autorisiert_in_Kl15 0;
BA_ "GenSigSendType" SG_ 1361 WFS_ID_Geb_steckt 3;
BA_ "GenSigSwitchedByIgnition" SG_ 1361 WFS_ID_Geb_steckt 0;
BA_ "GenSigSendType" SG_ 1361 WFS_Klemmenfreigabe 3;
BA_ "GenSigSwitchedByIgnition" SG_ 1361 WFS_Klemmenfreigabe 0;
BA_ "GenSigSendType" SG_ 1361 WFS_Klemmenfreigabe_Signatur 3;
BA_ "GenSigSwitchedByIgnition" SG_ 1361 WFS_Klemmenfreigabe_Signatur 0;
BA_ "GenSigSendType" SG_ 1361 WFS_LF_Aktiv 3;
BA_ "GenSigSwitchedByIgnition" SG_ 1361 WFS_LF_Aktiv 0;
BA_ "GenSigSendType" SG_ 1361 WFS_LZ 3;
BA_ "GenSigSwitchedByIgnition" SG_ 1361 WFS_LZ 0;
BA_ "GenSigSendType" SG_ 1361 WFS_Parken_Status 3;
BA_ "GenSigSwitchedByIgnition" SG_ 1361 WFS_Parken_Status 0;
BA_ "GenSigSendType" SG_ 1361 WFS_Safe 3;
BA_ "GenSigSwitchedByIgnition" SG_ 1361 WFS_Safe 0;
BA_ "GenSigSendType" SG_ 1361 WFS_Schluessel_Fahrberecht 0;
BA_ "GenSigSwitchedByIgnition" SG_ 1361 WFS_Schluessel_Fahrberecht 0;
BA_ "GenSigSendType" SG_ 1361 WFS_Schluessel_Ist 3;
BA_ "GenSigSwitchedByIgnition" SG_ 1361 WFS_Schluessel_Ist 0;
BA_ "GenSigSendType" SG_ 1361 WFS_Schluessel_Soll 3;
BA_ "GenSigSwitchedByIgnition" SG_ 1361 WFS_Schluessel_Soll 0;
BA_ "GenSigSendType" SG_ 1361 WFS_Verbauinfo_ELV 3;
BA_ "GenSigSwitchedByIgnition" SG_ 1361 WFS_Verbauinfo_ELV 0;
BA_ "GenSigSendType" SG_ 1369 SOK_WFS01_Signatur 3;
BA_ "GenSigFuncType" SG_ 1369 SOK_WFS01_Signatur 15;
BA_ "GenSigSwitchedByIgnition" SG_ 1369 SOK_WFS01_Signatur 0;
BA_ "GenSigSendType" SG_ 34 WFS_Transponder_Req_02_Data 1;
BA_ "GenSigFuncType" SG_ 34 WFS_Transponder_Req_02_Data 9;
BA_ "GenSigSwitchedByIgnition" SG_ 34 WFS_Transponder_Req_02_Data 0;
BA_ "GenSigSendType" SG_ 35 WFS_Transponder_Resp_02_Data 3;
BA_ "GenSigFuncType" SG_ 35 WFS_Transponder_Resp_02_Data 9;
BA_ "GenSigSwitchedByIgnition" SG_ 35 WFS_Transponder_Resp_02_Data 0;
BA_ "GenSigSendType" SG_ 830 WFS_Diag_LF_Aktiv_02 3;
BA_ "GenSigSwitchedByIgnition" SG_ 830 WFS_Diag_LF_Aktiv_02 0;
BA_ "GenSigSendType" SG_ 830 WFS_LF_aktiv_02 3;
BA_ "GenSigSwitchedByIgnition" SG_ 830 WFS_LF_aktiv_02 0;
BA_ "GenSigSendType" SG_ 830 WFS_Transp_Mod_Unterbrechung_02 3;
BA_ "GenSigSwitchedByIgnition" SG_ 830 WFS_Transp_Mod_Unterbrechung_02 0;
BA_ "GenSigSendType" SG_ 830 WFS_Verbau_Transp_Ant_02 3;
BA_ "GenSigSwitchedByIgnition" SG_ 830 WFS_Verbau_Transp_Ant_02 0;
BA_ "GenSigSendType" SG_ 1702 BCM1_SRA_aktiv 3;
BA_ "GenSigSwitchedByIgnition" SG_ 1702 BCM1_SRA_aktiv 0;
BA_ "GenSigActiveRepetitions" SG_ 1702 Heckwischer_Anforderung 3;
BA_ "GenSigSendType" SG_ 1702 Heckwischer_Anforderung 4;
BA_ "GenSigSwitchedByIgnition" SG_ 1702 Heckwischer_Anforderung 0;
BA_ "GenSigSendType" SG_ 1702 Waschen_vorne_aktiv 3;
BA_ "GenSigSwitchedByIgnition" SG_ 1702 Waschen_vorne_aktiv 0;
BA_ "GenSigSendType" SG_ 1702 Wischer1_Wischgeschwindigkeit 0;
BA_ "GenSigStartValue" SG_ 1702 Wischer1_Wischgeschwindigkeit 62;
BA_ "GenSigSwitchedByIgnition" SG_ 1702 Wischer1_Wischgeschwindigkeit 0;
BA_ "Fehlerwert" SG_ 1702 Wischer1_Wischgeschwindigkeit 63;
BA_ "GenSigSendType" SG_ 1702 Wischer_Anzeigetext 3;
BA_ "GenSigSwitchedByIgnition" SG_ 1702 Wischer_Anzeigetext 0;
BA_ "GenSigSendType" SG_ 1702 Wischer_vorne_aktiv 3;
BA_ "GenSigSwitchedByIgnition" SG_ 1702 Wischer_vorne_aktiv 0;
BA_ "GenSigSendType" SG_ 1702 Wischer_vorne_blockiert 3;
BA_ "GenSigSwitchedByIgnition" SG_ 1702 Wischer_vorne_blockiert 0;
BA_ "GenSigSendType" SG_ 1702 Wischer_vorne_defekt 3;
BA_ "GenSigSwitchedByIgnition" SG_ 1702 Wischer_vorne_defekt 0;
BA_ "GenSigSendType" SG_ 1702 Wischer_vorne_Normal 3;
BA_ "GenSigSwitchedByIgnition" SG_ 1702 Wischer_vorne_Normal 0;
BA_ "GenSigSendType" SG_ 1702 Wischer_vorne_Parklage 3;
BA_ "GenSigStartValue" SG_ 1702 Wischer_vorne_Parklage 1;
BA_ "GenSigSwitchedByIgnition" SG_ 1702 Wischer_vorne_Parklage 0;
BA_ "GenSigSendType" SG_ 1702 Wischer_vorne_Schnell 3;
BA_ "GenSigSwitchedByIgnition" SG_ 1702 Wischer_vorne_Schnell 0;
BA_ "GenSigSendType" SG_ 1702 Wischer_WH_PopUp_Anf 3;
BA_ "GenSigSwitchedByIgnition" SG_ 1702 Wischer_WH_PopUp_Anf 0;
BA_ "GenSigSendType" SG_ 1702 Wischer_WH_Typ 0;
BA_ "GenSigSwitchedByIgnition" SG_ 1702 Wischer_WH_Typ 0;
BA_ "GenSigSendType" SG_ 1702 WWSs_01_alt 0;
BA_ "GenSigStartValue" SG_ 1702 WWSs_01_alt 1;
BA_ "GenSigFuncType" SG_ 1702 WWSs_01_alt 5;
BA_ "GenSigSwitchedByIgnition" SG_ 1702 WWSs_01_alt 0;
BA_ "GenSigSendType" SG_ 2589283611 WLC1_aktive_Spule 3;
BA_ "GenSigSwitchedByIgnition" SG_ 2589283611 WLC1_aktive_Spule 0;
BA_ "GenSigSendType" SG_ 2589283611 WLC1_Charger_Effizienz 3;
BA_ "GenSigSwitchedByIgnition" SG_ 2589283611 WLC1_Charger_Effizienz 0;
BA_ "GenSigSendType" SG_ 2589283611 WLC1_Charger_laedt 3;
BA_ "GenSigSwitchedByIgnition" SG_ 2589283611 WLC1_Charger_laedt 0;
BA_ "GenSigSendType" SG_ 2589283611 WLC1_Fehler 3;
BA_ "GenSigSwitchedByIgnition" SG_ 2589283611 WLC1_Fehler 0;
BA_ "GenSigSendType" SG_ 2589283611 WLC1_Fremdobjekt_erkannt 3;
BA_ "GenSigSwitchedByIgnition" SG_ 2589283611 WLC1_Fremdobjekt_erkannt 0;
BA_ "GenSigSendType" SG_ 2589283611 WLC1_Leistungsklasse_Receiver 0;
BA_ "GenSigSwitchedByIgnition" SG_ 2589283611 WLC1_Leistungsklasse_Receiver 0;
BA_ "GenSigSendType" SG_ 2589283611 WLC1_Objekt_erkannt 3;
BA_ "GenSigSwitchedByIgnition" SG_ 2589283611 WLC1_Objekt_erkannt 0;
BA_ "GenSigSendType" SG_ 2589283611 WLC1_Receiver_erkannt 3;
BA_ "GenSigSwitchedByIgnition" SG_ 2589283611 WLC1_Receiver_erkannt 0;
BA_ "GenSigSendType" SG_ 2589283611 WLC1_Receiver_voll_geladen 3;
BA_ "GenSigSwitchedByIgnition" SG_ 2589283611 WLC1_Receiver_voll_geladen 0;
BA_ "GenSigSendType" SG_ 2589283611 WLC1_Temp_Leistungsteil_Charger 0;
BA_ "GenSigSwitchedByIgnition" SG_ 2589283611 WLC1_Temp_Leistungsteil_Charger 0;
BA_ "GenSigSendType" SG_ 2589283611 WLC1_Temp_Oberfaeche_Charger 0;
BA_ "GenSigSwitchedByIgnition" SG_ 2589283611 WLC1_Temp_Oberfaeche_Charger 0;
BA_ "GenSigSendType" SG_ 2589283611 WLC1_Temp_Receiver 0;
BA_ "GenSigSwitchedByIgnition" SG_ 2589283611 WLC1_Temp_Receiver 0;
BA_ "GenSigSendType" SG_ 2589283611 WLC1_verwendeter_Ladestandard 0;
BA_ "GenSigSwitchedByIgnition" SG_ 2589283611 WLC1_verwendeter_Ladestandard 0;
BA_ "GenSigSendType" SG_ 2527679836 WLC1_ChargingEfficiency 3;
BA_ "GenSigSendType" SG_ 2527679836 WLC1_ChargingStatus 3;
BA_ "GenSigSendType" SG_ 2527679836 WLC1_UsedChargingStandard 3;
BA_ "GenSigSendType" SG_ 2527679837 WLC2_ChargingEfficiency 3;
BA_ "GenSigSendType" SG_ 2527679837 WLC2_ChargingStatus 3;
BA_ "GenSigSendType" SG_ 2527679837 WLC2_UsedChargingStandard 3;
BA_ "GenSigSendType" SG_ 2463978688 DMD_Soll_TempMode_L 3;
BA_ "GenSigSendType" SG_ 2463978688 DMD_Soll_TempMode_R 3;
BA_ "GenSigSendType" SG_ 2463978688 DML_EcoModus 3;
BA_ "GenSigSwitchedByIgnition" SG_ 2463978688 DML_EcoModus 0;
BA_ "GenSigSendType" SG_ 2463978688 DML_Fehlermeldung_Anf 3;
BA_ "GenSigSwitchedByIgnition" SG_ 2463978688 DML_Fehlermeldung_Anf 0;
BA_ "GenSigSendType" SG_ 2463978688 DML_Fernlichtlampe_Anf 3;
BA_ "GenSigSwitchedByIgnition" SG_ 2463978688 DML_Fernlichtlampe_Anf 0;
BA_ "GenSigSendType" SG_ 2463978688 zDML_ETH_Fehler 3;
BA_ "Fehlerwert" SG_ 2463978688 zDML_ETH_Fehler 1;
BA_ "GenSigSendType" SG_ 2463978688 zDML_ETH_Timeout 3;
BA_ "Fehlerwert" SG_ 2463978688 zDML_ETH_Timeout 1;
BA_ "GenSigSendType" SG_ 2463978688 zDML_Fokus 3;
BA_ "GenSigSendType" SG_ 2463978688 zDML_GMSL_L_Fehler 3;
BA_ "Fehlerwert" SG_ 2463978688 zDML_GMSL_L_Fehler 1;
BA_ "GenSigSendType" SG_ 2463978688 zDML_GMSL_R_Fehler 3;
BA_ "Fehlerwert" SG_ 2463978688 zDML_GMSL_R_Fehler 1;
BA_ "GenSigSendType" SG_ 2463978688 zDML_L_Abblendl_2_Def 3;
BA_ "GenSigSwitchedByIgnition" SG_ 2463978688 zDML_L_Abblendl_2_Def 0;
BA_ "Fehlerwert" SG_ 2463978688 zDML_L_Abblendl_2_Def 1;
BA_ "GenSigSendType" SG_ 2463978688 zDML_LED_L_Anf 3;
BA_ "GenSigSwitchedByIgnition" SG_ 2463978688 zDML_LED_L_Anf 0;
BA_ "GenSigSendType" SG_ 2463978688 zDML_LED_R_Anf 3;
BA_ "GenSigSwitchedByIgnition" SG_ 2463978688 zDML_LED_R_Anf 0;
BA_ "GenSigSendType" SG_ 2463978688 zDML_R_Abblendl_2_Def 3;
BA_ "GenSigSwitchedByIgnition" SG_ 2463978688 zDML_R_Abblendl_2_Def 0;
BA_ "Fehlerwert" SG_ 2463978688 zDML_R_Abblendl_2_Def 1;
BA_ "GenSigSendType" SG_ 2463978688 zDML_SG_Defekt 3;
BA_ "Fehlerwert" SG_ 2463978688 zDML_SG_Defekt 1;
BA_ "GenSigSendType" SG_ 2463978688 zDML_Speicher_Fehler 3;
BA_ "Fehlerwert" SG_ 2463978688 zDML_Speicher_Fehler 1;
BA_ "GenSigSendType" SG_ 2463978688 zDML_Status 3;
BA_ "GenSigSwitchedByIgnition" SG_ 2463978688 zDML_Status 0;
BA_ "Fehlerwert" SG_ 2463978688 zDML_Status 7;
BA_ "GenSigSendType" SG_ 2463978688 zDML_Versorgung_Fehler 3;
BA_ "Fehlerwert" SG_ 2463978688 zDML_Versorgung_Fehler 1;
BA_ "GenSigSendType" SG_ 2463978688 zDML_Video_Anf 3;
BA_ "GenSigSwitchedByIgnition" SG_ 2463978688 zDML_Video_Anf 0;
BA_ "GenSigSendType" SG_ 2463978688 zDML_Video_Fehler 3;
BA_ "Fehlerwert" SG_ 2463978688 zDML_Video_Fehler 1;
BA_ "GenSigSendType" SG_ 2463978854 DML_ConstructionZone_Available 3;
BA_ "GenSigSwitchedByIgnition" SG_ 2463978854 DML_ConstructionZone_Available 0;
BA_ "GenSigSendType" SG_ 2463978854 DML_CrossingAssist_Available 3;
BA_ "GenSigSwitchedByIgnition" SG_ 2463978854 DML_CrossingAssist_Available 0;
BA_ "GenSigSendType" SG_ 2463978854 DML_FuliValid 3;
BA_ "GenSigSwitchedByIgnition" SG_ 2463978854 DML_FuliValid 0;
BA_ "GenSigSendType" SG_ 2463978854 DML_GhostDriverWarn_Available 3;
BA_ "GenSigSwitchedByIgnition" SG_ 2463978854 DML_GhostDriverWarn_Available 0;
BA_ "GenSigSendType" SG_ 2463978854 DML_GlarefreeHB_Available 3;
BA_ "GenSigSwitchedByIgnition" SG_ 2463978854 DML_GlarefreeHB_Available 0;
BA_ "GenSigSendType" SG_ 2463978854 DML_HazardWarning_Available 3;
BA_ "GenSigSwitchedByIgnition" SG_ 2463978854 DML_HazardWarning_Available 0;
BA_ "GenSigSendType" SG_ 2463978854 DML_HMI_FCN_CROSSINGLI_AVAILABLE 3;
BA_ "GenSigSwitchedByIgnition" SG_ 2463978854 DML_HMI_FCN_CROSSINGLI_AVAILABLE 0;
BA_ "GenSigSendType" SG_ 2463978854 DML_HMI_FCN_HAZARDWARN_AVAILABLE 3;
BA_ "GenSigSwitchedByIgnition" SG_ 2463978854 DML_HMI_FCN_HAZARDWARN_AVAILABLE 0;
BA_ "GenSigSendType" SG_ 2463978854 DML_HMI_FCN_LANELIGHT_AVAILABLE 3;
BA_ "GenSigSwitchedByIgnition" SG_ 2463978854 DML_HMI_FCN_LANELIGHT_AVAILABLE 0;
BA_ "GenSigSendType" SG_ 2463978854 DML_HMI_FCN_LANLEAVELI_AVAILABLE 3;
BA_ "GenSigSwitchedByIgnition" SG_ 2463978854 DML_HMI_FCN_LANLEAVELI_AVAILABLE 0;
BA_ "GenSigSendType" SG_ 2463978854 DML_HMI_FCN_MALI_AVAILABLE 3;
BA_ "GenSigSwitchedByIgnition" SG_ 2463978854 DML_HMI_FCN_MALI_AVAILABLE 0;
BA_ "GenSigSendType" SG_ 2463978854 DML_HMI_FCN_ORLI_AVAILABLE 3;
BA_ "GenSigSwitchedByIgnition" SG_ 2463978854 DML_HMI_FCN_ORLI_AVAILABLE 0;
BA_ "GenSigSendType" SG_ 2463978854 DML_HMI_FCN_RESALLEYHI_AVAILABLE 3;
BA_ "GenSigSwitchedByIgnition" SG_ 2463978854 DML_HMI_FCN_RESALLEYHI_AVAILABLE 0;
BA_ "GenSigSendType" SG_ 2463978854 DML_HMI_FCN_ROADWORKLI_AVAILABLE 3;
BA_ "GenSigSwitchedByIgnition" SG_ 2463978854 DML_HMI_FCN_ROADWORKLI_AVAILABLE 0;
BA_ "GenSigSendType" SG_ 2463978854 DML_HMI_FCN_SAFETYZONE_AVAILABLE 3;
BA_ "GenSigSwitchedByIgnition" SG_ 2463978854 DML_HMI_FCN_SAFETYZONE_AVAILABLE 0;
BA_ "GenSigSendType" SG_ 2463978854 DML_HMI_FCN_TURNLIGHPR_AVAILABLE 3;
BA_ "GenSigSwitchedByIgnition" SG_ 2463978854 DML_HMI_FCN_TURNLIGHPR_AVAILABLE 0;
BA_ "GenSigSendType" SG_ 2463978854 DML_Indicator_Available 3;
BA_ "GenSigSwitchedByIgnition" SG_ 2463978854 DML_Indicator_Available 0;
BA_ "GenSigSendType" SG_ 2463978854 DML_IntelligentHB_Available 3;
BA_ "GenSigSwitchedByIgnition" SG_ 2463978854 DML_IntelligentHB_Available 0;
BA_ "GenSigSendType" SG_ 2463978854 DML_LaneDepartureWarn_Available 3;
BA_ "GenSigSwitchedByIgnition" SG_ 2463978854 DML_LaneDepartureWarn_Available 0;
BA_ "GenSigSendType" SG_ 2463978854 DML_LaneLight_Available 3;
BA_ "GenSigSwitchedByIgnition" SG_ 2463978854 DML_LaneLight_Available 0;
BA_ "GenSigSendType" SG_ 2463978854 DML_MarkingLight_Available 3;
BA_ "GenSigSwitchedByIgnition" SG_ 2463978854 DML_MarkingLight_Available 0;
BA_ "GenSigSendType" SG_ 2463978854 DML_OrientationLight_Available 3;
BA_ "GenSigSwitchedByIgnition" SG_ 2463978854 DML_OrientationLight_Available 0;
BA_ "GenSigSendType" SG_ 2463978854 DML_RescueLaneNotice_Available 3;
BA_ "GenSigSwitchedByIgnition" SG_ 2463978854 DML_RescueLaneNotice_Available 0;
BA_ "GenSigSendType" SG_ 2463978854 DML_SafetyZone_Available 3;
BA_ "GenSigSwitchedByIgnition" SG_ 2463978854 DML_SafetyZone_Available 0;
BA_ "GenSigSendType" SG_ 2463978854 DML_SaftyDistance_Available 3;
BA_ "GenSigSwitchedByIgnition" SG_ 2463978854 DML_SaftyDistance_Available 0;
BA_ "GenSigSendType" SG_ 2463978854 DML_SideAssist_Available 3;
BA_ "GenSigSwitchedByIgnition" SG_ 2463978854 DML_SideAssist_Available 0;
BA_ "GenSigSendType" SG_ 1140 DI_Screendesign 3;
BA_ "GenSigStartValue" SG_ 1140 DI_Screendesign 6;
BA_ "GenSigSwitchedByIgnition" SG_ 1140 DI_Screendesign 0;
BA_ "Fehlerwert" SG_ 1140 DI_Screendesign 7;
BA_ "GenSigSendType" SG_ 1140 MMI_State 3;
BA_ "GenSigSwitchedByIgnition" SG_ 1140 MMI_State 0;
BA_ "GenSigSendType" SG_ 1140 SI_ICAN 3;
BA_ "GenSigStartValue" SG_ 1140 SI_ICAN 1;
BA_ "GenSigSwitchedByIgnition" SG_ 1140 SI_ICAN 0;
BA_ "GenSigSendType" SG_ 1140 WLC1_Systemzustand 3;
BA_ "GenSigSwitchedByIgnition" SG_ 1140 WLC1_Systemzustand 0;
BA_ "GenSigSendType" SG_ 1140 WLC2_Systemzustand 3;
BA_ "GenSigSwitchedByIgnition" SG_ 1140 WLC2_Systemzustand 0;
BA_ "GenSigSendType" SG_ 1140 ZR_DimOffs_DU_1 3;
BA_ "GenSigStartValue" SG_ 1140 ZR_DimOffs_DU_1 14;
BA_ "GenSigSwitchedByIgnition" SG_ 1140 ZR_DimOffs_DU_1 0;
BA_ "GenSigSendType" SG_ 1140 ZR_DimOffs_DU_2 3;
BA_ "GenSigStartValue" SG_ 1140 ZR_DimOffs_DU_2 14;
BA_ "GenSigSwitchedByIgnition" SG_ 1140 ZR_DimOffs_DU_2 0;
BA_ "GenSigSendType" SG_ 1140 ZR_DimOffs_DU_3 3;
BA_ "GenSigStartValue" SG_ 1140 ZR_DimOffs_DU_3 14;
BA_ "GenSigSwitchedByIgnition" SG_ 1140 ZR_DimOffs_DU_3 0;
BA_ "GenSigSendType" SG_ 1140 ZR_DimOffs_DU_4 3;
BA_ "GenSigSendType" SG_ 1140 ZR_Lenkerposition 0;
BA_ "GenSigSwitchedByIgnition" SG_ 1140 ZR_Lenkerposition 0;
BA_ "GenSigSendType" SG_ 1140 ZR_State_DU_1 3;
BA_ "GenSigSwitchedByIgnition" SG_ 1140 ZR_State_DU_1 0;
BA_ "GenSigSendType" SG_ 1140 ZR_State_DU_2 3;
BA_ "GenSigSwitchedByIgnition" SG_ 1140 ZR_State_DU_2 0;
BA_ "GenSigSendType" SG_ 1140 ZR_State_DU_3 3;
BA_ "GenSigSwitchedByIgnition" SG_ 1140 ZR_State_DU_3 0;
BA_ "GenSigSendType" SG_ 1140 ZR_State_DU_4 3;
BA_ "GenSigSendType" SG_ 1140 ZR_WecktGesp 3;
BA_ "GenSigSwitchedByIgnition" SG_ 1140 ZR_WecktGesp 0;
BA_ "GenSigSendType" SG_ 2589284130 ZR_ORU_Status 3;
BA_ "GenSigSwitchedByIgnition" SG_ 2589284130 ZR_ORU_Status 0;
BA_ "GenSigActiveRepetitions" SG_ 389 Krypt_Schluesselschalter_auf 5;
BA_ "GenSigSendType" SG_ 389 Krypt_Schluesselschalter_auf 9;
BA_ "GenSigSwitchedByIgnition" SG_ 389 Krypt_Schluesselschalter_auf 0;
BA_ "GenSigActiveRepetitions" SG_ 389 Krypt_Schluesselschalter_zu 5;
BA_ "GenSigSendType" SG_ 389 Krypt_Schluesselschalter_zu 9;
BA_ "GenSigSwitchedByIgnition" SG_ 389 Krypt_Schluesselschalter_zu 0;
BA_ "GenSigActiveRepetitions" SG_ 389 Krypt_Signatur 5;
BA_ "GenSigSendType" SG_ 389 Krypt_Signatur 4;
BA_ "GenSigSwitchedByIgnition" SG_ 389 Krypt_Signatur 0;
BA_ "GenSigActiveRepetitions" SG_ 389 ZFH_BFS_AutoHoch 5;
BA_ "GenSigSendType" SG_ 389 ZFH_BFS_AutoHoch 9;
BA_ "GenSigSwitchedByIgnition" SG_ 389 ZFH_BFS_AutoHoch 0;
BA_ "GenSigActiveRepetitions" SG_ 389 ZFH_BFS_AutoTief 5;
BA_ "GenSigSendType" SG_ 389 ZFH_BFS_AutoTief 9;
BA_ "GenSigSwitchedByIgnition" SG_ 389 ZFH_BFS_AutoTief 0;
BA_ "GenSigActiveRepetitions" SG_ 389 ZFH_BFS_ManHoch 5;
BA_ "GenSigSendType" SG_ 389 ZFH_BFS_ManHoch 9;
BA_ "GenSigSwitchedByIgnition" SG_ 389 ZFH_BFS_ManHoch 0;
BA_ "GenSigActiveRepetitions" SG_ 389 ZFH_BFS_ManTief 5;
BA_ "GenSigSendType" SG_ 389 ZFH_BFS_ManTief 9;
BA_ "GenSigSwitchedByIgnition" SG_ 389 ZFH_BFS_ManTief 0;
BA_ "GenSigActiveRepetitions" SG_ 389 ZFH_FS_AutoHoch 5;
BA_ "GenSigSendType" SG_ 389 ZFH_FS_AutoHoch 9;
BA_ "GenSigSwitchedByIgnition" SG_ 389 ZFH_FS_AutoHoch 0;
BA_ "GenSigActiveRepetitions" SG_ 389 ZFH_FS_AutoTief 5;
BA_ "GenSigSendType" SG_ 389 ZFH_FS_AutoTief 9;
BA_ "GenSigSwitchedByIgnition" SG_ 389 ZFH_FS_AutoTief 0;
BA_ "GenSigActiveRepetitions" SG_ 389 ZFH_FS_ManHoch 5;
BA_ "GenSigSendType" SG_ 389 ZFH_FS_ManHoch 9;
BA_ "GenSigSwitchedByIgnition" SG_ 389 ZFH_FS_ManHoch 0;
BA_ "GenSigActiveRepetitions" SG_ 389 ZFH_FS_ManTief 5;
BA_ "GenSigSendType" SG_ 389 ZFH_FS_ManTief 9;
BA_ "GenSigSwitchedByIgnition" SG_ 389 ZFH_FS_ManTief 0;
BA_ "GenSigActiveRepetitions" SG_ 389 ZFH_HBFS_AutoHoch 5;
BA_ "GenSigSendType" SG_ 389 ZFH_HBFS_AutoHoch 9;
BA_ "GenSigSwitchedByIgnition" SG_ 389 ZFH_HBFS_AutoHoch 0;
BA_ "GenSigActiveRepetitions" SG_ 389 ZFH_HBFS_AutoTief 5;
BA_ "GenSigSendType" SG_ 389 ZFH_HBFS_AutoTief 9;
BA_ "GenSigSwitchedByIgnition" SG_ 389 ZFH_HBFS_AutoTief 0;
BA_ "GenSigActiveRepetitions" SG_ 389 ZFH_HBFS_ManHoch 5;
BA_ "GenSigSendType" SG_ 389 ZFH_HBFS_ManHoch 9;
BA_ "GenSigSwitchedByIgnition" SG_ 389 ZFH_HBFS_ManHoch 0;
BA_ "GenSigActiveRepetitions" SG_ 389 ZFH_HBFS_ManTief 5;
BA_ "GenSigSendType" SG_ 389 ZFH_HBFS_ManTief 9;
BA_ "GenSigSwitchedByIgnition" SG_ 389 ZFH_HBFS_ManTief 0;
BA_ "GenSigActiveRepetitions" SG_ 389 ZFH_HFS_AutoHoch 5;
BA_ "GenSigSendType" SG_ 389 ZFH_HFS_AutoHoch 9;
BA_ "GenSigSwitchedByIgnition" SG_ 389 ZFH_HFS_AutoHoch 0;
BA_ "GenSigActiveRepetitions" SG_ 389 ZFH_HFS_AutoTief 5;
BA_ "GenSigSendType" SG_ 389 ZFH_HFS_AutoTief 9;
BA_ "GenSigSwitchedByIgnition" SG_ 389 ZFH_HFS_AutoTief 0;
BA_ "GenSigActiveRepetitions" SG_ 389 ZFH_HFS_ManHoch 5;
BA_ "GenSigSendType" SG_ 389 ZFH_HFS_ManHoch 9;
BA_ "GenSigSwitchedByIgnition" SG_ 389 ZFH_HFS_ManHoch 0;
BA_ "GenSigActiveRepetitions" SG_ 389 ZFH_HFS_ManTief 5;
BA_ "GenSigSendType" SG_ 389 ZFH_HFS_ManTief 9;
BA_ "GenSigSwitchedByIgnition" SG_ 389 ZFH_HFS_ManTief 0;
BA_ "GenSigActiveRepetitions" SG_ 389 ZFH_zentral_auf 5;
BA_ "GenSigSendType" SG_ 389 ZFH_zentral_auf 9;
BA_ "GenSigSwitchedByIgnition" SG_ 389 ZFH_zentral_auf 0;
BA_ "GenSigActiveRepetitions" SG_ 389 ZFH_zentral_zu 5;
BA_ "GenSigSendType" SG_ 389 ZFH_zentral_zu 9;
BA_ "GenSigSwitchedByIgnition" SG_ 389 ZFH_zentral_zu 0;
BA_ "GenSigSendType" SG_ 388 BCM_BF_Spg_Absenkung 0;
BA_ "GenSigSwitchedByIgnition" SG_ 388 BCM_BF_Spg_Absenkung 0;
BA_ "GenSigSendType" SG_ 388 BCM_Spg_Synchron 0;
BA_ "GenSigSwitchedByIgnition" SG_ 388 BCM_Spg_Synchron 0;
BA_ "GenSigSendType" SG_ 388 FH_BT_hoch 6;
BA_ "GenSigSwitchedByIgnition" SG_ 388 FH_BT_hoch 0;
BA_ "GenSigSendType" SG_ 388 FH_BT_tief 6;
BA_ "GenSigSwitchedByIgnition" SG_ 388 FH_BT_tief 0;
BA_ "GenSigSendType" SG_ 388 FH_FT_hoch 6;
BA_ "GenSigSwitchedByIgnition" SG_ 388 FH_FT_hoch 0;
BA_ "GenSigSendType" SG_ 388 FH_FT_tief 6;
BA_ "GenSigSwitchedByIgnition" SG_ 388 FH_FT_tief 0;
BA_ "GenSigSendType" SG_ 388 FH_HBFS_hoch 6;
BA_ "GenSigSwitchedByIgnition" SG_ 388 FH_HBFS_hoch 0;
BA_ "GenSigSendType" SG_ 388 FH_HBFS_tief 6;
BA_ "GenSigSwitchedByIgnition" SG_ 388 FH_HBFS_tief 0;
BA_ "GenSigSendType" SG_ 388 FH_HFS_hoch 6;
BA_ "GenSigSwitchedByIgnition" SG_ 388 FH_HFS_hoch 0;
BA_ "GenSigSendType" SG_ 388 FH_HFS_tief 6;
BA_ "GenSigSwitchedByIgnition" SG_ 388 FH_HFS_tief 0;
BA_ "GenSigSendType" SG_ 388 VIP_Freigabe 0;
BA_ "GenSigSwitchedByIgnition" SG_ 388 VIP_Freigabe 0;
BA_ "GenSigSendType" SG_ 388 VIP_Sensor_betaetigt 6;
BA_ "GenSigSwitchedByIgnition" SG_ 388 VIP_Sensor_betaetigt 0;
BA_ "GenSigSendType" SG_ 388 ZV_01_BZ 0;
BA_ "GenSigFuncType" SG_ 388 ZV_01_BZ 1;
BA_ "GenSigSendType" SG_ 388 ZV_01_CRC 0;
BA_ "GenSigFuncType" SG_ 388 ZV_01_CRC 2;
BA_ "GenSigSendType" SG_ 388 ZV_auf_BT 6;
BA_ "GenSigSwitchedByIgnition" SG_ 388 ZV_auf_BT 0;
BA_ "GenSigSendType" SG_ 388 ZV_auf_FT 6;
BA_ "GenSigSwitchedByIgnition" SG_ 388 ZV_auf_FT 0;
BA_ "GenSigSendType" SG_ 388 ZV_auf_Funk 6;
BA_ "GenSigSwitchedByIgnition" SG_ 388 ZV_auf_Funk 0;
BA_ "GenSigSendType" SG_ 388 ZV_auf_Kessy 6;
BA_ "GenSigSwitchedByIgnition" SG_ 388 ZV_auf_Kessy 0;
BA_ "GenSigSendType" SG_ 388 ZV_auto_Ansteuerung 6;
BA_ "GenSigSwitchedByIgnition" SG_ 388 ZV_auto_Ansteuerung 0;
BA_ "GenSigSendType" SG_ 388 ZV_BT_entriegeln 6;
BA_ "GenSigSwitchedByIgnition" SG_ 388 ZV_BT_entriegeln 0;
BA_ "GenSigSendType" SG_ 388 ZV_BT_verriegeln 6;
BA_ "GenSigSwitchedByIgnition" SG_ 388 ZV_BT_verriegeln 0;
BA_ "GenSigSendType" SG_ 388 ZV_entriegeln_Anf 6;
BA_ "GenSigSwitchedByIgnition" SG_ 388 ZV_entriegeln_Anf 0;
BA_ "GenSigSendType" SG_ 388 ZV_FT_entriegeln 6;
BA_ "GenSigSwitchedByIgnition" SG_ 388 ZV_FT_entriegeln 0;
BA_ "GenSigSendType" SG_ 388 ZV_FT_verriegeln 6;
BA_ "GenSigSwitchedByIgnition" SG_ 388 ZV_FT_verriegeln 0;
BA_ "GenSigSendType" SG_ 388 ZV_HBFS_entriegeln 6;
BA_ "GenSigSwitchedByIgnition" SG_ 388 ZV_HBFS_entriegeln 0;
BA_ "GenSigSendType" SG_ 388 ZV_HBFS_verriegeln 6;
BA_ "GenSigSwitchedByIgnition" SG_ 388 ZV_HBFS_verriegeln 0;
BA_ "GenSigSendType" SG_ 388 ZV_HFS_entriegeln 6;
BA_ "GenSigSwitchedByIgnition" SG_ 388 ZV_HFS_entriegeln 0;
BA_ "GenSigSendType" SG_ 388 ZV_HFS_verriegeln 6;
BA_ "GenSigSwitchedByIgnition" SG_ 388 ZV_HFS_verriegeln 0;
BA_ "GenSigSendType" SG_ 388 ZV_HSK_entriegeln 6;
BA_ "GenSigSwitchedByIgnition" SG_ 388 ZV_HSK_entriegeln 0;
BA_ "GenSigSendType" SG_ 388 ZV_HSK_verriegeln 6;
BA_ "GenSigSwitchedByIgnition" SG_ 388 ZV_HSK_verriegeln 0;
BA_ "GenSigSendType" SG_ 388 ZV_LED_Steuerung 6;
BA_ "GenSigSwitchedByIgnition" SG_ 388 ZV_LED_Steuerung 0;
BA_ "GenSigSendType" SG_ 388 ZV_LED_Uebernahme 6;
BA_ "GenSigSwitchedByIgnition" SG_ 388 ZV_LED_Uebernahme 0;
BA_ "GenSigSendType" SG_ 388 ZV_Signatur 6;
BA_ "GenSigSwitchedByIgnition" SG_ 388 ZV_Signatur 0;
BA_ "GenSigSendType" SG_ 388 ZV_Softtouch_betaetigt 6;
BA_ "GenSigSwitchedByIgnition" SG_ 388 ZV_Softtouch_betaetigt 0;
BA_ "GenSigSendType" SG_ 388 ZV_Spg_Anklappen 6;
BA_ "GenSigSwitchedByIgnition" SG_ 388 ZV_Spg_Anklappen 0;
BA_ "GenSigSendType" SG_ 388 ZV_Verdeck_auf 6;
BA_ "GenSigSwitchedByIgnition" SG_ 388 ZV_Verdeck_auf 0;
BA_ "GenSigSendType" SG_ 388 ZV_Verdeck_zu 6;
BA_ "GenSigSwitchedByIgnition" SG_ 388 ZV_Verdeck_zu 0;
BA_ "GenSigSendType" SG_ 388 ZV_zentral_entsafen 6;
BA_ "GenSigSwitchedByIgnition" SG_ 388 ZV_zentral_entsafen 0;
BA_ "GenSigSendType" SG_ 388 ZV_zentral_safen 6;
BA_ "GenSigSwitchedByIgnition" SG_ 388 ZV_zentral_safen 0;
BA_ "GenSigSendType" SG_ 388 ZV_zu_BT 6;
BA_ "GenSigSwitchedByIgnition" SG_ 388 ZV_zu_BT 0;
BA_ "GenSigSendType" SG_ 388 ZV_zu_FT 6;
BA_ "GenSigSwitchedByIgnition" SG_ 388 ZV_zu_FT 0;
BA_ "GenSigSendType" SG_ 388 ZV_zu_Funk 6;
BA_ "GenSigSwitchedByIgnition" SG_ 388 ZV_zu_Funk 0;
BA_ "GenSigSendType" SG_ 388 ZV_zu_Kessy 6;
BA_ "GenSigSwitchedByIgnition" SG_ 388 ZV_zu_Kessy 0;
BA_ "GenSigSendType" SG_ 388 ZV_zu_Zeitl_Nachverr 6;
BA_ "GenSigSwitchedByIgnition" SG_ 388 ZV_zu_Zeitl_Nachverr 0;
BA_ "GenSigSendType" SG_ 1411 BCM_FH_Freigabe 3;
BA_ "GenSigSwitchedByIgnition" SG_ 1411 BCM_FH_Freigabe 0;
BA_ "GenSigSendType" SG_ 1411 BCM_HSK_Freigabe 3;
BA_ "GenSigSwitchedByIgnition" SG_ 1411 BCM_HSK_Freigabe 0;
BA_ "GenSigSendType" SG_ 1411 BCM_Komfortfkt_Freigabe 3;
BA_ "GenSigSwitchedByIgnition" SG_ 1411 BCM_Komfortfkt_Freigabe 0;
BA_ "GenSigSendType" SG_ 1411 BCM_Tankklappensteller_Fehler 0;
BA_ "GenSigSwitchedByIgnition" SG_ 1411 BCM_Tankklappensteller_Fehler 0;
BA_ "Fehlerwert" SG_ 1411 BCM_Tankklappensteller_Fehler 1;
BA_ "GenSigSendType" SG_ 1411 BCM_Verdeck_Freigabe 3;
BA_ "GenSigSwitchedByIgnition" SG_ 1411 BCM_Verdeck_Freigabe 0;
BA_ "GenSigSendType" SG_ 1411 DWA_aktiv 3;
BA_ "GenSigSwitchedByIgnition" SG_ 1411 DWA_aktiv 0;
BA_ "GenSigSendType" SG_ 1411 FBS_IDG_in_Reichweite 6;
BA_ "GenSigSwitchedByIgnition" SG_ 1411 FBS_IDG_in_Reichweite 0;
BA_ "GenSigSendType" SG_ 1411 FBS_Warn_Schluessel_Batt 3;
BA_ "GenSigSwitchedByIgnition" SG_ 1411 FBS_Warn_Schluessel_Batt 0;
BA_ "GenSigSendType" SG_ 1411 FFB_Auf_Taste 6;
BA_ "GenSigSwitchedByIgnition" SG_ 1411 FFB_Auf_Taste 0;
BA_ "GenSigSendType" SG_ 1411 FFB_CarFinder 6;
BA_ "GenSigSwitchedByIgnition" SG_ 1411 FFB_CarFinder 0;
BA_ "GenSigSendType" SG_ 1411 FFB_HDF_Taste 6;
BA_ "GenSigSwitchedByIgnition" SG_ 1411 FFB_HDF_Taste 0;
BA_ "GenSigSendType" SG_ 1411 FFB_Komfortoeffnen 6;
BA_ "GenSigSwitchedByIgnition" SG_ 1411 FFB_Komfortoeffnen 0;
BA_ "GenSigSendType" SG_ 1411 FFB_Komfortschliessen 6;
BA_ "GenSigSwitchedByIgnition" SG_ 1411 FFB_Komfortschliessen 0;
BA_ "GenSigSendType" SG_ 1411 FFB_Panik_Taste 6;
BA_ "GenSigSwitchedByIgnition" SG_ 1411 FFB_Panik_Taste 0;
BA_ "GenSigSendType" SG_ 1411 FFB_Zu_Taste 6;
BA_ "GenSigSwitchedByIgnition" SG_ 1411 FFB_Zu_Taste 0;
BA_ "GenSigSendType" SG_ 1411 HBFS_gesafet 3;
BA_ "GenSigSwitchedByIgnition" SG_ 1411 HBFS_gesafet 0;
BA_ "GenSigSendType" SG_ 1411 HBFS_verriegelt 3;
BA_ "GenSigSwitchedByIgnition" SG_ 1411 HBFS_verriegelt 0;
BA_ "GenSigSendType" SG_ 1411 HD_Hauptraste 3;
BA_ "GenSigSwitchedByIgnition" SG_ 1411 HD_Hauptraste 0;
BA_ "GenSigSendType" SG_ 1411 HD_Vorraste 3;
BA_ "GenSigSwitchedByIgnition" SG_ 1411 HD_Vorraste 0;
BA_ "GenSigSendType" SG_ 1411 HFS_gesafet 3;
BA_ "GenSigSwitchedByIgnition" SG_ 1411 HFS_gesafet 0;
BA_ "GenSigSendType" SG_ 1411 HFS_verriegelt 3;
BA_ "GenSigSwitchedByIgnition" SG_ 1411 HFS_verriegelt 0;
BA_ "GenSigSendType" SG_ 1411 IRUE_aktiv 3;
BA_ "GenSigSwitchedByIgnition" SG_ 1411 IRUE_aktiv 0;
BA_ "GenSigSendType" SG_ 1411 IRUE_Taster_Fkts_LED 3;
BA_ "GenSigSwitchedByIgnition" SG_ 1411 IRUE_Taster_Fkts_LED 0;
BA_ "GenSigSendType" SG_ 1411 VIP_Sensor_STSG_HBFS_betaetigt 6;
BA_ "GenSigSwitchedByIgnition" SG_ 1411 VIP_Sensor_STSG_HBFS_betaetigt 0;
BA_ "GenSigSendType" SG_ 1411 VIP_Sensor_STSG_HFS_betaetigt 6;
BA_ "GenSigSwitchedByIgnition" SG_ 1411 VIP_Sensor_STSG_HFS_betaetigt 0;
BA_ "GenSigSendType" SG_ 1411 ZV_Anf_Challenge_Auth 6;
BA_ "GenSigSwitchedByIgnition" SG_ 1411 ZV_Anf_Challenge_Auth 0;
BA_ "GenSigSendType" SG_ 1411 ZV_BT_offen 3;
BA_ "GenSigSwitchedByIgnition" SG_ 1411 ZV_BT_offen 0;
BA_ "GenSigSendType" SG_ 1411 ZV_Einzeltuerentriegelung 3;
BA_ "GenSigSwitchedByIgnition" SG_ 1411 ZV_Einzeltuerentriegelung 0;
BA_ "GenSigSendType" SG_ 1411 ZV_eRWK_Umfeld_Pruefung 6;
BA_ "GenSigSwitchedByIgnition" SG_ 1411 ZV_eRWK_Umfeld_Pruefung 0;
BA_ "GenSigSendType" SG_ 1411 ZV_FT_offen 3;
BA_ "GenSigSwitchedByIgnition" SG_ 1411 ZV_FT_offen 0;
BA_ "GenSigSendType" SG_ 1411 ZV_gesafet_extern_ist 3;
BA_ "GenSigSwitchedByIgnition" SG_ 1411 ZV_gesafet_extern_ist 0;
BA_ "GenSigSendType" SG_ 1411 ZV_gesafet_extern_soll 3;
BA_ "GenSigSwitchedByIgnition" SG_ 1411 ZV_gesafet_extern_soll 0;
BA_ "GenSigSendType" SG_ 1411 ZV_HBFS_offen 3;
BA_ "GenSigSwitchedByIgnition" SG_ 1411 ZV_HBFS_offen 0;
BA_ "GenSigSendType" SG_ 1411 ZV_HD_offen 3;
BA_ "GenSigSwitchedByIgnition" SG_ 1411 ZV_HD_offen 0;
BA_ "GenSigSendType" SG_ 1411 ZV_Heckeinzelentriegelung 3;
BA_ "GenSigSwitchedByIgnition" SG_ 1411 ZV_Heckeinzelentriegelung 0;
BA_ "GenSigSendType" SG_ 1411 ZV_HFS_offen 3;
BA_ "GenSigSwitchedByIgnition" SG_ 1411 ZV_HFS_offen 0;
BA_ "GenSigSendType" SG_ 1411 ZV_HS_offen 3;
BA_ "GenSigSwitchedByIgnition" SG_ 1411 ZV_HS_offen 0;
BA_ "GenSigSendType" SG_ 1411 ZV_ist_Zustand_verfuegbar 3;
BA_ "GenSigSwitchedByIgnition" SG_ 1411 ZV_ist_Zustand_verfuegbar 0;
BA_ "GenSigSendType" SG_ 1411 ZV_Oeffnungsmodus 3;
BA_ "GenSigSwitchedByIgnition" SG_ 1411 ZV_Oeffnungsmodus 0;
BA_ "GenSigSendType" SG_ 1411 ZV_Rollo_auf 3;
BA_ "GenSigSwitchedByIgnition" SG_ 1411 ZV_Rollo_auf 0;
BA_ "GenSigSendType" SG_ 1411 ZV_Rollo_zu 3;
BA_ "GenSigSwitchedByIgnition" SG_ 1411 ZV_Rollo_zu 0;
BA_ "GenSigSendType" SG_ 1411 ZV_SAD_auf 3;
BA_ "GenSigSwitchedByIgnition" SG_ 1411 ZV_SAD_auf 0;
BA_ "GenSigSendType" SG_ 1411 ZV_SAD_zu 3;
BA_ "GenSigSwitchedByIgnition" SG_ 1411 ZV_SAD_zu 0;
BA_ "GenSigSendType" SG_ 1411 ZV_SafeFunktion_aktiv 3;
BA_ "GenSigSwitchedByIgnition" SG_ 1411 ZV_SafeFunktion_aktiv 0;
BA_ "GenSigSendType" SG_ 1411 ZV_Schluessel_Zugang 3;
BA_ "GenSigSwitchedByIgnition" SG_ 1411 ZV_Schluessel_Zugang 0;
BA_ "GenSigSendType" SG_ 1411 ZV_STSG_Crashzustand 4;
BA_ "GenSigSwitchedByIgnition" SG_ 1411 ZV_STSG_Crashzustand 0;
BA_ "GenSigSendType" SG_ 1411 ZV_STSG_eKiSi_defekt 4;
BA_ "GenSigSwitchedByIgnition" SG_ 1411 ZV_STSG_eKiSi_defekt 0;
BA_ "GenSigSendType" SG_ 1411 ZV_STSG_HBFS_Anf 3;
BA_ "GenSigSwitchedByIgnition" SG_ 1411 ZV_STSG_HBFS_Anf 0;
BA_ "GenSigSendType" SG_ 1411 ZV_STSG_HFS_Anf 3;
BA_ "GenSigSwitchedByIgnition" SG_ 1411 ZV_STSG_HFS_Anf 0;
BA_ "GenSigSendType" SG_ 1411 ZV_Tankklappe_offen 0;
BA_ "GenSigSwitchedByIgnition" SG_ 1411 ZV_Tankklappe_offen 0;
BA_ "GenSigSendType" SG_ 1411 ZV_verriegeln_Anf 6;
BA_ "GenSigSwitchedByIgnition" SG_ 1411 ZV_verriegeln_Anf 0;
BA_ "GenSigSendType" SG_ 1411 ZV_verriegelt_extern_ist 3;
BA_ "GenSigSwitchedByIgnition" SG_ 1411 ZV_verriegelt_extern_ist 0;
BA_ "GenSigSendType" SG_ 1411 ZV_verriegelt_extern_soll 3;
BA_ "GenSigSwitchedByIgnition" SG_ 1411 ZV_verriegelt_extern_soll 0;
BA_ "GenSigSendType" SG_ 1411 ZV_verriegelt_intern_ist 3;
BA_ "GenSigSwitchedByIgnition" SG_ 1411 ZV_verriegelt_intern_ist 0;
BA_ "GenSigSendType" SG_ 1411 ZV_verriegelt_intern_soll 3;
BA_ "GenSigSwitchedByIgnition" SG_ 1411 ZV_verriegelt_intern_soll 0;
BA_ "GenSigSendType" SG_ 1411 ZV_verriegelt_soll 3;
BA_ "GenSigSwitchedByIgnition" SG_ 1411 ZV_verriegelt_soll 0;
BA_ "GenSigSendType" SG_ 708 UHF_FFB_Funkschluesseltyp 4;
BA_ "GenSigSwitchedByIgnition" SG_ 708 UHF_FFB_Funkschluesseltyp 0;
BA_ "GenSigSendType" SG_ 708 UHF_FFB_SKC_anlernen 4;
BA_ "GenSigSwitchedByIgnition" SG_ 708 UHF_FFB_SKC_anlernen 0;
BA_ "GenSigSendType" SG_ 708 ZV_04_BZ 0;
BA_ "GenSigFuncType" SG_ 708 ZV_04_BZ 1;
BA_ "GenSigSwitchedByIgnition" SG_ 708 ZV_04_BZ 0;
BA_ "GenSigSendType" SG_ 708 ZV_04_CRC 0;
BA_ "GenSigFuncType" SG_ 708 ZV_04_CRC 2;
BA_ "GenSigSendType" SG_ 708 ZV_DWA_Einfachhorn_Anf 4;
BA_ "GenSigSwitchedByIgnition" SG_ 708 ZV_DWA_Einfachhorn_Anf 0;
BA_ "GenSigSendType" SG_ 708 ZV_DWA_Einfachhorn_Takt 4;
BA_ "GenSigSwitchedByIgnition" SG_ 708 ZV_DWA_Einfachhorn_Takt 0;
BA_ "GenSigSendType" SG_ 708 ZV_Einfachhorn_Anf 4;
BA_ "GenSigSwitchedByIgnition" SG_ 708 ZV_Einfachhorn_Anf 0;
BA_ "GenSigSendType" SG_ 708 ZV_Einfachhorn_Takt 4;
BA_ "GenSigSwitchedByIgnition" SG_ 708 ZV_Einfachhorn_Takt 0;
BA_ "GenSigSendType" SG_ 708 ZV_HBFS_Status_KiSi 4;
BA_ "GenSigSwitchedByIgnition" SG_ 708 ZV_HBFS_Status_KiSi 0;
BA_ "GenSigSendType" SG_ 708 ZV_HBFS_TAG_betaetigt 9;
BA_ "GenSigSwitchedByIgnition" SG_ 708 ZV_HBFS_TAG_betaetigt 0;
BA_ "GenSigSendType" SG_ 708 ZV_HBFS_TIG_oeffnen_betaetigt 9;
BA_ "GenSigSwitchedByIgnition" SG_ 708 ZV_HBFS_TIG_oeffnen_betaetigt 0;
BA_ "GenSigSendType" SG_ 708 ZV_HBFS_TIG_schliessen_betaetigt 9;
BA_ "GenSigSwitchedByIgnition" SG_ 708 ZV_HBFS_TIG_schliessen_betaetigt 0;
BA_ "GenSigSendType" SG_ 708 ZV_HFS_Status_KiSi 4;
BA_ "GenSigSwitchedByIgnition" SG_ 708 ZV_HFS_Status_KiSi 0;
BA_ "GenSigSendType" SG_ 708 ZV_HFS_TAG_betaetigt 9;
BA_ "GenSigSwitchedByIgnition" SG_ 708 ZV_HFS_TAG_betaetigt 0;
BA_ "GenSigSendType" SG_ 708 ZV_HFS_TIG_oeffnen_betaetigt 9;
BA_ "GenSigSwitchedByIgnition" SG_ 708 ZV_HFS_TIG_oeffnen_betaetigt 0;
BA_ "GenSigSendType" SG_ 708 ZV_HFS_TIG_schliessen_betaetigt 9;
BA_ "GenSigSwitchedByIgnition" SG_ 708 ZV_HFS_TIG_schliessen_betaetigt 0;
BA_ "GenSigSendType" SG_ 708 ZV_Hupe_Anf 4;
BA_ "GenSigSendType" SG_ 708 ZV_Hupe_Takt 4;
BA_ "GenSigSendType" SG_ 708 ZV_HW_Motor_Lock_HK 6;
BA_ "GenSigSwitchedByIgnition" SG_ 708 ZV_HW_Motor_Lock_HK 0;
BA_ "GenSigSendType" SG_ 708 ZV_HW_Motor_Safe_Hinten 6;
BA_ "GenSigSwitchedByIgnition" SG_ 708 ZV_HW_Motor_Safe_Hinten 0;
BA_ "GenSigSendType" SG_ 708 ZV_HW_TKL_mot_entr 3;
BA_ "GenSigSendType" SG_ 708 ZV_HW_TKL_mot_verr 3;
BA_ "GenSigSendType" SG_ 708 ZV_Laderaumabd_elektr_aktiviert 3;
BA_ "GenSigSwitchedByIgnition" SG_ 708 ZV_Laderaumabd_elektr_aktiviert 0;
BA_ "GenSigSendType" SG_ 708 ZV_Status_Cargolock 4;
BA_ "GenSigSendType" SG_ 708 ZV_Status_KiSi_CargoLock 4;
BA_ "GenSigSwitchedByIgnition" SG_ 708 ZV_Status_KiSi_CargoLock 0;
BA_ "Fehlerwert" SG_ 708 ZV_Status_KiSi_CargoLock 7;
BA_REL_ "GenSigTimeoutTime" BU_SG_REL_ BCM SG_ 313 VMM_02_CRC 1000;
BA_REL_ "GenSigTimeoutTime" BU_SG_REL_ BCM SG_ 313 VMM_02_BZ 1000;
BA_REL_ "GenSigTimeoutTime" BU_SG_REL_ BCM SG_ 313 VZM_Fahrer_bremst 1000;
BA_REL_ "GenSigTimeoutTime" BU_SG_REL_ BCM SG_ 313 VZM_QBit_Fahrer_bremst 1000;
BA_REL_ "GenSigTimeoutTime" BU_SG_REL_ BCM SG_ 313 VMM_Notstopp_Status 1000;
BA_REL_ "GenSigTimeoutTime" BU_SG_REL_ BCM SG_ 313 VZM_Fahrer_bremst_deutlich 1000;
BA_REL_ "GenSigTimeoutTime" BU_SG_REL_ BCM SG_ 313 VMM_Inkonsistenz_VLK 1000;
BA_REL_ "GenSigTimeoutTime" BU_SG_REL_ BCM SG_ 313 HMS_parken_nicht_verfuegbar 1000;
BA_REL_ "GenSigTimeoutTime" BU_SG_REL_ BCM SG_ 313 HMS_Systemstatus 1000;
BA_REL_ "GenSigTimeoutTime" BU_SG_REL_ BCM SG_ 313 HMS_Stillstand 1000;
BA_REL_ "GenSigTimeoutTime" BU_SG_REL_ BCM SG_ 313 HMS_aktives_System 1000;
BA_REL_ "GenSigTimeoutTime" BU_SG_REL_ BCM SG_ 916 WBA_03_CRC 1600;
BA_REL_ "GenSigTimeoutTime" BU_SG_REL_ BCM SG_ 916 WBA_03_BZ 1600;
BA_REL_ "GenSigTimeoutTime" BU_SG_REL_ BCM SG_ 916 WBA_Fahrstufe_02 1600;
BA_REL_ "GenSigTimeoutTime" BU_SG_REL_ BCM SG_ 830 WFS_Transp_Mod_Unterbrechung_02 5000;
BA_REL_ "GenSigTimeoutTime" BU_SG_REL_ BCM SG_ 830 WFS_Verbau_Transp_Ant_02 5000;
BA_REL_ "GenSigTimeoutTime" BU_SG_REL_ BCM SG_ 830 WFS_Diag_LF_Aktiv_02 5000;
BA_REL_ "GenSigTimeoutTime" BU_SG_REL_ BCM SG_ 830 WFS_LF_aktiv_02 5000;
BA_REL_ "GenSigTimeoutTime" BU_SG_REL_ BCM SG_ 2589283611 WLC1_aktive_Spule 5000;
BA_REL_ "GenSigTimeoutTime" BU_SG_REL_ BCM SG_ 2589283611 WLC1_Fremdobjekt_erkannt 5000;
BA_REL_ "GenSigTimeoutTime" BU_SG_REL_ BCM SG_ 2589283611 WLC1_Objekt_erkannt 5000;
BA_REL_ "GenSigTimeoutTime" BU_SG_REL_ BCM SG_ 2589283611 WLC1_Receiver_erkannt 5000;
BA_REL_ "GenSigTimeoutTime" BU_SG_REL_ BCM SG_ 2589283611 WLC1_Receiver_voll_geladen 5000;
BA_REL_ "GenSigTimeoutTime" BU_SG_REL_ BCM SG_ 2463978688 zDML_Status 2000;
BA_REL_ "GenSigTimeoutTime" BU_SG_REL_ BCM SG_ 2463978854 DML_CrossingAssist_Available 2000;
BA_REL_ "GenSigTimeoutTime" BU_SG_REL_ BCM SG_ 2463978854 DML_HazardWarning_Available 2000;
BA_REL_ "GenSigTimeoutTime" BU_SG_REL_ BCM SG_ 2463978854 DML_LaneLight_Available 2000;
BA_REL_ "GenSigTimeoutTime" BU_SG_REL_ BCM SG_ 2463978854 DML_LaneDepartureWarn_Available 2000;
BA_REL_ "GenSigTimeoutTime" BU_SG_REL_ BCM SG_ 2463978854 DML_MarkingLight_Available 2000;
BA_REL_ "GenSigTimeoutTime" BU_SG_REL_ BCM SG_ 2463978854 DML_OrientationLight_Available 2000;
BA_REL_ "GenSigTimeoutTime" BU_SG_REL_ BCM SG_ 2463978854 DML_RescueLaneNotice_Available 2000;
BA_REL_ "GenSigTimeoutTime" BU_SG_REL_ BCM SG_ 2463978854 DML_ConstructionZone_Available 2000;
BA_REL_ "GenSigTimeoutTime" BU_SG_REL_ BCM SG_ 2463978854 DML_SafetyZone_Available 2000;
BA_REL_ "GenSigTimeoutTime" BU_SG_REL_ BCM SG_ 2463978854 DML_Indicator_Available 2000;
BA_REL_ "GenSigTimeoutTime" BU_SG_REL_ BCM SG_ 2463978854 DML_SideAssist_Available 2000;
BA_REL_ "GenSigTimeoutTime" BU_SG_REL_ BCM SG_ 2463978854 DML_SaftyDistance_Available 2000;
BA_REL_ "GenSigTimeoutTime" BU_SG_REL_ BCM SG_ 2463978854 DML_GhostDriverWarn_Available 2000;
BA_REL_ "GenSigTimeoutTime" BU_SG_REL_ BCM SG_ 2463978854 DML_IntelligentHB_Available 2000;
BA_REL_ "GenSigTimeoutTime" BU_SG_REL_ BCM SG_ 2463978854 DML_GlarefreeHB_Available 2000;
BA_REL_ "GenSigTimeoutTime" BU_SG_REL_ BCM SG_ 2463978854 DML_FuliValid 2000;
BA_REL_ "GenSigTimeoutTime" BU_SG_REL_ BCM SG_ 2589284130 ZR_ORU_Status 5000;
BA_REL_ "GenSigTimeoutTime" BU_SG_REL_ Gateway_Max SG_ 1716 VIN_01_MUX 2000;
BA_REL_ "GenSigTimeoutTime" BU_SG_REL_ Gateway_Max SG_ 1716 VIN_4 2000;
BA_REL_ "GenSigTimeoutTime" BU_SG_REL_ Gateway_Max SG_ 1716 VIN_11 2000;
BA_REL_ "GenSigTimeoutTime" BU_SG_REL_ Gateway_Max SG_ 1716 VIN_5 2000;
BA_REL_ "GenSigTimeoutTime" BU_SG_REL_ Gateway_Max SG_ 1716 VIN_12 2000;
BA_REL_ "GenSigTimeoutTime" BU_SG_REL_ Gateway_Max SG_ 1716 VIN_6 2000;
BA_REL_ "GenSigTimeoutTime" BU_SG_REL_ Gateway_Max SG_ 1716 VIN_13 2000;
BA_REL_ "GenSigTimeoutTime" BU_SG_REL_ Gateway_Max SG_ 1716 VIN_7 2000;
BA_REL_ "GenSigTimeoutTime" BU_SG_REL_ Gateway_Max SG_ 1716 VIN_14 2000;
BA_REL_ "GenSigTimeoutTime" BU_SG_REL_ Gateway_Max SG_ 1716 VIN_1 2000;
BA_REL_ "GenSigTimeoutTime" BU_SG_REL_ Gateway_Max SG_ 1716 VIN_8 2000;
BA_REL_ "GenSigTimeoutTime" BU_SG_REL_ Gateway_Max SG_ 1716 VIN_15 2000;
BA_REL_ "GenSigTimeoutTime" BU_SG_REL_ Gateway_Max SG_ 1716 VIN_2 2000;
BA_REL_ "GenSigTimeoutTime" BU_SG_REL_ Gateway_Max SG_ 1716 VIN_9 2000;
BA_REL_ "GenSigTimeoutTime" BU_SG_REL_ Gateway_Max SG_ 1716 VIN_16 2000;
BA_REL_ "GenSigTimeoutTime" BU_SG_REL_ Gateway_Max SG_ 1716 VIN_3 2000;
BA_REL_ "GenSigTimeoutTime" BU_SG_REL_ Gateway_Max SG_ 1716 VIN_10 2000;
BA_REL_ "GenSigTimeoutTime" BU_SG_REL_ Gateway_Max SG_ 1716 VIN_17 2000;
BA_REL_ "GenSigTimeoutTime" BU_SG_REL_ Gateway_Max SG_ 388 ZV_auf_FT 5000;
BA_REL_ "GenSigTimeoutTime" BU_SG_REL_ Gateway_Max SG_ 388 ZV_zu_FT 5000;
BA_REL_ "GenSigTimeoutTime" BU_SG_REL_ Gateway_Max SG_ 388 ZV_auf_BT 5000;
BA_REL_ "GenSigTimeoutTime" BU_SG_REL_ Gateway_Max SG_ 388 ZV_zu_BT 5000;
BA_REL_ "GenSigTimeoutTime" BU_SG_REL_ Gateway_Max SG_ 388 ZV_auf_Kessy 5000;
BA_REL_ "GenSigTimeoutTime" BU_SG_REL_ Gateway_Max SG_ 388 ZV_zu_Kessy 5000;
BA_REL_ "GenSigTimeoutTime" BU_SG_REL_ Gateway_Max SG_ 388 ZV_auf_Funk 5000;
BA_REL_ "GenSigTimeoutTime" BU_SG_REL_ Gateway_Max SG_ 388 ZV_zu_Funk 5000;
BA_REL_ "GenSigTimeoutTime" BU_SG_REL_ Gateway_Max SG_ 388 ZV_entriegeln_Anf 5000;
BA_REL_ "GenSigTimeoutTime" BU_SG_REL_ Gateway_Max SG_ 1411 ZV_verriegelt_extern_ist 2000;
BA_REL_ "GenSigTimeoutTime" BU_SG_REL_ Gateway_Max SG_ 1411 ZV_verriegelt_extern_soll 2000;
BA_REL_ "GenSigTimeoutTime" BU_SG_REL_ Gateway_Max SG_ 1411 ZV_FT_offen 2000;
BA_REL_ "GenSigTimeoutTime" BU_SG_REL_ Gateway_Max SG_ 1411 ZV_BT_offen 2000;
BA_REL_ "GenSigTimeoutTime" BU_SG_REL_ Gateway_Max SG_ 1411 ZV_HD_offen 2000;
BA_REL_ "GenSigTimeoutTime" BU_SG_REL_ Gateway_Max SG_ 1411 ZV_verriegelt_soll 2000;
BA_REL_ "GenSigTimeoutTime" BU_SG_REL_ TSGGen3_BFS SG_ 1716 VIN_01_MUX 2000;
BA_REL_ "GenSigTimeoutTime" BU_SG_REL_ TSGGen3_BFS SG_ 1716 VIN_4 2000;
BA_REL_ "GenSigTimeoutTime" BU_SG_REL_ TSGGen3_BFS SG_ 1716 VIN_11 2000;
BA_REL_ "GenSigTimeoutTime" BU_SG_REL_ TSGGen3_BFS SG_ 1716 VIN_5 2000;
BA_REL_ "GenSigTimeoutTime" BU_SG_REL_ TSGGen3_BFS SG_ 1716 VIN_12 2000;
BA_REL_ "GenSigTimeoutTime" BU_SG_REL_ TSGGen3_BFS SG_ 1716 VIN_6 2000;
BA_REL_ "GenSigTimeoutTime" BU_SG_REL_ TSGGen3_BFS SG_ 1716 VIN_13 2000;
BA_REL_ "GenSigTimeoutTime" BU_SG_REL_ TSGGen3_BFS SG_ 1716 VIN_7 2000;
BA_REL_ "GenSigTimeoutTime" BU_SG_REL_ TSGGen3_BFS SG_ 1716 VIN_14 2000;
BA_REL_ "GenSigTimeoutTime" BU_SG_REL_ TSGGen3_BFS SG_ 1716 VIN_1 2000;
BA_REL_ "GenSigTimeoutTime" BU_SG_REL_ TSGGen3_BFS SG_ 1716 VIN_8 2000;
BA_REL_ "GenSigTimeoutTime" BU_SG_REL_ TSGGen3_BFS SG_ 1716 VIN_15 2000;
BA_REL_ "GenSigTimeoutTime" BU_SG_REL_ TSGGen3_BFS SG_ 1716 VIN_2 2000;
BA_REL_ "GenSigTimeoutTime" BU_SG_REL_ TSGGen3_BFS SG_ 1716 VIN_9 2000;
BA_REL_ "GenSigTimeoutTime" BU_SG_REL_ TSGGen3_BFS SG_ 1716 VIN_16 2000;
BA_REL_ "GenSigTimeoutTime" BU_SG_REL_ TSGGen3_BFS SG_ 1716 VIN_3 2000;
BA_REL_ "GenSigTimeoutTime" BU_SG_REL_ TSGGen3_BFS SG_ 1716 VIN_10 2000;
BA_REL_ "GenSigTimeoutTime" BU_SG_REL_ TSGGen3_BFS SG_ 1716 VIN_17 2000;
BA_REL_ "GenSigTimeoutTime" BU_SG_REL_ TSGGen3_BFS SG_ 1702 Wischer_vorne_aktiv 5000;
BA_REL_ "GenSigTimeoutTime" BU_SG_REL_ TSGGen3_BFS SG_ 1702 Waschen_vorne_aktiv 5000;
BA_REL_ "GenSigTimeoutTime" BU_SG_REL_ TSGGen3_BFS SG_ 389 ZFH_BFS_ManHoch 500;
BA_REL_ "GenSigTimeoutTime" BU_SG_REL_ TSGGen3_BFS SG_ 389 ZFH_BFS_AutoHoch 500;
BA_REL_ "GenSigTimeoutTime" BU_SG_REL_ TSGGen3_BFS SG_ 389 ZFH_BFS_ManTief 500;
BA_REL_ "GenSigTimeoutTime" BU_SG_REL_ TSGGen3_BFS SG_ 389 ZFH_BFS_AutoTief 500;
BA_REL_ "GenSigTimeoutTime" BU_SG_REL_ TSGGen3_BFS SG_ 389 ZFH_HBFS_ManHoch 500;
BA_REL_ "GenSigTimeoutTime" BU_SG_REL_ TSGGen3_BFS SG_ 389 ZFH_HBFS_AutoHoch 500;
BA_REL_ "GenSigTimeoutTime" BU_SG_REL_ TSGGen3_BFS SG_ 389 ZFH_HBFS_ManTief 500;
BA_REL_ "GenSigTimeoutTime" BU_SG_REL_ TSGGen3_BFS SG_ 389 ZFH_HBFS_AutoTief 500;
BA_REL_ "GenSigTimeoutTime" BU_SG_REL_ TSGGen3_BFS SG_ 389 ZFH_zentral_zu 500;
BA_REL_ "GenSigTimeoutTime" BU_SG_REL_ TSGGen3_BFS SG_ 389 ZFH_zentral_auf 500;
BA_REL_ "GenSigTimeoutTime" BU_SG_REL_ TSGGen3_BFS SG_ 389 Krypt_Signatur 500;
BA_REL_ "GenSigTimeoutTime" BU_SG_REL_ TSGGen3_BFS SG_ 389 Krypt_Schluesselschalter_auf 500;
BA_REL_ "GenSigTimeoutTime" BU_SG_REL_ TSGGen3_BFS SG_ 389 Krypt_Schluesselschalter_zu 500;
BA_REL_ "GenSigTimeoutTime" BU_SG_REL_ TSGGen3_BFS SG_ 388 ZV_BT_verriegeln 5000;
BA_REL_ "GenSigTimeoutTime" BU_SG_REL_ TSGGen3_BFS SG_ 388 ZV_BT_entriegeln 5000;
BA_REL_ "GenSigTimeoutTime" BU_SG_REL_ TSGGen3_BFS SG_ 388 ZV_zentral_safen 5000;
BA_REL_ "GenSigTimeoutTime" BU_SG_REL_ TSGGen3_BFS SG_ 388 ZV_zentral_entsafen 5000;
BA_REL_ "GenSigTimeoutTime" BU_SG_REL_ TSGGen3_BFS SG_ 388 ZV_Spg_Anklappen 5000;
BA_REL_ "GenSigTimeoutTime" BU_SG_REL_ TSGGen3_BFS SG_ 388 ZV_Softtouch_betaetigt 5000;
BA_REL_ "GenSigTimeoutTime" BU_SG_REL_ TSGGen3_BFS SG_ 388 ZV_zu_Zeitl_Nachverr 5000;
BA_REL_ "GenSigTimeoutTime" BU_SG_REL_ TSGGen3_BFS SG_ 388 FH_BT_hoch 5000;
BA_REL_ "GenSigTimeoutTime" BU_SG_REL_ TSGGen3_BFS SG_ 388 FH_BT_tief 5000;
BA_REL_ "GenSigTimeoutTime" BU_SG_REL_ TSGGen3_BFS SG_ 388 FH_HBFS_hoch 5000;
BA_REL_ "GenSigTimeoutTime" BU_SG_REL_ TSGGen3_BFS SG_ 388 FH_HBFS_tief 5000;
BA_REL_ "GenSigTimeoutTime" BU_SG_REL_ TSGGen3_BFS SG_ 388 BCM_Spg_Synchron 5000;
BA_REL_ "GenSigTimeoutTime" BU_SG_REL_ TSGGen3_BFS SG_ 388 BCM_BF_Spg_Absenkung 5000;
BA_REL_ "GenSigTimeoutTime" BU_SG_REL_ TSGGen3_BFS SG_ 388 ZV_Signatur 5000;
BA_REL_ "GenSigTimeoutTime" BU_SG_REL_ TSGGen3_BFS SG_ 388 ZV_auto_Ansteuerung 5000;
BA_REL_ "GenSigTimeoutTime" BU_SG_REL_ TSGGen3_BFS SG_ 1411 BCM_FH_Freigabe 2000;
BA_REL_ "GenSigTimeoutTime" BU_SG_REL_ TSGGen3_BFS SG_ 1411 BCM_Komfortfkt_Freigabe 2000;
BA_REL_ "GenSigTimeoutTime" BU_SG_REL_ TSGGen3_BFS SG_ 1411 ZV_verriegelt_intern_ist 2000;
BA_REL_ "GenSigTimeoutTime" BU_SG_REL_ TSGGen3_BFS SG_ 1411 ZV_verriegelt_extern_ist 2000;
BA_REL_ "GenSigTimeoutTime" BU_SG_REL_ TSGGen3_BFS SG_ 1411 ZV_verriegelt_intern_soll 2000;
BA_REL_ "GenSigTimeoutTime" BU_SG_REL_ TSGGen3_BFS SG_ 1411 ZV_verriegelt_extern_soll 2000;
BA_REL_ "GenSigTimeoutTime" BU_SG_REL_ TSGGen3_BFS SG_ 1411 ZV_gesafet_extern_ist 2000;
BA_REL_ "GenSigTimeoutTime" BU_SG_REL_ TSGGen3_BFS SG_ 1411 ZV_gesafet_extern_soll 2000;
BA_REL_ "GenSigTimeoutTime" BU_SG_REL_ TSGGen3_BFS SG_ 1411 ZV_Einzeltuerentriegelung 2000;
BA_REL_ "GenSigTimeoutTime" BU_SG_REL_ TSGGen3_BFS SG_ 1411 ZV_HBFS_offen 2000;
BA_REL_ "GenSigTimeoutTime" BU_SG_REL_ TSGGen3_BFS SG_ 1411 ZV_Schluessel_Zugang 2000;
BA_REL_ "GenSigTimeoutTime" BU_SG_REL_ TSGGen3_BFS SG_ 1411 ZV_Tankklappe_offen 2000;
BA_REL_ "GenSigTimeoutTime" BU_SG_REL_ TSGGen3_FS SG_ 1716 VIN_01_MUX 2000;
BA_REL_ "GenSigTimeoutTime" BU_SG_REL_ TSGGen3_FS SG_ 1716 VIN_4 2000;
BA_REL_ "GenSigTimeoutTime" BU_SG_REL_ TSGGen3_FS SG_ 1716 VIN_11 2000;
BA_REL_ "GenSigTimeoutTime" BU_SG_REL_ TSGGen3_FS SG_ 1716 VIN_5 2000;
BA_REL_ "GenSigTimeoutTime" BU_SG_REL_ TSGGen3_FS SG_ 1716 VIN_12 2000;
BA_REL_ "GenSigTimeoutTime" BU_SG_REL_ TSGGen3_FS SG_ 1716 VIN_6 2000;
BA_REL_ "GenSigTimeoutTime" BU_SG_REL_ TSGGen3_FS SG_ 1716 VIN_13 2000;
BA_REL_ "GenSigTimeoutTime" BU_SG_REL_ TSGGen3_FS SG_ 1716 VIN_7 2000;
BA_REL_ "GenSigTimeoutTime" BU_SG_REL_ TSGGen3_FS SG_ 1716 VIN_14 2000;
BA_REL_ "GenSigTimeoutTime" BU_SG_REL_ TSGGen3_FS SG_ 1716 VIN_1 2000;
BA_REL_ "GenSigTimeoutTime" BU_SG_REL_ TSGGen3_FS SG_ 1716 VIN_8 2000;
BA_REL_ "GenSigTimeoutTime" BU_SG_REL_ TSGGen3_FS SG_ 1716 VIN_15 2000;
BA_REL_ "GenSigTimeoutTime" BU_SG_REL_ TSGGen3_FS SG_ 1716 VIN_2 2000;
BA_REL_ "GenSigTimeoutTime" BU_SG_REL_ TSGGen3_FS SG_ 1716 VIN_9 2000;
BA_REL_ "GenSigTimeoutTime" BU_SG_REL_ TSGGen3_FS SG_ 1716 VIN_16 2000;
BA_REL_ "GenSigTimeoutTime" BU_SG_REL_ TSGGen3_FS SG_ 1716 VIN_3 2000;
BA_REL_ "GenSigTimeoutTime" BU_SG_REL_ TSGGen3_FS SG_ 1716 VIN_10 2000;
BA_REL_ "GenSigTimeoutTime" BU_SG_REL_ TSGGen3_FS SG_ 1716 VIN_17 2000;
BA_REL_ "GenSigTimeoutTime" BU_SG_REL_ TSGGen3_FS SG_ 1702 Wischer_vorne_aktiv 5000;
BA_REL_ "GenSigTimeoutTime" BU_SG_REL_ TSGGen3_FS SG_ 1702 Waschen_vorne_aktiv 5000;
BA_REL_ "GenSigTimeoutTime" BU_SG_REL_ TSGGen3_FS SG_ 389 ZFH_FS_ManHoch 500;
BA_REL_ "GenSigTimeoutTime" BU_SG_REL_ TSGGen3_FS SG_ 389 ZFH_FS_AutoHoch 500;
BA_REL_ "GenSigTimeoutTime" BU_SG_REL_ TSGGen3_FS SG_ 389 ZFH_FS_ManTief 500;
BA_REL_ "GenSigTimeoutTime" BU_SG_REL_ TSGGen3_FS SG_ 389 ZFH_FS_AutoTief 500;
BA_REL_ "GenSigTimeoutTime" BU_SG_REL_ TSGGen3_FS SG_ 389 ZFH_zentral_zu 500;
BA_REL_ "GenSigTimeoutTime" BU_SG_REL_ TSGGen3_FS SG_ 389 ZFH_zentral_auf 500;
BA_REL_ "GenSigTimeoutTime" BU_SG_REL_ TSGGen3_FS SG_ 388 ZV_FT_verriegeln 5000;
BA_REL_ "GenSigTimeoutTime" BU_SG_REL_ TSGGen3_FS SG_ 388 ZV_FT_entriegeln 5000;
BA_REL_ "GenSigTimeoutTime" BU_SG_REL_ TSGGen3_FS SG_ 388 ZV_zentral_safen 5000;
BA_REL_ "GenSigTimeoutTime" BU_SG_REL_ TSGGen3_FS SG_ 388 ZV_zentral_entsafen 5000;
BA_REL_ "GenSigTimeoutTime" BU_SG_REL_ TSGGen3_FS SG_ 388 ZV_Spg_Anklappen 5000;
BA_REL_ "GenSigTimeoutTime" BU_SG_REL_ TSGGen3_FS SG_ 388 ZV_Softtouch_betaetigt 5000;
BA_REL_ "GenSigTimeoutTime" BU_SG_REL_ TSGGen3_FS SG_ 388 ZV_LED_Steuerung 5000;
BA_REL_ "GenSigTimeoutTime" BU_SG_REL_ TSGGen3_FS SG_ 388 ZV_LED_Uebernahme 5000;
BA_REL_ "GenSigTimeoutTime" BU_SG_REL_ TSGGen3_FS SG_ 388 ZV_zu_Zeitl_Nachverr 5000;
BA_REL_ "GenSigTimeoutTime" BU_SG_REL_ TSGGen3_FS SG_ 388 FH_FT_hoch 5000;
BA_REL_ "GenSigTimeoutTime" BU_SG_REL_ TSGGen3_FS SG_ 388 FH_FT_tief 5000;
BA_REL_ "GenSigTimeoutTime" BU_SG_REL_ TSGGen3_FS SG_ 388 FH_HFS_hoch 5000;
BA_REL_ "GenSigTimeoutTime" BU_SG_REL_ TSGGen3_FS SG_ 388 FH_HFS_tief 5000;
BA_REL_ "GenSigTimeoutTime" BU_SG_REL_ TSGGen3_FS SG_ 388 BCM_Spg_Synchron 5000;
BA_REL_ "GenSigTimeoutTime" BU_SG_REL_ TSGGen3_FS SG_ 388 BCM_BF_Spg_Absenkung 5000;
BA_REL_ "GenSigTimeoutTime" BU_SG_REL_ TSGGen3_FS SG_ 388 ZV_Signatur 5000;
BA_REL_ "GenSigTimeoutTime" BU_SG_REL_ TSGGen3_FS SG_ 388 ZV_auto_Ansteuerung 5000;
BA_REL_ "GenSigTimeoutTime" BU_SG_REL_ TSGGen3_FS SG_ 1411 BCM_FH_Freigabe 2000;
BA_REL_ "GenSigTimeoutTime" BU_SG_REL_ TSGGen3_FS SG_ 1411 BCM_Komfortfkt_Freigabe 2000;
BA_REL_ "GenSigTimeoutTime" BU_SG_REL_ TSGGen3_FS SG_ 1411 ZV_verriegelt_intern_ist 2000;
BA_REL_ "GenSigTimeoutTime" BU_SG_REL_ TSGGen3_FS SG_ 1411 ZV_verriegelt_extern_ist 2000;
BA_REL_ "GenSigTimeoutTime" BU_SG_REL_ TSGGen3_FS SG_ 1411 ZV_verriegelt_intern_soll 2000;
BA_REL_ "GenSigTimeoutTime" BU_SG_REL_ TSGGen3_FS SG_ 1411 ZV_verriegelt_extern_soll 2000;
BA_REL_ "GenSigTimeoutTime" BU_SG_REL_ TSGGen3_FS SG_ 1411 ZV_gesafet_extern_ist 2000;
BA_REL_ "GenSigTimeoutTime" BU_SG_REL_ TSGGen3_FS SG_ 1411 ZV_gesafet_extern_soll 2000;
BA_REL_ "GenSigTimeoutTime" BU_SG_REL_ TSGGen3_FS SG_ 1411 ZV_Einzeltuerentriegelung 2000;
BA_REL_ "GenSigTimeoutTime" BU_SG_REL_ TSGGen3_FS SG_ 1411 ZV_HFS_offen 2000;
BA_REL_ "GenSigTimeoutTime" BU_SG_REL_ TSGGen3_FS SG_ 1411 ZV_HBFS_offen 2000;
BA_REL_ "GenSigTimeoutTime" BU_SG_REL_ TSGGen3_FS SG_ 1411 IRUE_aktiv 2000;
BA_REL_ "GenSigTimeoutTime" BU_SG_REL_ TSGGen3_FS SG_ 1411 ZV_Schluessel_Zugang 2000;
BA_REL_ "GenSigTimeoutTime" BU_SG_REL_ TSGGen3_FS SG_ 1411 IRUE_Taster_Fkts_LED 2000;
BA_REL_ "GenSigTimeoutTime" BU_SG_REL_ TSGGen3_FS SG_ 1411 ZV_Tankklappe_offen 2000;
BA_REL_ "GenSigTimeoutTime" BU_SG_REL_ TSGGen3_FS SG_ 708 ZV_04_CRC 5000;
BA_REL_ "GenSigTimeoutTime" BU_SG_REL_ TSGGen3_FS SG_ 708 ZV_04_BZ 5000;
BA_REL_ "GenSigTimeoutTime" BU_SG_REL_ TSGGen3_FS SG_ 708 ZV_HFS_Status_KiSi 5000;
BA_REL_ "GenSigTimeoutTime" BU_SG_REL_ TSGGen3_FS SG_ 708 ZV_HBFS_Status_KiSi 5000;
BA_REL_ "GenSigTimeoutTime" BU_SG_REL_ TSGGen3_FS SG_ 708 ZV_Status_KiSi_CargoLock 5000;
BA_REL_ "GenSigTimeoutTime" BU_SG_REL_ TSGGen3_HBFS SG_ 1716 VIN_01_MUX 2000;
BA_REL_ "GenSigTimeoutTime" BU_SG_REL_ TSGGen3_HBFS SG_ 1716 VIN_4 2000;
BA_REL_ "GenSigTimeoutTime" BU_SG_REL_ TSGGen3_HBFS SG_ 1716 VIN_11 2000;
BA_REL_ "GenSigTimeoutTime" BU_SG_REL_ TSGGen3_HBFS SG_ 1716 VIN_5 2000;
BA_REL_ "GenSigTimeoutTime" BU_SG_REL_ TSGGen3_HBFS SG_ 1716 VIN_12 2000;
BA_REL_ "GenSigTimeoutTime" BU_SG_REL_ TSGGen3_HBFS SG_ 1716 VIN_6 2000;
BA_REL_ "GenSigTimeoutTime" BU_SG_REL_ TSGGen3_HBFS SG_ 1716 VIN_13 2000;
BA_REL_ "GenSigTimeoutTime" BU_SG_REL_ TSGGen3_HBFS SG_ 1716 VIN_7 2000;
BA_REL_ "GenSigTimeoutTime" BU_SG_REL_ TSGGen3_HBFS SG_ 1716 VIN_14 2000;
BA_REL_ "GenSigTimeoutTime" BU_SG_REL_ TSGGen3_HBFS SG_ 1716 VIN_1 2000;
BA_REL_ "GenSigTimeoutTime" BU_SG_REL_ TSGGen3_HBFS SG_ 1716 VIN_8 2000;
BA_REL_ "GenSigTimeoutTime" BU_SG_REL_ TSGGen3_HBFS SG_ 1716 VIN_15 2000;
BA_REL_ "GenSigTimeoutTime" BU_SG_REL_ TSGGen3_HBFS SG_ 1716 VIN_2 2000;
BA_REL_ "GenSigTimeoutTime" BU_SG_REL_ TSGGen3_HBFS SG_ 1716 VIN_9 2000;
BA_REL_ "GenSigTimeoutTime" BU_SG_REL_ TSGGen3_HBFS SG_ 1716 VIN_16 2000;
BA_REL_ "GenSigTimeoutTime" BU_SG_REL_ TSGGen3_HBFS SG_ 1716 VIN_3 2000;
BA_REL_ "GenSigTimeoutTime" BU_SG_REL_ TSGGen3_HBFS SG_ 1716 VIN_10 2000;
BA_REL_ "GenSigTimeoutTime" BU_SG_REL_ TSGGen3_HBFS SG_ 1716 VIN_17 2000;
BA_REL_ "GenSigTimeoutTime" BU_SG_REL_ TSGGen3_HBFS SG_ 1702 Wischer_vorne_aktiv 5000;
BA_REL_ "GenSigTimeoutTime" BU_SG_REL_ TSGGen3_HBFS SG_ 1702 Waschen_vorne_aktiv 5000;
BA_REL_ "GenSigTimeoutTime" BU_SG_REL_ TSGGen3_HBFS SG_ 389 ZFH_HBFS_ManHoch 500;
BA_REL_ "GenSigTimeoutTime" BU_SG_REL_ TSGGen3_HBFS SG_ 389 ZFH_HBFS_AutoHoch 500;
BA_REL_ "GenSigTimeoutTime" BU_SG_REL_ TSGGen3_HBFS SG_ 389 ZFH_HBFS_ManTief 500;
BA_REL_ "GenSigTimeoutTime" BU_SG_REL_ TSGGen3_HBFS SG_ 389 ZFH_HBFS_AutoTief 500;
BA_REL_ "GenSigTimeoutTime" BU_SG_REL_ TSGGen3_HBFS SG_ 389 ZFH_zentral_zu 500;
BA_REL_ "GenSigTimeoutTime" BU_SG_REL_ TSGGen3_HBFS SG_ 389 ZFH_zentral_auf 500;
BA_REL_ "GenSigTimeoutTime" BU_SG_REL_ TSGGen3_HBFS SG_ 389 Krypt_Signatur 500;
BA_REL_ "GenSigTimeoutTime" BU_SG_REL_ TSGGen3_HBFS SG_ 389 Krypt_Schluesselschalter_auf 500;
BA_REL_ "GenSigTimeoutTime" BU_SG_REL_ TSGGen3_HBFS SG_ 389 Krypt_Schluesselschalter_zu 500;
BA_REL_ "GenSigTimeoutTime" BU_SG_REL_ TSGGen3_HBFS SG_ 388 ZV_HBFS_verriegeln 5000;
BA_REL_ "GenSigTimeoutTime" BU_SG_REL_ TSGGen3_HBFS SG_ 388 ZV_HBFS_entriegeln 5000;
BA_REL_ "GenSigTimeoutTime" BU_SG_REL_ TSGGen3_HBFS SG_ 388 ZV_zentral_safen 5000;
BA_REL_ "GenSigTimeoutTime" BU_SG_REL_ TSGGen3_HBFS SG_ 388 ZV_zentral_entsafen 5000;
BA_REL_ "GenSigTimeoutTime" BU_SG_REL_ TSGGen3_HBFS SG_ 388 ZV_Softtouch_betaetigt 5000;
BA_REL_ "GenSigTimeoutTime" BU_SG_REL_ TSGGen3_HBFS SG_ 388 ZV_zu_Zeitl_Nachverr 5000;
BA_REL_ "GenSigTimeoutTime" BU_SG_REL_ TSGGen3_HBFS SG_ 388 FH_HBFS_hoch 5000;
BA_REL_ "GenSigTimeoutTime" BU_SG_REL_ TSGGen3_HBFS SG_ 388 FH_HBFS_tief 5000;
BA_REL_ "GenSigTimeoutTime" BU_SG_REL_ TSGGen3_HBFS SG_ 388 ZV_Signatur 5000;
BA_REL_ "GenSigTimeoutTime" BU_SG_REL_ TSGGen3_HBFS SG_ 388 ZV_auto_Ansteuerung 5000;
BA_REL_ "GenSigTimeoutTime" BU_SG_REL_ TSGGen3_HBFS SG_ 1411 BCM_FH_Freigabe 2000;
BA_REL_ "GenSigTimeoutTime" BU_SG_REL_ TSGGen3_HBFS SG_ 1411 BCM_Komfortfkt_Freigabe 2000;
BA_REL_ "GenSigTimeoutTime" BU_SG_REL_ TSGGen3_HBFS SG_ 1411 ZV_verriegelt_intern_ist 2000;
BA_REL_ "GenSigTimeoutTime" BU_SG_REL_ TSGGen3_HBFS SG_ 1411 ZV_verriegelt_extern_ist 2000;
BA_REL_ "GenSigTimeoutTime" BU_SG_REL_ TSGGen3_HBFS SG_ 1411 ZV_verriegelt_intern_soll 2000;
BA_REL_ "GenSigTimeoutTime" BU_SG_REL_ TSGGen3_HBFS SG_ 1411 ZV_verriegelt_extern_soll 2000;
BA_REL_ "GenSigTimeoutTime" BU_SG_REL_ TSGGen3_HBFS SG_ 1411 ZV_gesafet_extern_ist 2000;
BA_REL_ "GenSigTimeoutTime" BU_SG_REL_ TSGGen3_HBFS SG_ 1411 ZV_gesafet_extern_soll 2000;
BA_REL_ "GenSigTimeoutTime" BU_SG_REL_ TSGGen3_HBFS SG_ 1411 ZV_Einzeltuerentriegelung 2000;
BA_REL_ "GenSigTimeoutTime" BU_SG_REL_ TSGGen3_HBFS SG_ 1411 ZV_Schluessel_Zugang 2000;
BA_REL_ "GenSigTimeoutTime" BU_SG_REL_ TSGGen3_HBFS SG_ 1411 ZV_Tankklappe_offen 2000;
BA_REL_ "GenSigTimeoutTime" BU_SG_REL_ TSGGen3_HFS SG_ 1716 VIN_01_MUX 2000;
BA_REL_ "GenSigTimeoutTime" BU_SG_REL_ TSGGen3_HFS SG_ 1716 VIN_4 2000;
BA_REL_ "GenSigTimeoutTime" BU_SG_REL_ TSGGen3_HFS SG_ 1716 VIN_11 2000;
BA_REL_ "GenSigTimeoutTime" BU_SG_REL_ TSGGen3_HFS SG_ 1716 VIN_5 2000;
BA_REL_ "GenSigTimeoutTime" BU_SG_REL_ TSGGen3_HFS SG_ 1716 VIN_12 2000;
BA_REL_ "GenSigTimeoutTime" BU_SG_REL_ TSGGen3_HFS SG_ 1716 VIN_6 2000;
BA_REL_ "GenSigTimeoutTime" BU_SG_REL_ TSGGen3_HFS SG_ 1716 VIN_13 2000;
BA_REL_ "GenSigTimeoutTime" BU_SG_REL_ TSGGen3_HFS SG_ 1716 VIN_7 2000;
BA_REL_ "GenSigTimeoutTime" BU_SG_REL_ TSGGen3_HFS SG_ 1716 VIN_14 2000;
BA_REL_ "GenSigTimeoutTime" BU_SG_REL_ TSGGen3_HFS SG_ 1716 VIN_1 2000;
BA_REL_ "GenSigTimeoutTime" BU_SG_REL_ TSGGen3_HFS SG_ 1716 VIN_8 2000;
BA_REL_ "GenSigTimeoutTime" BU_SG_REL_ TSGGen3_HFS SG_ 1716 VIN_15 2000;
BA_REL_ "GenSigTimeoutTime" BU_SG_REL_ TSGGen3_HFS SG_ 1716 VIN_2 2000;
BA_REL_ "GenSigTimeoutTime" BU_SG_REL_ TSGGen3_HFS SG_ 1716 VIN_9 2000;
BA_REL_ "GenSigTimeoutTime" BU_SG_REL_ TSGGen3_HFS SG_ 1716 VIN_16 2000;
BA_REL_ "GenSigTimeoutTime" BU_SG_REL_ TSGGen3_HFS SG_ 1716 VIN_3 2000;
BA_REL_ "GenSigTimeoutTime" BU_SG_REL_ TSGGen3_HFS SG_ 1716 VIN_10 2000;
BA_REL_ "GenSigTimeoutTime" BU_SG_REL_ TSGGen3_HFS SG_ 1716 VIN_17 2000;
BA_REL_ "GenSigTimeoutTime" BU_SG_REL_ TSGGen3_HFS SG_ 1702 Wischer_vorne_aktiv 5000;
BA_REL_ "GenSigTimeoutTime" BU_SG_REL_ TSGGen3_HFS SG_ 1702 Waschen_vorne_aktiv 5000;
BA_REL_ "GenSigTimeoutTime" BU_SG_REL_ TSGGen3_HFS SG_ 389 ZFH_HFS_ManHoch 500;
BA_REL_ "GenSigTimeoutTime" BU_SG_REL_ TSGGen3_HFS SG_ 389 ZFH_HFS_AutoHoch 500;
BA_REL_ "GenSigTimeoutTime" BU_SG_REL_ TSGGen3_HFS SG_ 389 ZFH_HFS_ManTief 500;
BA_REL_ "GenSigTimeoutTime" BU_SG_REL_ TSGGen3_HFS SG_ 389 ZFH_HFS_AutoTief 500;
BA_REL_ "GenSigTimeoutTime" BU_SG_REL_ TSGGen3_HFS SG_ 389 ZFH_zentral_zu 500;
BA_REL_ "GenSigTimeoutTime" BU_SG_REL_ TSGGen3_HFS SG_ 389 ZFH_zentral_auf 500;
BA_REL_ "GenSigTimeoutTime" BU_SG_REL_ TSGGen3_HFS SG_ 389 Krypt_Signatur 500;
BA_REL_ "GenSigTimeoutTime" BU_SG_REL_ TSGGen3_HFS SG_ 389 Krypt_Schluesselschalter_auf 500;
BA_REL_ "GenSigTimeoutTime" BU_SG_REL_ TSGGen3_HFS SG_ 389 Krypt_Schluesselschalter_zu 500;
BA_REL_ "GenSigTimeoutTime" BU_SG_REL_ TSGGen3_HFS SG_ 388 ZV_HFS_verriegeln 5000;
BA_REL_ "GenSigTimeoutTime" BU_SG_REL_ TSGGen3_HFS SG_ 388 ZV_HFS_entriegeln 5000;
BA_REL_ "GenSigTimeoutTime" BU_SG_REL_ TSGGen3_HFS SG_ 388 ZV_zentral_safen 5000;
BA_REL_ "GenSigTimeoutTime" BU_SG_REL_ TSGGen3_HFS SG_ 388 ZV_zentral_entsafen 5000;
BA_REL_ "GenSigTimeoutTime" BU_SG_REL_ TSGGen3_HFS SG_ 388 ZV_Softtouch_betaetigt 5000;
BA_REL_ "GenSigTimeoutTime" BU_SG_REL_ TSGGen3_HFS SG_ 388 ZV_zu_Zeitl_Nachverr 5000;
BA_REL_ "GenSigTimeoutTime" BU_SG_REL_ TSGGen3_HFS SG_ 388 FH_HFS_hoch 5000;
BA_REL_ "GenSigTimeoutTime" BU_SG_REL_ TSGGen3_HFS SG_ 388 FH_HFS_tief 5000;
BA_REL_ "GenSigTimeoutTime" BU_SG_REL_ TSGGen3_HFS SG_ 388 ZV_Signatur 5000;
BA_REL_ "GenSigTimeoutTime" BU_SG_REL_ TSGGen3_HFS SG_ 388 ZV_auto_Ansteuerung 5000;
BA_REL_ "GenSigTimeoutTime" BU_SG_REL_ TSGGen3_HFS SG_ 1411 BCM_FH_Freigabe 2000;
BA_REL_ "GenSigTimeoutTime" BU_SG_REL_ TSGGen3_HFS SG_ 1411 BCM_Komfortfkt_Freigabe 2000;
BA_REL_ "GenSigTimeoutTime" BU_SG_REL_ TSGGen3_HFS SG_ 1411 ZV_verriegelt_intern_ist 2000;
BA_REL_ "GenSigTimeoutTime" BU_SG_REL_ TSGGen3_HFS SG_ 1411 ZV_verriegelt_extern_ist 2000;
BA_REL_ "GenSigTimeoutTime" BU_SG_REL_ TSGGen3_HFS SG_ 1411 ZV_verriegelt_intern_soll 2000;
BA_REL_ "GenSigTimeoutTime" BU_SG_REL_ TSGGen3_HFS SG_ 1411 ZV_verriegelt_extern_soll 2000;
BA_REL_ "GenSigTimeoutTime" BU_SG_REL_ TSGGen3_HFS SG_ 1411 ZV_gesafet_extern_ist 2000;
BA_REL_ "GenSigTimeoutTime" BU_SG_REL_ TSGGen3_HFS SG_ 1411 ZV_gesafet_extern_soll 2000;
BA_REL_ "GenSigTimeoutTime" BU_SG_REL_ TSGGen3_HFS SG_ 1411 ZV_Einzeltuerentriegelung 2000;
BA_REL_ "GenSigTimeoutTime" BU_SG_REL_ TSGGen3_HFS SG_ 1411 ZV_Schluessel_Zugang 2000;
BA_REL_ "GenSigTimeoutTime" BU_SG_REL_ TSGGen3_HFS SG_ 1411 ZV_Tankklappe_offen 2000;
BA_REL_ "GenSigTimeoutTime" BU_SG_REL_ WLC_01_CFD SG_ 1716 VIN_4 2000;
BA_REL_ "GenSigTimeoutTime" BU_SG_REL_ WLC_01_CFD SG_ 1716 VIN_11 2000;
BA_REL_ "GenSigTimeoutTime" BU_SG_REL_ WLC_01_CFD SG_ 1716 VIN_5 2000;
BA_REL_ "GenSigTimeoutTime" BU_SG_REL_ WLC_01_CFD SG_ 1716 VIN_12 2000;
BA_REL_ "GenSigTimeoutTime" BU_SG_REL_ WLC_01_CFD SG_ 1716 VIN_6 2000;
BA_REL_ "GenSigTimeoutTime" BU_SG_REL_ WLC_01_CFD SG_ 1716 VIN_13 2000;
BA_REL_ "GenSigTimeoutTime" BU_SG_REL_ WLC_01_CFD SG_ 1716 VIN_7 2000;
BA_REL_ "GenSigTimeoutTime" BU_SG_REL_ WLC_01_CFD SG_ 1716 VIN_14 2000;
BA_REL_ "GenSigTimeoutTime" BU_SG_REL_ WLC_01_CFD SG_ 1716 VIN_1 2000;
BA_REL_ "GenSigTimeoutTime" BU_SG_REL_ WLC_01_CFD SG_ 1716 VIN_8 2000;
BA_REL_ "GenSigTimeoutTime" BU_SG_REL_ WLC_01_CFD SG_ 1716 VIN_15 2000;
BA_REL_ "GenSigTimeoutTime" BU_SG_REL_ WLC_01_CFD SG_ 1716 VIN_2 2000;
BA_REL_ "GenSigTimeoutTime" BU_SG_REL_ WLC_01_CFD SG_ 1716 VIN_9 2000;
BA_REL_ "GenSigTimeoutTime" BU_SG_REL_ WLC_01_CFD SG_ 1716 VIN_16 2000;
BA_REL_ "GenSigTimeoutTime" BU_SG_REL_ WLC_01_CFD SG_ 1716 VIN_3 2000;
BA_REL_ "GenSigTimeoutTime" BU_SG_REL_ WLC_01_CFD SG_ 1716 VIN_10 2000;
BA_REL_ "GenSigTimeoutTime" BU_SG_REL_ WLC_01_CFD SG_ 1716 VIN_17 2000;
BA_REL_ "GenSigTimeoutTime" BU_SG_REL_ WLC_01_CFD SG_ 1140 WLC1_Systemzustand 5000;
BA_REL_ "GenSigTimeoutTime" BU_SG_REL_ WLC_01_CFD SG_ 1140 WLC2_Systemzustand 5000;
VAL_ 1057 VLK_Anforderung_HMS 0 "keine_Anforderung" 1 "halten" 2 "parken" 3 "halten_Standby" 4 "anfahren" 5 "Loesen_ueber_Rampe" 6 "Parken_mit_P" 7 "HMS_uebernehmen" ;
VAL_ 1057 VLK_autom_Absch_Signalisierung 0 "Init" 1 "Automatisierte_Abschaltung" ;
VAL_ 1057 VLK_VLW_Anf 0 "Init" 1 "VLW_angefordert" 2 "degradierte_VLW_FT_Fehler" 3 "reserved" ;
VAL_ 1057 VLK_Anforderung_Rollfaehigkeit 0 "Rollfaehigkeitsmode_inaktiv_Init" 1 "Rollfaehigkeitsmodus_aktiv" ;
VAL_ 1057 VLK_Parken_beibehalten_HMS 0 "Parken_nicht_beibehalten" 1 "Parken_beibehalten" 2 "Init" 3 "Fehler" ;
VAL_ 1057 VLK_Hinweis_Rollfaehigkeit 0 "Init_keinHinweis" 1 "Hinweis_ohne_Akustik" 2 "Hinweis_mit_Akustik" 3 "reserviert" ;
VAL_ 1057 VLK_Antriebsdeaktivierung 0 "Keine_Einschraenkung" 1 "Antrieb_deaktivieren" 3 "Fehler" ;
VAL_ 1057 VLK_Anf_Antrieb 0 "Init" 1 "Freigabe" 2 "VKM_Zustand_einfrieren" 3 "Zustartverbot_fuer_Fahrer" 5 "Startanforderung" 7 "Fehler" ;
VAL_ 1057 VLK_Hinweis_Weiterfahrt 0 "inaktiv" 1 "aktiv" ;
VAL_ 1057 VLK_Hinweis_Fehler_Gurt 0 "inaktiv" 1 "aktiv" ;
VAL_ 1057 VLK_Hinweis_Fehler_Sitz 0 "inaktiv" 1 "aktiv" ;
VAL_ 1057 VLK_Hinweis_Fehler_Tuer 0 "inaktiv" 1 "aktiv" ;
VAL_ 1057 VLK_Hinweis_dgr_VLW 0 "inaktiv" 1 "aktiv" ;
VAL_ 1057 VLK_Hinweis_KA_bevorstehend 0 "inaktiv" 1 "aktiv" ;
VAL_ 313 VZM_aktiver_Basisservice 0 "Keine_Aktivitaet" 1 "Bremsenkonditionierung" 2 "Bremsruck" 3 "Verzoegerungsregelung" 4 "Wegregelung" ;
VAL_ 313 VZM_Anhalteweg_nicht_verfuegbar 0 "verfuegbar" 1 "nicht_verfuegbar" ;
VAL_ 313 VZM_Fahrer_bremst 0 "Bremsdruckschwelle_nicht_ueberschritten" 1 "Bremsdruckschwelle_ueberschritten" ;
VAL_ 313 VZM_QBit_Fahrer_bremst 0 "gueltiger_Wert" 1 "Ersatz_Init_oder_Fehlerwert" ;
VAL_ 313 VMM_MKB_codiert 0 "MKB_nicht_codiert" 1 "MKB_codiert" ;
VAL_ 313 VMM_Inkonsistenz_EBKV 0 "konsistent" 1 "nicht_konsistent" ;
VAL_ 313 VMM_Notstopp_Status 0 "Init" 1 "verfuegbar" 2 "warten_auf_sekundaer_System" 3 "passiv_Ueberwachung" 4 "aktiv_ausgeloest" 7 "Fehler" ;
VAL_ 313 VZM_Warnruck_nicht_verfuegbar 0 "verfuegbar" 1 "nicht_verfuegbar" ;
VAL_ 313 VZM_Warnruckeln_nicht_verfuegbar 0 "verfuegbar" 1 "nicht_verfuegbar" ;
VAL_ 313 VZM_Bkd_nicht_verfuegbar 0 "verfuegbar" 1 "nicht_verfuegbar" ;
VAL_ 313 VMM_Bremslicht_defekt 0 "Bremslichter_nicht_defekt" 1 "Bremslichter_defekt" ;
VAL_ 313 VZM_Fahrer_bremst_deutlich 0 "Fahrer_bremst_nicht_deutlich" 1 "Fahrer_bremst_deutlich" ;
VAL_ 313 VZM_TSK_SRBM_Anf 0 "keine_Aktivitaet" 1 "Aktivitaet_durch_TSK" ;
VAL_ 313 VZM_TSK_SRBM_nicht_verfuegbar 0 "verfuegbar" 1 "nicht_verfuegbar" ;
VAL_ 313 VZM_Verz_Reg_aktiv 0 "keine_Aktivitaet" 2 "Aktivitaet_durch_AWV_PCF" 3 "Aktivitaet_durch_EA" 4 "Aktivitaet_durch_TSK" 5 "Aktivitaet_durch_RCTA" 6 "Aktivitaet_durch_ParkAssist" 7 "Aktivitaet_durch_ACC" 8 "Aktivitaet_durch_ARA" 9 "Aktivitaet_durch_NV" 10 "Aktivitaet_durch_KAS" 11 "Aktivitaet_durch_FAS_VK" 12 "Aktivitaet_durch_vESC" 13 "Aktivitaet_durch_KAM" 14 "Aktivitaet_durch_BRS_intern" 15 "Aktivitaet_durch_AEB" 16 "Aktivitaet_durch_MKB" ;
VAL_ 313 VZM_Verz_Reg_nicht_verfuegbar 0 "verfuegbar" 1 "nicht_verfuegbar" ;
VAL_ 313 VMM_Inkonsistenz_KAS 0 "konsistent" 1 "nicht_konsistent" ;
VAL_ 313 VMM_Bremslicht_unplausibel 0 "plausibel" 1 "unplausibel" ;
VAL_ 313 VMM_Inkonsistenz_ACC 0 "konsistent" 1 "nicht_konsistent" ;
VAL_ 313 VMM_Inkonsistenz_AWV_PCF 0 "konsistent" 1 "nicht_konsistent" ;
VAL_ 313 VMM_Inkonsistenz_ARA 0 "konsistent" 1 "nicht_konsistent" ;
VAL_ 313 VMM_Inkonsistenz_ParkAssist 0 "konsistent" 1 "nicht_konsistent" ;
VAL_ 313 VMM_Inkonsistenz_FAS_VK 0 "konsistent" 1 "nicht_konsistent" ;
VAL_ 313 VMM_Inkonsistenz_NV 0 "konsistent" 1 "nicht_konsistent" ;
VAL_ 313 VMM_Inkonsistenz_RCTA 0 "konsistent" 1 "nicht_konsistent" ;
VAL_ 313 VMM_Inkonsistenz_TSK 0 "konsistent" 1 "nicht_konsistent" ;
VAL_ 313 VMM_Inkonsistenz_MO 0 "konsistent" 1 "nicht_konsistent" ;
VAL_ 313 VMM_Inkonsistenz_AEB 0 "konsistent" 1 "nicht_konsistent" ;
VAL_ 313 VMM_Fahrer_Bremskraft_bestimmend 0 "Nicht_Bremskraft_bestimmend" 1 "Bremskraft_bestimmend" ;
VAL_ 313 VMM_Inkonsistenz_EA 0 "konsistent" 1 "nicht_konsistent" ;
VAL_ 313 VZM_Status_Wegregelung 0 "Inaktiv" 1 "Passiv" 2 "Aktiv" 3 "Passiv_Ueberwachend" ;
VAL_ 313 VZM_Verz_ASIL_Verfuegbarkeit 0 "Nicht_verfuegbar" 1 "Verfuegbar_ab_ASIL_QM" 2 "Verfuegbar_ab_ASIL_A" 3 "Verfuegbar_ab_ASIL_B" 4 "Verfuegbar_ab_ASIL_C" ;
VAL_ 313 VZM_aktives_System 0 "Kein_aktiver_Teilnehmer" 1 "VZM_intern" 2 "AWV_PCF" 3 "EA" 4 "TSK" 5 "RCTA" 6 "ParkAssist" 7 "ACC" 8 "ARA" 9 "NV" 10 "KAS" 11 "FAS_VK" 12 "vESC" 13 "KAM" 14 "reserviert" 15 "AEB" 16 "MKB" 17 "ECD" 18 "RHP" ;
VAL_ 313 VZM_Verz_Begrenzung 0 "keine_Begrenzung" 1 "Begrenzung_aktiv" ;
VAL_ 313 VZM_Systemstatus 0 "Initialisierung" 1 "Verfuegbar" 2 "Verfuegbar_eingeschr_Performance" 3 "Nicht_Verfuegbar" 4 "Fehler" 5 "Sonderbetriebsmodus" ;
VAL_ 313 VZM_SRBM_Soll 4094 "Init" 4095 "Fehler" ;
VAL_ 313 VZM_SRBM_Ist 4094 "Init" 4095 "Fehler" ;
VAL_ 313 VZM_SRBM_max_Gradient 126 "Init" 127 "Fehler" ;
VAL_ 313 VMM_Inkonsistenz_KAM 0 "konsistent" 1 "nicht_konsistent" ;
VAL_ 313 VMM_Inkonsistenz_RHP 0 "konsistent" 1 "nicht_konsistent" ;
VAL_ 313 HMS_P_beibehalten_GE 0 "P_nicht_beibehalten" 1 "P_beibehalten" 2 "Init" 3 "Fehler" ;
VAL_ 313 VZM_Unterdrueckung_Antriebsmom 0 "Pos_Antriebsmoment_moeglich" 1 "Pos_Antriebsmoment_unterdruecken" ;
VAL_ 313 VMM_Inkonsistenz_VLK 0 "konsistent" 1 "nicht_konsistent" ;
VAL_ 313 HMS_halten_nicht_verfuegbar_02 0 "verfuegbar" 1 "nicht_verfuegbar" 2 "verfuegbar_ohne_Anwesenheitserk" 3 "reserviert" ;
VAL_ 313 HMS_halten_nicht_verfuegbar 0 "verfuegbar" 1 "nicht_verfuegbar" ;
VAL_ 313 HMS_parken_nicht_verfuegbar 0 "verfuegbar" 1 "nicht_verfuegbar" ;
VAL_ 313 HMS_Anforderung_GE 0 "keine_Anforderung" 1 "P_einlegen" ;
VAL_ 313 HMS_Systemstatus 0 "keine_Funktion_aktiv" 1 "Halten_aktiv" 2 "Parken_angefordert" 3 "Parken_aktiv" 4 "Parken_beibehalten_aktiv" 5 "Anfahren_aktiv" 6 "Loeseanforderung_aktiv" 7 "Loeseanforderung_durch_Fahrer" 8 "Abrutschen_erkannt" 9 "Halten_Standby_aktiv" 10 "Anfahren_Standby_aktiv" 14 "Init" 15 "Fehler" ;
VAL_ 313 HMS_Stillstand 0 "kein_Stillstand" 1 "Stillstand_frueh" 2 "Stillstand" 6 "Init" 7 "Fehler" ;
VAL_ 313 HMS_aktives_System 0 "kein_System__Init_Fehler" 1 "Fahreranforderung_aktiv" 2 "HMS_intern_aktiv" 3 "ACC_aktiv" 4 "Autohold_aktiv" 5 "HHC_aktiv" 6 "HVLM_aktiv" 7 "Getriebe_aktiv" 8 "EBKV_aktiv" 9 "ParkAssist_aktiv" 10 "ARA_aktiv" 11 "HTO_aktiv" 12 "autonomous_Hold_aktiv" 13 "STA_aktiv" 14 "Motor_aktiv" 15 "EA_aktiv" 16 "VLK_aktiv" 17 "RHP_aktiv" 18 "ORU_aktiv" ;
VAL_ 313 VMM_Inkonsistenz_GE 0 "konsistent" 1 "nicht_konsistent" ;
VAL_ 313 VMM_Inkonsistenz_HVLM 0 "konsistent" 1 "nicht_konsistent" ;
VAL_ 313 HMS_Fehlerstatus 0 "kein_Fehler" 1 "Halten_nicht_moeglich" 2 "Sonderbetriebsmodus_aktiv" 3 "Systemeinschraenkung" 4 "Systemstoerung" ;
VAL_ 313 HMS_Index_Haltemoment 0 "Bremsmoment" 1 "Antriebsmoment" ;
VAL_ 313 HMS_Haltemoment 1022 "Init" 1023 "Fehler" ;
VAL_ 916 WBA_Fahrstufe_02 0 "Zwischenstellung_keine_Position" 1 "Position_P" 2 "Position_R" 3 "Position_N" 4 "Position_D" 5 "Position_S" 6 "Position_M_Tippfunktion" 7 "Kurzzeit_M" 8 "Position_E" 9 "Position_MS" 10 "Position_S_Plus" 11 "Position_MS_Plus" 12 "Position_Offroad" 13 "Position_B" 14 "Position_M_Plus" ;
VAL_ 916 WBA_ZielFahrstufe 0 "keine_Gangempfehlung_kein_Gang_eingelegt" 1 "Pfeil_nach_S" 2 "Pfeil_nach_D" 3 "Pfeil_nach_M" 4 "Pfeil_nach_E" ;
VAL_ 916 WBA_GE_Warnung_02 0 "keine_Anzeige" 1 "Fehlereskalationsstufe_I" 2 "Fehlereskalationsstufe_II" 3 "Weiterfahrt_nur_eingeschraenkt_moeglich__Kein_R_Gang" 4 "Getriebefehler_Weiterfahrt_nur_in_D_moeglich__P_bei_Motor_aus" 5 "Wegrollgefahr__P_nicht_moeglich" 6 "Paddlenotbetrieb_Schema+Warnung" 7 "Paddlenotbetrieb_Schema" 8 "Geschwindigkeitsbegrenzung_Notlauf" 9 "Fehlereskalationsst_o_Einschr" 10 "Fehlereskalationsstufe_v_Limit" 11 "Parksperre_Infostufe" 12 "Parksperre_Warnstufe_I" 13 "Parksperre_Warnstufe_II" ;
VAL_ 916 WBA_eing_Gang_02 0 "keine_Ganganzeige" 1 "Gang_1" 2 "Gang_2" 3 "Gang_3" 4 "Gang_4" 5 "Gang_5" 6 "Gang_6" 7 "Gang_7" 8 "Gang_8" 9 "Gang_9" 10 "Funktion_Ganganzeigeunterdrueckung" 11 "Gang_10" ;
VAL_ 916 WBA_GE_Texte 0 "keine_Anzeige" 1 "zum_Einlegen_einer_Fahrstufe_Fussbremse_betaetigen__ShiftLock_Information" 2 "zum_Einlegen_von_R_N_D_Fussbremse_betaetigen_und_Motor_starten" 3 "Wegrollgefahr_bitte_P_einlegen" 4 "Achtung_Zeitueberschreitung_P_wird_eingelegt" 5 "Wiederanmeldeprozedur_Bremse_betaetigen" 6 "P_nur_im_Stillstand_moeglich" 7 "Rennstart_aktiv" ;
VAL_ 916 WBA_Segeln_aktiv 0 "inaktiv" 1 "aktiv" ;
VAL_ 916 WBA_Schaltschema_02 0 "kein_Schaltschema" 1 "R_N_DS" 2 "R_N_ES" 3 "R_N_DB" 4 "R_N_D" 5 "R_N_SSplus" ;
VAL_ 916 WBA_Schaltschema_FS_inaktiv 0 "alle_Fahrstufen_aktiv" 1 "Fahrstufe_Rueckwaerts_inaktiv" 2 "nur_P_und_N_aktiv" 3 "alle_Fahrstufen_inaktiv" ;
VAL_ 916 WBA_GE_Zusatzwarnungen 0 "keine_Anzeige" 1 "Getriebeueberhitzung_Warnstufe_I" 2 "Getriebeueberhitzung_Warnstufe_II" 3 "Getriebefehler_Bitte_anhalten_und_P_einlegen" ;
VAL_ 916 GE_Sollgang 0 "keine_Empfehlung" 1 "Gang_1" 2 "Gang_2" 3 "Gang_3" 4 "Gang_4" 5 "Gang_5" 6 "Gang_6" 7 "Gang_7" 8 "Gang_8" 9 "Gang_9" 11 "Gang_10" ;
VAL_ 916 GE_Tipschaltempf_verfuegbar 0 "nicht_verfuegbar" 1 "verfuegbar" ;
VAL_ 916 WBA_GE_Texte_02 0 "Keine_Anzeige" 1 "Fahrtrichtungswechsel_nur_nach_Stillstandt" 2 "Ladestecker_gesteckt" 3 "zusaetzlicher_Service_erforderlich" 4 "eLaunch_Aktiv" 5 "eLaunch_nicht_moeglich" 6 "WH_S_nicht_moeglich_Offroad" 7 "WH_S_nicht_moeglich_RangeMode" ;
VAL_ 916 WBA_Schaltschema_Tippgasse 0 "keine_Tippgasse_vorhanden" 1 "Tippgasse_vorhanden" ;
VAL_ 916 WBA_Schaltschema_Fahreraktion 0 "keine_Fahreraktion" 1 "Fahreraktion" ;
VAL_ 916 WBA_Schaltschema_FS_vorwaerts 0 "FS1_aktiv__FS2_moeglich" 1 "FS2_aktiv__FS1_moeglich" 2 "FS1_aktiv__FS2_nicht_moeglich" 3 "FS2_aktiv__FS1_nicht_moeglich" ;
VAL_ 916 WBA_Shiftlock_Lampe 0 "Shiftlock_Lampe_AUS" 1 "Shiftlock_Lampe_EIN" ;
VAL_ 916 WBA_Anforderung_Akustik 0 "Akustik_aus" 1 "Akustik_ein" ;
VAL_ 916 WBA_Blinken 0 "kein_WBA_Blinken" 1 "WBA_Blinken" ;
VAL_ 916 GE_Wiederstart_Anz_Std 0 "keine_Anzeige" 1 "Standard_Wiederstartgrund" ;
VAL_ 916 GE_Stoppverbot_Anz_01 0 "keine_Anzeige" 1 "Temperaturbedingung" ;
VAL_ 916 GE_Stoppverbot_Anz_02 0 "keine_Anzeige" 1 "Drucksensorausfall" ;
VAL_ 916 GE_Stoppverbot_Anz_03 0 "keine_Anzeige" 1 "Grundeinstellung" ;
VAL_ 916 GE_Stoppverbot_Anz_04 0 "keine_Anzeige" 1 "Demontagestellung" ;
VAL_ 916 GE_Stoppverbot_Anz_05 0 "keine_Anzeige" 1 "Eingeschraenkte_Fahrfunktion_Notlauf_Liegenbleiber" ;
VAL_ 916 GE_Stoppverbot_Anz_06 0 "keine_Anzeige" 1 "Stoppverbot_ueber_Applikation" ;
VAL_ 916 GE_Stoppverbot_Anz_07 0 "keine_Anzeige" 1 "Schaltung_aktiv" ;
VAL_ 916 GE_Stoppverbot_Anz_Std 0 "keine_Anzeige" 1 "Standard_Stoppvetogrund" ;
VAL_ 1361 WFS_Schluessel_Fahrberecht 0 "kein authorisierter Schluessel erkannt" 1 "aktive_Funkschluessel_Nr_01" 2 "aktive_Funkschluessel_Nr_02" 3 "aktive_Funkschluessel_Nr_03" 4 "aktive_Funkschluessel_Nr_04" 5 "aktive_Funkschluessel_Nr_05" 6 "aktive_Funkschluessel_Nr_06" 7 "aktive_Funkschluessel_Nr_07" 8 "aktive_Funkschluessel_Nr_08" 9 "ungueltig_09" 10 "ungueltig_10" 11 "ungueltig_11" 12 "ungueltig_12" 13 "ungueltig_13" 14 "ungueltig_14" 15 "digitaler_Schluessel_aktiv" ;
VAL_ 1361 WFS_Verbauinfo_ELV 0 "ELV_nicht_verbaut" 1 "ELV_verbaut" ;
VAL_ 1361 WFS_ID_Geb_autorisiert 0 "Schluessel_nicht_authorisiert" 1 "Schluessel_authorisiert" ;
VAL_ 1361 WFS_ID_Geb_autorisiert_in_Kl15 0 "nicht_authorisiert_in_Kl15" 1 "authorisiert_in_Kl15" ;
VAL_ 1361 WFS_ID_Geb_steckt 0 "kein_Schluessel_im_Zuendschloss" 1 " Schluessel steckt im Zuendschloss" ;
VAL_ 1361 WFS_Safe 0 "Init" 1 "WFS nicht deaktiviert" ;
VAL_ 1361 WFS_LZ 0 "nicht def." 1 "LZ 1" 2 "LZ 2" 3 "LZ 3" ;
VAL_ 1361 WFS_ELV_authorisiert 0 "ELV_nicht_authorisiert" 1 "ELV_authorisiert" ;
VAL_ 1361 WFS_LF_Aktiv 0 "Funktempfang_nicht_aktiv" 1 "LF_Funkempfang_aktiv" ;
VAL_ 1361 WFS_Betrieb_Lesespule 0 "keine_Schluesselkomm_Lesespule" 1 "Schluesselkomm_Lesespule" ;
VAL_ 1361 WFS_Klemmenfreigabe 0 "keine_Freigabe" 1 "Freigabe" ;
VAL_ 1361 WFS_Fahrerhinweise 0 "Keine_Anzeigeanforderung" 1 "Schuessel_Auth_niO" 2 "Notlauf_aktiv" 3 "Schluessel_Kessy_nicht_gefunden" ;
VAL_ 1361 WFS_Parken_Status 0 "Limitierung_inaktiv" 1 "Limitierung_aktiv" 2 "Abbruch" ;
VAL_ 830 WFS_Transp_Mod_Unterbrechung_02 0 "kein_Uebergang" 1 "Uebergang_erkannt" ;
VAL_ 830 WFS_Verbau_Transp_Ant_02 0 "inaktiv" 1 "aktiv" ;
VAL_ 830 WFS_Diag_LF_Aktiv_02 0 "inaktiv" 1 "aktiv" ;
VAL_ 830 WFS_LF_aktiv_02 0 "Feld_inaktiv" 1 "Feld_aktiv" ;
VAL_ 1702 Wischer_vorne_aktiv 0 "Init" 1 "Wischer_vorne_laeuft" ;
VAL_ 1702 Waschen_vorne_aktiv 0 "inaktiv" 1 "Waschen_aktiv" ;
VAL_ 1702 Wischer_vorne_Normal 1 "Wischer Front normal aktiv" ;
VAL_ 1702 Wischer_vorne_Schnell 1 "Wischer vorne schnell aktiv" ;
VAL_ 1702 Wischer_vorne_Parklage 0 "Wischer_Front_nicht_in_Parklage" 1 "Wischer_Front_in_Parklage__Initialzustand" ;
VAL_ 1702 WWSs_01_alt 0 "aktuell" 1 "veraltet" ;
VAL_ 1702 Wischer_vorne_defekt 0 "Init" 1 "Wischer vorne defekt" ;
VAL_ 1702 Wischer_vorne_blockiert 1 "Wischer vorne blockiert" ;
VAL_ 1702 Wischer1_Wischgeschwindigkeit 0 "0 U/min" 62 "Init" 63 "Fehler" ;
VAL_ 1702 BCM1_SRA_aktiv 0 "nicht aktiv" 1 "aktiv" ;
VAL_ 1702 Heckwischer_Anforderung 0 "Aus" 1 "Ein" ;
VAL_ 1702 Wischer_Anzeigetext 0 "keine_Anzeige" 1 "Hinweis_Service_Position" 2 "void" 3 "void" ;
VAL_ 1702 Wischer_WH_Typ 0 "Lenkstockschalter_0_Int_Stufen" 1 "Lenkstockschalter_2_Int_Stufen" 2 "Lenkstockschalter_4_Int_Stufen" ;
VAL_ 1702 Wischer_WH_PopUp_Anf 0 "keine_Anzeige" 1 "Intervallstufe_1_aktiv" 2 "Intervallstufe_2_aktiv" 3 "Intervallstufe_3_aktiv" 4 "Intervallstufe_4_aktiv" 5 "Regensensorstufe_1_aktiv" 6 "Regensensorstufe_2_aktiv" 7 "Regensensorstufe_3_aktiv" 8 "Regensensorstufe_4_aktiv" 9 "Wischerstufe_1_aktiv" 10 "Wischerstufe_2_aktiv" 11 "Tippwischen_aktiv" 12 "Heckwischen_aktiv" ;
VAL_ 2589283611 WLC1_Fehler 0 "kein_Fehler" 1 "WLC_Kompensor_Kurzschluss" 2 "WLC_Kompensor_Unterbrechung" 4 "WLC_Antenne_Kurzschluss" 8 "WLC_Antenne_Unterbrechung" 16 "Kompensor_keine_Versorgung" 32 "Kompensor_defekt" 64 "WLC_defekt" ;
VAL_ 2589283611 WLC1_Fremdobjekt_erkannt 0 "no_Foreign_object" 1 "Foreign_object_detected" ;
VAL_ 2589283611 WLC1_Objekt_erkannt 0 "no_Device_in_Tray" 1 "non_WLC_Device_in_Tray" ;
VAL_ 2589283611 WLC1_Receiver_erkannt 0 "no_Device_in_tray" 1 "WLC_Device_in_tray" ;
VAL_ 2589283611 WLC1_Receiver_voll_geladen 0 "WLC_not_fully_charged" 1 "WLC_Device_fully_charged" ;
VAL_ 2527679836 WLC1_ChargingStatus 0 "no_device_in_tray" 1 "no_wlc_device_in_tray" 2 "wlc_device_in_tray" 3 "wlc_charging_active" 4 "wlc_device_fully_charged" 5 "foreign_object_detected" 6 "nfc_card_and_wlc_device_detected" ;
VAL_ 2527679836 WLC1_UsedChargingStandard 0 "charging_not_active" 1 "qi" 2 "qi_fast_charge" 3 "samsung_fast_charge" 4 "apple_fast_charge" 5 "reduced_power_nfc_card_detected" ;
VAL_ 2527679837 WLC2_ChargingStatus 0 "no_device_in_tray" 1 "no_wlc_device_in_tray" 2 "wlc_device_in_tray" 3 "wlc_charging_active" 4 "wlc_device_fully_charged" 5 "foreign_object_detected" 6 "nfc_card_and_wlc_device_detected" ;
VAL_ 2527679837 WLC2_UsedChargingStandard 0 "charging_not_active" 1 "qi" 2 "qi_fast_charge" 3 "samsung_fast_charge" 4 "apple_fast_charge" 5 "reduced_power_nfc_card_detected" ;
VAL_ 2463978688 zDML_L_Abblendl_2_Def 0 "iO" 1 "Fehler" ;
VAL_ 2463978688 zDML_R_Abblendl_2_Def 0 "iO" 1 "Fehler" ;
VAL_ 2463978688 DML_Fehlermeldung_Anf 0 "Fehlermeldung_nicht_angefordert" 1 "Fehlermeldung_angefordert" ;
VAL_ 2463978688 DML_Fernlichtlampe_Anf 0 "Fernlichtlampe_nicht_angefordert" 1 "Fernlichtlampe_angefordert" ;
VAL_ 2463978688 DML_EcoModus 0 "kein_EcoModus" 1 "Eco_Stufe_1" 2 "Eco_Stufe_2" 3 "Eco_Stufe_3" ;
VAL_ 2463978688 DMD_Soll_TempMode_L 0 "kein_Derating" 1 "Soll_Derating_90_100" 2 "Soll_Derating_80_20" 3 "Soll_Derating_70_30" 4 "Soll_Derating_60_40" 5 "Soll_Derating_50_50" ;
VAL_ 2463978688 DMD_Soll_TempMode_R 0 "kein_Derating" 1 "Soll_Derating_90_100" 2 "Soll_Derating_80_20" 3 "Soll_Derating_70_30" 4 "Soll_Derating_60_40" 5 "Soll_Derating_50_50" ;
VAL_ 2463978688 zDML_Video_Fehler 0 "kein_Fehler" 1 "Fehler" ;
VAL_ 2463978688 zDML_SG_Defekt 0 "kein_Fehler" 1 "Fehler" ;
VAL_ 2463978688 zDML_Speicher_Fehler 0 "kein_Fehler" 1 "Fehler" ;
VAL_ 2463978688 zDML_Versorgung_Fehler 0 "kein_Fehler" 1 "Fehler" ;
VAL_ 2463978688 zDML_GMSL_R_Fehler 0 "kein_Fehler" 1 "Fehler" ;
VAL_ 2463978688 zDML_GMSL_L_Fehler 0 "kein_Fehler" 1 "Fehler" ;
VAL_ 2463978688 zDML_ETH_Timeout 0 "kein_Fehler" 1 "Fehler" ;
VAL_ 2463978688 zDML_ETH_Fehler 0 "kein_Fehler" 1 "Fehler" ;
VAL_ 2463978688 zDML_Fokus 0 "alle_LEDs" 1 "nur_eine_LED" ;
VAL_ 2463978688 zDML_Video_Anf 0 "nicht_angefordert" 1 "angefordert" ;
VAL_ 2463978688 zDML_Status 0 "Init" 1 "Standby" 2 "aktiv" 3 "Sleep" 4 "aCH_oder_aLH" 5 "Stellgliedtest" 6 "Failsafe" 7 "Fehler" ;
VAL_ 2463978854 DML_HMI_FCN_CROSSINGLI_AVAILABLE 0 "not_available" 1 "available" ;
VAL_ 2463978854 DML_HMI_FCN_HAZARDWARN_AVAILABLE 0 "not_available" 1 "available" ;
VAL_ 2463978854 DML_HMI_FCN_LANELIGHT_AVAILABLE 0 "not_available" 1 "available" ;
VAL_ 2463978854 DML_HMI_FCN_LANLEAVELI_AVAILABLE 0 "not_available" 1 "available" ;
VAL_ 2463978854 DML_HMI_FCN_MALI_AVAILABLE 0 "not_available" 1 "available" ;
VAL_ 2463978854 DML_HMI_FCN_ORLI_AVAILABLE 0 "not_available" 1 "available" ;
VAL_ 2463978854 DML_HMI_FCN_RESALLEYHI_AVAILABLE 0 "not_available" 1 "available" ;
VAL_ 2463978854 DML_HMI_FCN_ROADWORKLI_AVAILABLE 0 "not_available" 1 "available" ;
VAL_ 2463978854 DML_HMI_FCN_SAFETYZONE_AVAILABLE 0 "not_available" 1 "available" ;
VAL_ 2463978854 DML_HMI_FCN_TURNLIGHPR_AVAILABLE 0 "not_available" 1 "available" ;
VAL_ 2463978854 DML_CrossingAssist_Available 0 "not_available" 1 "available" ;
VAL_ 2463978854 DML_HazardWarning_Available 0 "not_available" 1 "available" ;
VAL_ 2463978854 DML_LaneLight_Available 0 "not_available" 1 "available" ;
VAL_ 2463978854 DML_LaneDepartureWarn_Available 0 "not_available" 1 "available" ;
VAL_ 2463978854 DML_MarkingLight_Available 0 "not_available" 1 "available" ;
VAL_ 2463978854 DML_OrientationLight_Available 0 "not_available" 1 "available" ;
VAL_ 2463978854 DML_RescueLaneNotice_Available 0 "not_available" 1 "available" ;
VAL_ 2463978854 DML_ConstructionZone_Available 0 "not_available" 1 "available" ;
VAL_ 2463978854 DML_SafetyZone_Available 0 "not_available" 1 "available" ;
VAL_ 2463978854 DML_Indicator_Available 0 "not_available" 1 "available" ;
VAL_ 2463978854 DML_SideAssist_Available 0 "not_available" 1 "available" ;
VAL_ 2463978854 DML_SaftyDistance_Available 0 "not_available" 1 "available" ;
VAL_ 2463978854 DML_GhostDriverWarn_Available 0 "not_available" 1 "available" ;
VAL_ 2463978854 DML_IntelligentHB_Available 0 "not_available" 1 "available" ;
VAL_ 2463978854 DML_GlarefreeHB_Available 0 "not_available" 1 "available" ;
VAL_ 2463978854 DML_FuliValid 0 "invalid" 1 "valid" ;
VAL_ 1140 ZR_State_DU_1 0 "Disp_Off" 1 "Disp_On" 2 "LowPow" ;
VAL_ 1140 ZR_State_DU_2 0 "Disp_Off" 1 "Disp_On" 2 "LowPow" ;
VAL_ 1140 ZR_State_DU_3 0 "Disp_Off" 1 "Disp_On" 2 "LowPow" ;
VAL_ 1140 ZR_WecktGesp 0 "entsperrt" 1 "gesperrt" ;
VAL_ 1140 MMI_State 0 "MMI_OFF" 1 "MMI_IOC" 2 "MMI_STDBY" 3 "MMI_ON" 4 "MMI_STDBY_PWR_SAVE" 5 "MMI_STDBY_RESTR" 6 "MMI_ON_DIAG" 7 "MMI_ON_TEL" 8 "MMI_ON_SWDL" 9 "MMI_ON_CUST_SWDL" 10 "MMI_STDBY_PWR_SAVE_1" 11 "MMI_STDBY_PWR_SAVE_2" 12 "MMI_STANDBY_CUST_SWDL" 13 "MMI_ONLINE_IOC" 14 "MMI_ONLINE" 15 "MMI_PHONE_IOC" 16 "MMI_PHONE" 17 "MMI_RTC" 18 "MMI_DCI" ;
VAL_ 1140 ZR_DimOffs_DU_1 14 "Init" ;
VAL_ 1140 ZR_DimOffs_DU_2 14 "Init" ;
VAL_ 1140 ZR_DimOffs_DU_3 14 "Init" ;
VAL_ 1140 SI_ICAN 0 "keine_Busruhe" 1 "Busruhe" ;
VAL_ 1140 ZR_Lenkerposition 0 "links" 1 "rechts" ;
VAL_ 1140 WLC1_Systemzustand 0 "Wireless_Charger_off" 1 "InitWert_Wireless_Charger_on" ;
VAL_ 1140 WLC2_Systemzustand 0 "Wireless_Charger_off" 1 "InitWert_Wireless_Charger_on" ;
VAL_ 1140 DI_Screendesign 0 "Automatisch" 1 "Tag" 2 "Nacht" 6 "Init" 7 "Fehler" ;
VAL_ 1140 ZR_State_DU_4 0 "Disp_Off" 1 "Disp_On" 2 "LowPow" ;
VAL_ 1140 ZR_DimOffs_DU_4 14 "Init" ;
VAL_ 2589284130 ZR_ORU_Status 0 "Init" 1 "Idle" 2 "SW_Update_available" 3 "SW_Update_running" 4 "SW_Update_successful" 5 "SW_Update_failure" ;
VAL_ 389 ZFH_FS_ManHoch 0 "Keine_Verfahranforderung" 1 "Manueller_Hochlauf" ;
VAL_ 389 ZFH_FS_AutoHoch 0 "Keine_Verfahranforderung" 1 "Automatischer_Hochlauf" ;
VAL_ 389 ZFH_FS_ManTief 0 "Keine_Verfahranforderung" 1 "Manueller_Tieflauf" ;
VAL_ 389 ZFH_FS_AutoTief 0 "Keine_Verfahranforderung" 1 "Automatischer_Tieflauf" ;
VAL_ 389 ZFH_BFS_ManHoch 0 "Keine_Verfahranforderung" 1 "Manueller_Hochlauf" ;
VAL_ 389 ZFH_BFS_AutoHoch 0 "Keine_Verfahranforderung" 1 "Automatischer_Hochlauf" ;
VAL_ 389 ZFH_BFS_ManTief 0 "Keine_Verfahranforderung" 1 "Manueller_Tieflauf" ;
VAL_ 389 ZFH_BFS_AutoTief 0 "Keine_Verfahranforderung" 1 "Automatischer_Tieflauf" ;
VAL_ 389 ZFH_HFS_ManHoch 0 "Keine_Verfahranforderung" 1 "Manueller_Hochlauf" ;
VAL_ 389 ZFH_HFS_AutoHoch 0 "Keine_Verfahranforderung" 1 "Automatischer_Hochlauf" ;
VAL_ 389 ZFH_HFS_ManTief 0 "Keine_Verfahranforderung" 1 "Manueller_Tieflauf" ;
VAL_ 389 ZFH_HFS_AutoTief 0 "Keine_Verfahranforderung" 1 "Automatischer_Tieflauf" ;
VAL_ 389 ZFH_HBFS_ManHoch 0 "Keine_Verfahranforderung" 1 "Manueller_Hochlauf" ;
VAL_ 389 ZFH_HBFS_AutoHoch 0 "Keine_Verfahranforderung" 1 "Automatischer_Hochlauf" ;
VAL_ 389 ZFH_HBFS_ManTief 0 "Keine_Verfahranforderung" 1 "Manueller_Tieflauf" ;
VAL_ 389 ZFH_HBFS_AutoTief 0 "Keine_Verfahranforderung" 1 "Automatischer_Tieflauf" ;
VAL_ 389 ZFH_zentral_zu 0 "Init" 1 "Fensterheber_zentral_zu" ;
VAL_ 389 ZFH_zentral_auf 0 "Init" 1 "Fensterheber_zentral_auf" ;
VAL_ 389 Krypt_Schluesselschalter_auf 0 "Schluesselschalter_nicht_betaetigt" 1 "Schluesselschalter_betaetigt" ;
VAL_ 389 Krypt_Schluesselschalter_zu 0 "Schluesselschalter_nicht_betaeti" 1 "Schluesselschalter_betaetigt" ;
VAL_ 388 ZV_FT_verriegeln 0 "FT_nicht_verriegeln" 1 "FT_verriegeln" ;
VAL_ 388 ZV_FT_entriegeln 0 "FT_nicht_entriegeln" 1 "FT_entriegeln" ;
VAL_ 388 ZV_BT_verriegeln 0 "BT_nicht_verriegeln" 1 "BT_verriegeln" ;
VAL_ 388 ZV_BT_entriegeln 0 "BT_nicht_entriegeln" 1 "BT_ist_zu_entriegeln" ;
VAL_ 388 ZV_HFS_verriegeln 0 "inaktiv" 1 "aktiv" ;
VAL_ 388 ZV_HFS_entriegeln 0 "inaktiv" 1 "aktiv" ;
VAL_ 388 ZV_HBFS_verriegeln 0 "inaktiv" 1 "aktiv" ;
VAL_ 388 ZV_HBFS_entriegeln 0 "inaktiv" 1 "aktiv" ;
VAL_ 388 ZV_zentral_safen 0 "nicht_safen" 1 "Befehl_zentral_safen" ;
VAL_ 388 ZV_zentral_entsafen 0 "Init" 1 "Befehl_zentral_entsafen" ;
VAL_ 388 ZV_Spg_Anklappen 0 "inaktiv" 1 "aktiv" ;
VAL_ 388 ZV_Softtouch_betaetigt 0 "Softtouch_nicht_betaetigt" 1 "Softtouch_betaetigt" ;
VAL_ 388 ZV_LED_Steuerung 0 "LED_aus" 1 "LED_ein" ;
VAL_ 388 ZV_LED_Uebernahme 0 "Init" 1 "TSG_uebernimmt_LED_Steuerung" ;
VAL_ 388 ZV_auf_FT 0 "nicht_betaetigt" 1 "betaetigt" ;
VAL_ 388 ZV_zu_FT 0 "nicht_betaetigt" 1 "betaetigt" ;
VAL_ 388 ZV_auf_BT 0 "nicht_betaetigt" 1 "betaetigt" ;
VAL_ 388 ZV_zu_BT 0 "nicht_betaetigt" 1 "betaetigt" ;
VAL_ 388 ZV_auf_Funk 0 "nicht_betaetigt" 1 "betaetigt" ;
VAL_ 388 ZV_zu_Funk 0 "nicht_betaetigt" 1 "betaetigt" ;
VAL_ 388 VIP_Sensor_betaetigt 0 "Heckentr_VIP_nicht_angefordert" 1 "Heckentr_VIP_angefordert" ;
VAL_ 388 VIP_Freigabe 0 "keine_Freigabe" 1 "Freigabe" ;
VAL_ 388 ZV_zu_Zeitl_Nachverr 0 "Init" 1 "Nachverriegeln" ;
VAL_ 388 ZV_HSK_entriegeln 0 "Handschuhkasten nicht entriegeln" 1 "Handschuhkasten entriegeln" ;
VAL_ 388 ZV_HSK_verriegeln 0 "Handschuhkasten nicht verriegeln" 1 "Handschuhkasten_verriegelt" ;
VAL_ 388 ZV_Verdeck_zu 0 "inaktiv" 1 "aktiv" ;
VAL_ 388 ZV_Verdeck_auf 0 "inaktiv" 1 "aktiv" ;
VAL_ 388 FH_FT_hoch 0 "keine_Anforderung" 1 "FT_hoch" ;
VAL_ 388 FH_FT_tief 0 "keine_Anforderung" 1 "FT_tief" ;
VAL_ 388 FH_BT_hoch 0 "keine_Anforderung" 1 "BT_hoch" ;
VAL_ 388 FH_BT_tief 0 "keine_Anforderung" 1 "BT_tief" ;
VAL_ 388 FH_HFS_hoch 0 "inaktiv" 1 "aktiv" ;
VAL_ 388 FH_HFS_tief 0 "inaktiv" 1 "aktiv" ;
VAL_ 388 FH_HBFS_hoch 0 "inaktiv" 1 "aktiv" ;
VAL_ 388 FH_HBFS_tief 0 "inaktiv" 1 "aktiv" ;
VAL_ 388 BCM_Spg_Synchron 0 "inaktiv" 1 "aktiv" ;
VAL_ 388 BCM_BF_Spg_Absenkung 0 "inaktiv" 1 "aktiv" ;
VAL_ 388 ZV_entriegeln_Anf 0 "nicht_betaetigt" 1 "betaetigt" ;
VAL_ 388 ZV_auto_Ansteuerung 0 "Kein_Autolock_Unlock" 1 "Autolock_Unlock" ;
VAL_ 1411 ZV_verriegeln_Anf 0 "nicht_betaetigt" 1 "betaetigt" ;
VAL_ 1411 ZV_STSG_HFS_Anf 0 "keine_Anforderung" 1 "Anforderung" ;
VAL_ 1411 ZV_STSG_HBFS_Anf 0 "keine_Anforderung" 1 "Anforderung" ;
VAL_ 1411 ZV_Anf_Challenge_Auth 0 "nicht_aktiv" 1 "aktiv" ;
VAL_ 1411 ZV_STSG_Crashzustand 0 "inaktiv" 1 "aktiv" ;
VAL_ 1411 ZV_STSG_eKiSi_defekt 0 "inaktiv" 1 "aktiv" ;
VAL_ 1411 ZV_eRWK_Umfeld_Pruefung 0 "nicht_aktiv" 1 "aktiv" ;
VAL_ 1411 VIP_Sensor_STSG_HFS_betaetigt 0 "keine_VIP_Anforderung_STSG_HFS" 1 "VIP_Anforderung_STSG_HFS" ;
VAL_ 1411 VIP_Sensor_STSG_HBFS_betaetigt 0 "keine_VIP_Anforderung_STSG_HBFS" 1 "VIP_Anforderung_STSG_HBFS" ;
VAL_ 1411 BCM_FH_Freigabe 1 "Funktionsfreigabe Fensterheber" ;
VAL_ 1411 BCM_Komfortfkt_Freigabe 0 "Komfortfunktion gesperrt" 1 "globale Freigabe der Komfortfunktion erteilt" ;
VAL_ 1411 BCM_HSK_Freigabe 0 "erlauben" 1 "sperren" ;
VAL_ 1411 BCM_Verdeck_Freigabe 0 "Verdeckbetrieb nicht erlaubt" 1 "Verdeckbetrieb erlaubt" ;
VAL_ 1411 ZV_verriegelt_intern_ist 1 "Fahrzeug innen verriegelt; Istzustand" ;
VAL_ 1411 ZV_verriegelt_extern_ist 1 "Fahrzeug_aussen_verriegelt_Istzustand" ;
VAL_ 1411 ZV_verriegelt_intern_soll 1 "Fahrzeug verriegelt intern; Sollzusstand" ;
VAL_ 1411 ZV_verriegelt_extern_soll 1 "Fahrzeug verriegelt extern; Sollzusstand" ;
VAL_ 1411 ZV_gesafet_extern_ist 1 "Fahrzeug aussen gesafet; Istzustand" ;
VAL_ 1411 ZV_gesafet_extern_soll 1 "Fahrzeug_aussen_gesafet_Sollzustand" ;
VAL_ 1411 ZV_Einzeltuerentriegelung 1 "Fahrzeug an Einzeltuer entriegelt" ;
VAL_ 1411 ZV_Heckeinzelentriegelung 1 "Heckdeckeleinzelentriegelung" ;
VAL_ 1411 ZV_FT_offen 0 "FT_geschlossen" 1 "FT_geoeffnet" ;
VAL_ 1411 ZV_BT_offen 0 "BT_geschlossen" 1 "BT_geoeffnet" ;
VAL_ 1411 ZV_HFS_offen 0 "geschlossen" 1 "offen" ;
VAL_ 1411 ZV_HBFS_offen 0 "geschlossen" 1 "offen" ;
VAL_ 1411 ZV_HD_offen 1 "Heckdeckel_auf" ;
VAL_ 1411 ZV_HS_offen 0 "Heckscheibe_geschlossen" 1 "Heckscheibe auf" ;
VAL_ 1411 IRUE_aktiv 0 "unscharf" 1 "scharf" ;
VAL_ 1411 DWA_aktiv 0 "unscharf" 1 "scharf" ;
VAL_ 1411 HD_Hauptraste 0 "geschlossen" 1 "offen" ;
VAL_ 1411 HD_Vorraste 0 "geschlossen" 1 "offen" ;
VAL_ 1411 FFB_HDF_Taste 0 "Taste_nicht_betaetigt" 1 "HDF_Taste_am_Funkschluessel_betaetigt" ;
VAL_ 1411 FFB_Panik_Taste 0 "Taste_nicht_betaetigt" 1 "Panik_Taste_am_Funkschluessel_betaetigt" ;
VAL_ 1411 FFB_Auf_Taste 0 "Taste_nicht_betaetigt" 1 "Oeffnentaste_betaetigt" ;
VAL_ 1411 FFB_Zu_Taste 0 "Taste_nicht_betaetigt" 1 "Zu_Taste_am_Funkschluessel_betaetigt" ;
VAL_ 1411 FFB_CarFinder 0 "nicht aktiv" 1 "aktiv" ;
VAL_ 1411 FFB_Komfortoeffnen 0 "kein_Komfortoeffnen_empfangen" 1 "Komfortoeffnen ueber Funk empfangen" ;
VAL_ 1411 FFB_Komfortschliessen 0 "kein_Komfortschliessen_empfangen" 1 "Komfortschliessen ueber Funk empfangen" ;
VAL_ 1411 FBS_IDG_in_Reichweite 0 "ausser_Reichweite_bzw_nicht_ermittelbar" 1 "innerhalb_Reichweite" ;
VAL_ 1411 ZV_Schluessel_Zugang 0 "kein_auth_Schluessel_erkannt" 1 "aktive_Funkschluessel_Nr_01" 2 "aktive_Funkschluessel_Nr_02" 3 "aktive_Funkschluessel_Nr_03" 4 "aktive_Funkschluessel_Nr_04" 5 "aktive_Funkschluessel_Nr_05" 6 "aktive_Funkschluessel_Nr_06" 7 "aktive_Funkschluessel_Nr_07" 8 "aktive_Funkschluessel_Nr_08" 9 "aktive_SmartDevice_Nr_09" 10 "ungueltig_10" 11 "ungueltig_11" 12 "ungueltig_12" 13 "ungueltig_13" 14 "ungueltig_14" 15 "ungueltig_15" ;
VAL_ 1411 ZV_SafeFunktion_aktiv 0 "inaktiv" 1 "aktiv" ;
VAL_ 1411 FBS_Warn_Schluessel_Batt 0 "i.O." 1 "defekt" ;
VAL_ 1411 ZV_Oeffnungsmodus 0 "globale_Oeffnung" 1 "ZV_mit_Einzeltuerentr" 2 "ZV_individuell_selektiv" 3 "ZV_seitenselektiv" ;
VAL_ 1411 HFS_verriegelt 0 "nicht_verriegelt" 1 "verriegelt" ;
VAL_ 1411 HFS_gesafet 0 "nicht_gesafet" 1 "gesafet" ;
VAL_ 1411 HBFS_verriegelt 0 "nicht_verriegelt" 1 "verriegelt" ;
VAL_ 1411 HBFS_gesafet 0 "nicht_gesafet" 1 "gesafet" ;
VAL_ 1411 ZV_ist_Zustand_verfuegbar 0 "nicht_verfuegbar" 1 "verfuegbar_alle_TSGs_am_Bus" ;
VAL_ 1411 IRUE_Taster_Fkts_LED 0 "LED_aus" 1 "LED_ein" ;
VAL_ 1411 ZV_Tankklappe_offen 0 "Tankklappe_geschlossen" 1 "Tankklappe_offen" ;
VAL_ 1411 ZV_Rollo_auf 0 "inaktiv" 1 "aktiv" ;
VAL_ 1411 ZV_Rollo_zu 0 "inaktiv" 1 "aktiv" ;
VAL_ 1411 ZV_SAD_auf 0 "inaktiv" 1 "aktiv" ;
VAL_ 1411 ZV_SAD_zu 0 "inaktiv" 1 "aktiv" ;
VAL_ 1411 BCM_Tankklappensteller_Fehler 0 "kein_Fehler" 1 "Fehler" ;
VAL_ 1411 ZV_verriegelt_soll 0 "Init" 1 "nicht_verriegelt" 2 "verriegelt" ;
VAL_ 708 ZV_HFS_Status_KiSi 0 "inaktiv" 1 "aktiv" ;
VAL_ 708 ZV_HFS_TAG_betaetigt 0 "nicht_betaetigt" 1 "betaetigt" ;
VAL_ 708 ZV_HFS_TIG_oeffnen_betaetigt 0 "nicht_betaetigt" 1 "betaetigt" ;
VAL_ 708 ZV_HFS_TIG_schliessen_betaetigt 0 "nicht_betaetigt" 1 "betaetigt" ;
VAL_ 708 ZV_HBFS_Status_KiSi 0 "inaktiv" 1 "aktiv" ;
VAL_ 708 ZV_HBFS_TAG_betaetigt 0 "nicht_betaetigt" 1 "betaetigt" ;
VAL_ 708 ZV_HBFS_TIG_oeffnen_betaetigt 0 "nicht_betaetigt" 1 "betaetigt" ;
VAL_ 708 ZV_HBFS_TIG_schliessen_betaetigt 0 "nicht_betaetigt" 1 "betaetigt" ;
VAL_ 708 ZV_Hupe_Takt 0 "Horn_aus" 1 "Horn_an" ;
VAL_ 708 ZV_Hupe_Anf 0 "Keine_Anforderung" 1 "Anforderung" ;
VAL_ 708 ZV_Status_Cargolock 0 "nicht_aktiv" 1 "aktiv" ;
VAL_ 708 ZV_HW_TKL_mot_verr 0 "nicht_aktiv" 1 "aktiv" ;
VAL_ 708 ZV_HW_TKL_mot_entr 0 "nicht_aktiv" 1 "aktiv" ;
VAL_ 708 ZV_Status_KiSi_CargoLock 0 "inaktiv" 1 "KiSi_aktiv" 2 "CargoLock_aktiv" 3 "KiSi_gesperrt" 7 "Fehler" ;
VAL_ 708 ZV_Laderaumabd_elektr_aktiviert 0 "inaktiv" 1 "aktiv" ;
VAL_ 708 ZV_Einfachhorn_Takt 0 "Horn_aus" 1 "Horn_an" ;
VAL_ 708 ZV_Einfachhorn_Anf 0 "Keine_Anforderung" 1 "Anforderung" ;
VAL_ 708 ZV_DWA_Einfachhorn_Takt 0 "Horn_aus" 1 "Horn_an" ;
VAL_ 708 ZV_DWA_Einfachhorn_Anf 0 "Keine_Anforderung" 1 "Anforderung" ;
VAL_ 708 UHF_FFB_Funkschluesseltyp 0 "kein_Funk" 1 "Funk_315MHz_Japan_2_Kanalig" 2 "Funk_434MHz_RdW_NAR_2_Kanalig" 3 "Funk_434MHz_Suedkorea_1_Kanalig" ;
VAL_ 708 UHF_FFB_SKC_anlernen 0 "nicht_aktiv" 1 "aktiv" ;
VAL_ 708 ZV_HW_Motor_Safe_Hinten 0 "Schloss_nicht_ansteuern" 1 "Schloss_ansteuern" ;
VAL_ 708 ZV_HW_Motor_Lock_HK 0 "Schloss_nicht_ansteuern" 1 "Schloss_ansteuern" ;
